VERSION ""

NS_ :

BS_:

BU_: Airbag Allrad EPS Teves_MK60_ESP LWS LWR Teves_MK70_MABS Waehlhebel EPB TRW_ESP ACC_Radar AFS Magne_Ride RKA_Plus Selespeed Waehlhebel_Sele PDC_PLA Lenkhilfe_APA VAQ Daempfer Hybrid_BMS Hybrid_PWR Hybrid_DQ200 EKlimakomp SWA HCA ACC_Lidar Lenkhilfe_ZF_3G FLA AG6 DQ Hybrid_MSG Diesel Otto Gateway_PQ35_A Gateway_PQ46_A Vector_XXX Fzg_CAN

BO_ 1192 mBremse_5: 8 Teves_MK60_ESP
 SG_ BR5_Giergeschw : 0|14@1+ (0.01,0) [0|100] "°/s"  EPB,ACC_Radar,AFS,Magne_Ride,RKA_Plus,Daempfer,HCA,SWA,PDC_PLA,Allrad,ACC_Lidar,FLA
 SG_ BR5_Bremsdruck : 16|12@1+ (0.1,0) [0|409.4] "bar"  DQ,EPB,ACC_Radar,Magne_Ride,Daempfer,Hybrid_DQ200,HCA,ACC_Lidar,PDC_PLA,Diesel,Otto
 SG_ BR5_Sign_Druck : 31|1@1+ (1,0) [0|1] ""  DQ,EPB,ACC_Radar,Magne_Ride,Daempfer,Hybrid_DQ200,HCA,ACC_Lidar,Diesel,Otto
 SG_ BR5_Vorzeichen : 15|1@1+ (1,0) [0|1] ""  EPB,ACC_Radar,AFS,Magne_Ride,RKA_Plus,Daempfer,HCA,SWA,PDC_PLA,Allrad,ACC_Lidar,FLA
 SG_ BR5_Sta_Gierrate : 14|1@1+ (1,0) [0|1] ""  EPB,ACC_Radar,AFS,Magne_Ride,RKA_Plus,Daempfer,HCA,SWA,PDC_PLA,Allrad,ACC_Lidar,FLA
 SG_ BR5_Stillstand : 28|1@1+ (1,0) [0|1] ""  EPB,ACC_Radar,Magne_Ride,Daempfer,HCA,ACC_Lidar
 SG_ BR5_Sta_Druck : 30|1@1+ (1,0) [0|1] ""  EPB,ACC_Radar,Daempfer,HCA,ACC_Lidar
 SG_ BR5_Zaehler : 52|4@1+ (1,0) [0|15] ""  EPB,ACC_Radar,Magne_Ride,Daempfer,HCA,SWA,PDC_PLA,ACC_Lidar
 SG_ BR5_TolAbgl_VR : 32|8@1+ (0.048828125,-6.201171875) [-6.201171875|6.15234375] "%"  ACC_Lidar,HCA,Daempfer,ACC_Radar,EPB
 SG_ BR5_Anhi_akt : 41|1@1+ (1,0) [0|1] ""  EPB,ACC_Radar,Daempfer,HCA,ACC_Lidar
 SG_ BR5_Checksumme : 56|8@1+ (1,0) [0|255] ""  EPB,ACC_Radar,Magne_Ride,Daempfer,HCA,SWA,ACC_Lidar
 SG_ BR5_Druckgueltig : 29|1@1+ (1,0) [0|1] ""  DQ,EPB,ACC_Radar,Magne_Ride,Daempfer,Hybrid_DQ200,HCA,ACC_Lidar,PDC_PLA,Otto,Diesel
 SG_ BR5_ECD_Lampe : 51|1@1+ (1,0) [0|1] ""  ACC_Lidar,HCA,Daempfer,ACC_Radar,EPB
 SG_ BR5_AWV2_Bremsruck : 46|1@1+ (1,0) [0|1] ""  EPB,ACC_Radar,Daempfer,HCA,ACC_Lidar
 SG_ BR5_Anhi_Sta : 40|1@1+ (1,0) [0|1] ""  EPB,ACC_Radar,Daempfer,HCA,ACC_Lidar
 SG_ BR5_Temperatur : 48|3@1+ (125,125) [125|1000] "°"  ACC_Lidar,HCA,Daempfer,ACC_Radar,EPB
 SG_ BR5_v_Ueberw : 42|1@1+ (1,0) [0|1] ""  ACC_Lidar,HCA,Daempfer,ACC_Radar,EPB
 SG_ BR5_AnhStabAktiv : 43|1@1+ (1,0) [0|1] ""  Gateway_PQ46_A,EPB,ACC_Radar,Gateway_PQ35_A,Daempfer,HCA,ACC_Lidar
 SG_ BR5_Notbremsung : 44|1@1+ (1,0) [0|1] ""  Gateway_PQ46_A,EPB,ACC_Radar,Gateway_PQ35_A,Daempfer,HCA,ACC_Lidar
 SG_ BR5_AWV2_Fehler : 47|1@1+ (1,0) [0|1] ""  EPB,ACC_Radar,Daempfer,HCA,ACC_Lidar
 SG_ BR5_ECD_Rueckfall : 45|1@1+ (1,0) [0|1] ""  ACC_Lidar,HCA,Daempfer,ACC_Radar,EPB

BO_ 672 mBremse_4: 8 Teves_MK60_ESP
 SG_ BR4_Vorgabe_Hi m1 : 8|8@1+ (0.7874015748,-100) [0|100] "%"  Gateway_PQ46_A,Gateway_PQ35_A
 SG_ BR4_Einheit M : 16|2@1+ (1,0) [0|1] ""  Gateway_PQ46_A,Allrad,Gateway_PQ35_A,VAQ
 SG_ BR4_Vorgabe_Mi m1 : 0|8@1+ (0.7874015748,-100) [0|100] "%"  Gateway_PQ46_A,Gateway_PQ35_A
 SG_ BR4_Abschaltung_HL : 22|1@1+ (1,0) [0|1] ""  Gateway_PQ46_A,Gateway_PQ35_A
 SG_ BR4_Vorgabe_Mi_ m0 : 0|8@1+ (7,-896) [-896|882] "Nm"  Gateway_PQ46_A,Allrad,Gateway_PQ35_A
 SG_ BR4_Abschaltung_HR : 23|1@1+ (1,0) [0|1] ""  Gateway_PQ46_A,Gateway_PQ35_A
 SG_ BR4_Abschaltung_VL : 20|1@1+ (1,0) [0|1] ""  Gateway_PQ46_A,Gateway_PQ35_A
 SG_ BR4_Abschaltung_VR : 21|1@1+ (1,0) [0|1] ""  Gateway_PQ46_A,Gateway_PQ35_A
 SG_ BR4_Lampe_RKA : 24|1@1+ (1,0) [0|1] ""  Gateway_PQ46_A,Gateway_PQ35_A
 SG_ BR4_Summer_RKA : 25|1@1+ (1,0) [0|1] ""  Gateway_PQ46_A,Gateway_PQ35_A
 SG_ BR4_Unterdruck : 32|8@1+ (4,0) [0|1016] "mbar"  AG6,Gateway_PQ46_A,Otto,Gateway_PQ35_A,Hybrid_MSG
 SG_ BR4_Status_ESP : 40|4@1+ (1,0) [0|15] ""  Gateway_PQ46_A,Gateway_PQ35_A,VAQ
 SG_ BR4_Checksum : 56|8@1+ (1,0) [0|255] ""  Gateway_PQ46_A,Gateway_PQ35_A,VAQ
 SG_ BR4_Reserve2 : 26|6@1+ (1,0) [0|63] ""  Gateway_PQ46_A,Gateway_PQ35_A
 SG_ BR4_Zaehler : 52|4@1+ (1,0) [0|15] ""  Gateway_PQ46_A,Gateway_PQ35_A,VAQ
 SG_ BR4_Schwelle : 18|2@1+ (1,0) [0|3] ""  AG6,Gateway_PQ46_A,Otto,Gateway_PQ35_A,Hybrid_MSG
 SG_ BR4_res_42 : 44|4@1+ (1,0) [0|15] ""  Gateway_PQ46_A,Gateway_PQ35_A
 SG_ BR4_res_48 : 48|4@1+ (1,0) [0|15] ""  Gateway_PQ46_A,Gateway_PQ35_A
 SG_ BR4_Vorgabe_Min m2 : 8|8@1+ (10,0) [0|2540] "Nm"  Gateway_PQ46_A,Gateway_PQ35_A,VAQ
 SG_ BR4_Vorgabe_Max m2 : 0|8@1+ (10,0) [0|2540] "Nm"  Gateway_PQ46_A,Gateway_PQ35_A,VAQ

BO_ 428 mBremse_8: 8 Teves_MK60_ESP
 SG_ BR8_Laengsbeschl : 48|10@1+ (0.03125,-16) [-15.96875|15.9375] "m/s²"  AG6,Diesel,DQ,EPB,ACC_Radar,PDC_PLA,Hybrid_DQ200,Gateway_PQ35_A,ACC_Lidar,Otto
 SG_ BR8_Checksumme : 0|8@1+ (1,0) [0|255] ""  AG6,Diesel,DQ,EPB,ACC_Radar,PDC_PLA,Hybrid_DQ200,Gateway_PQ35_A,ACC_Lidar
 SG_ BR8_Sta_Br_Druck : 15|1@1+ (1,0) [0|1] ""  Diesel,EPB,ACC_Radar,Gateway_PQ35_A,ACC_Lidar
 SG_ BR8_QB_LBeschl : 42|1@1+ (1,0) [0|1] ""  EPB,ACC_Radar,PDC_PLA,Gateway_PQ35_A,ACC_Lidar,Otto,Diesel
 SG_ BR8_Istbeschl : 32|9@1+ (0.02,-7.22) [-7.22|2.98] "m/s²"  Diesel,Otto,EPB,ACC_Radar,Gateway_PQ35_A,ACC_Lidar
 SG_ BR8_Zaehler : 8|4@1+ (1,0) [0|15] ""  AG6,Diesel,EPB,ACC_Radar,PDC_PLA,Gateway_PQ35_A,ACC_Lidar
 SG_ BR8_Check_EPB : 63|1@1+ (1,0) [0|1] ""  EPB,ACC_Radar,Gateway_PQ35_A,ACC_Lidar
 SG_ BR8_TolAbgl_HL : 16|8@1+ (0.048828125,-6.201171875) [-6.201171875|6.15234375] "%"  Gateway_PQ35_A,ACC_Lidar,ACC_Radar,EPB
 SG_ BR8_TolAbgl_HR : 24|8@1+ (0.048828125,-6.201171875) [-6.201171875|6.15234375] "%"  Gateway_PQ35_A,ACC_Lidar,ACC_Radar,EPB
 SG_ BR8_Sta_ADR_BR : 58|1@1+ (1,0) [0|1] ""  Diesel,Otto,EPB,ACC_Radar,Gateway_PQ35_A,ACC_Lidar
 SG_ BR8_Sta_Br_temp : 14|1@1+ (1,0) [0|1] ""  Diesel,EPB,ACC_Radar,Gateway_PQ35_A,ACC_Lidar
 SG_ BR8_Quattro : 59|1@1+ (1,0) [0|1] ""  Gateway_PQ35_A,ACC_Lidar,ACC_Radar,EPB
 SG_ BR8_Sta_ACC_Anf : 12|1@1+ (1,0) [0|1] ""  Diesel,Otto,EPB,ACC_Radar,Gateway_PQ35_A,ACC_Lidar
 SG_ BR8_Verz_EPB_akt : 13|1@1+ (1,0) [0|1] ""  Diesel,EPB,ACC_Radar,Gateway_PQ35_A,ACC_Lidar
 SG_ BR8_aktBrSyst : 45|1@1+ (1,0) [0|1] ""  Diesel,Otto,EPB,ACC_Radar,Gateway_PQ35_A,ACC_Lidar
 SG_ BR8_Sta_VerzReg : 60|1@1+ (1,0) [0|1] ""  Diesel,EPB,ACC_Radar,Gateway_PQ35_A,ACC_Lidar
 SG_ BR8_Fa_bremst : 46|1@1+ (1,0) [0|1] ""  Diesel,EPB,ACC_Radar,Gateway_PQ35_A,ACC_Lidar
 SG_ BR8_Sta_BLS : 61|1@1+ (1,0) [0|1] ""  Gateway_PQ35_A,Diesel,ACC_Lidar,ACC_Radar,EPB
 SG_ BR8_StaBrSyst : 47|1@1+ (1,0) [0|1] ""  Diesel,Otto,EPB,ACC_Radar,Gateway_PQ35_A,ACC_Lidar
 SG_ BR8_ESC_Mode : 43|2@1+ (1,0) [0|3] ""  Gateway_PQ35_A,ACC_Lidar,ACC_Radar,EPB
 SG_ BR8_Verz_EPB : 62|1@1+ (1,0) [0|1] ""  EPB,ACC_Radar,Gateway_PQ35_A,ACC_Lidar
 SG_ BR8_Sta_HW_BLS : 41|1@1+ (1,0) [0|1] ""  Gateway_PQ35_A,ACC_Lidar,ACC_Radar,EPB

BO_ 515 mTP_Er_ABS: 7 Teves_MK60_ESP
 SG_ ABS_TP_Er : 0|56@1+ (1,0) [0|7.2057594038E+016] ""  Gateway_PQ46_A,Gateway_PQ35_A

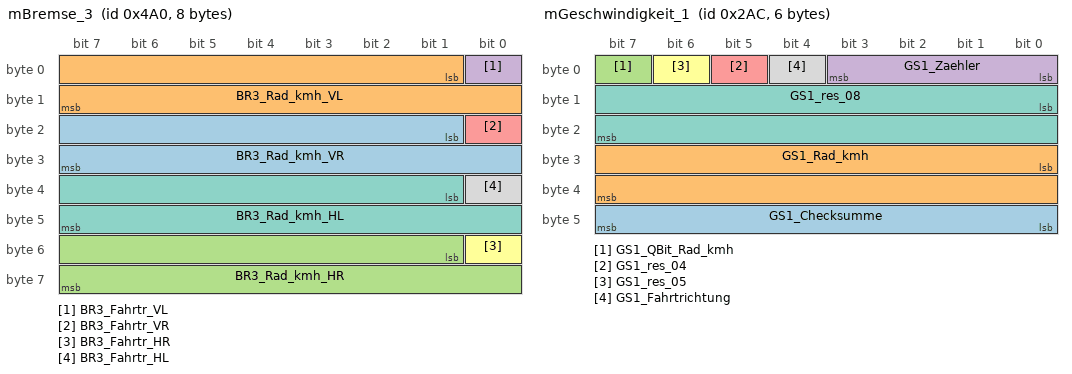
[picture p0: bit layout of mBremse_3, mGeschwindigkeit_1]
BO_ 1184 mBremse_3: 8 Teves_MK60_ESP
 SG_ BR3_Rad_kmh_VR : 17|15@1+ (0.01,0) [0|326.39] "km/h"  AG6,Allrad,Otto,LWS,LWR,DQ,EPB,ACC_Radar,AFS,PDC_PLA,Lenkhilfe_APA,Hybrid_MSG,Hybrid_DQ200,Selespeed,ACC_Lidar,Magne_Ride,EPS,Lenkhilfe_ZF_3G
 SG_ BR3_Rad_kmh_VL : 1|15@1+ (0.01,0) [0|326.39] "km/h"  AG6,Allrad,Otto,LWS,LWR,DQ,EPB,ACC_Radar,AFS,PDC_PLA,Lenkhilfe_APA,Hybrid_MSG,Hybrid_DQ200,Selespeed,ACC_Lidar,Magne_Ride,EPS,Lenkhilfe_ZF_3G
 SG_ BR3_Rad_kmh_HR : 49|15@1+ (0.01,0) [0|326.39] "km/h"  AG6,Allrad,Otto,LWS,LWR,DQ,EPB,ACC_Radar,AFS,PDC_PLA,Lenkhilfe_APA,Hybrid_MSG,Hybrid_DQ200,Selespeed,ACC_Lidar,Magne_Ride,EPS,Lenkhilfe_ZF_3G
 SG_ BR3_Fahrtr_VL : 0|1@1+ (1,0) [0|1] ""  ACC_Lidar,Magne_Ride,ACC_Radar
 SG_ BR3_Fahrtr_VR : 16|1@1+ (1,0) [0|1] ""  ACC_Lidar,Magne_Ride,ACC_Radar
 SG_ BR3_Fahrtr_HR : 48|1@1+ (1,0) [0|1] ""  ACC_Lidar,Magne_Ride,ACC_Radar
 SG_ BR3_Rad_kmh_HL : 33|15@1+ (0.01,0) [0|326.39] "km/h"  AG6,Allrad,Otto,LWS,LWR,DQ,EPB,ACC_Radar,AFS,PDC_PLA,Lenkhilfe_APA,Hybrid_MSG,Hybrid_DQ200,Selespeed,ACC_Lidar,Magne_Ride,Lenkhilfe_ZF_3G,EPS
 SG_ BR3_Fahrtr_HL : 32|1@1+ (1,0) [0|1] ""  ACC_Lidar,Magne_Ride,ACC_Radar

BO_ 174 mBremse_9: 8 Teves_MK60_ESP
 SG_ BR9_res_09 : 9|1@1+ (1,0) [0|1] ""  Lenkhilfe_ZF_3G,Lenkhilfe_APA,EPS
 SG_ BR9_res_10 : 10|1@1+ (1,0) [0|1] ""  Lenkhilfe_ZF_3G,Lenkhilfe_APA,EPS
 SG_ BR9_res_08 : 8|1@1+ (1,0) [0|1] ""  Lenkhilfe_ZF_3G,Lenkhilfe_APA,EPS
 SG_ BR9_Zaehler : 12|4@1+ (1,0) [0|15] ""  EPS,Lenkhilfe_APA,Lenkhilfe_ZF_3G
 SG_ BR9_Checksumme : 0|8@1+ (1,0) [0|255] ""  EPS,Lenkhilfe_APA,Lenkhilfe_ZF_3G
 SG_ BR9_res_52 : 52|1@1+ (1,0) [0|1] ""  Lenkhilfe_ZF_3G,Lenkhilfe_APA,EPS
 SG_ BR9_res_54 : 54|1@1+ (1,0) [0|1] ""  Lenkhilfe_ZF_3G,Lenkhilfe_APA,EPS
 SG_ BR9_res_53 : 53|1@1+ (1,0) [0|1] ""  Lenkhilfe_ZF_3G,Lenkhilfe_APA,EPS
 SG_ BR9_res_55 : 55|1@1+ (1,0) [0|1] ""  Lenkhilfe_ZF_3G,Lenkhilfe_APA,EPS
 SG_ BR9_res_11 : 11|1@1+ (1,0) [0|1] ""  Lenkhilfe_ZF_3G,Lenkhilfe_APA,EPS
 SG_ BR9_LMOffset : 16|15@1+ (0.0003052,0) [0|10.0004884] "Nm"  EPS,Lenkhilfe_APA,Lenkhilfe_ZF_3G
 SG_ BR9_LMOffSign : 31|1@1+ (1,0) [0|1] ""  EPS,Lenkhilfe_APA,Lenkhilfe_ZF_3G
 SG_ BR9_LWOffset : 32|15@1+ (0.04375,0) [0|1433.55625] "°"  EPS,Lenkhilfe_APA,Lenkhilfe_ZF_3G
 SG_ BR9_LWOffSign : 47|1@1+ (1,0) [0|1] ""  EPS,Lenkhilfe_APA,Lenkhilfe_ZF_3G
 SG_ BR9_res_56 : 56|1@1+ (1,0) [0|1] ""  Lenkhilfe_ZF_3G,Lenkhilfe_APA,EPS
 SG_ BR9_res_59 : 59|1@1+ (1,0) [0|1] ""  Lenkhilfe_ZF_3G,Lenkhilfe_APA,EPS
 SG_ BR9_res_60 : 60|1@1+ (1,0) [0|1] ""  Lenkhilfe_ZF_3G,Lenkhilfe_APA,EPS
 SG_ BR9_Sta_DSR : 48|4@1+ (1,0) [0|15] ""  EPS,Lenkhilfe_APA,Lenkhilfe_ZF_3G
 SG_ BR9_res_57 : 57|1@1+ (1,0) [0|1] ""  Lenkhilfe_ZF_3G,Lenkhilfe_APA,EPS
 SG_ BR9_res_63 : 63|1@1+ (1,0) [0|1] ""  Lenkhilfe_ZF_3G,Lenkhilfe_APA,EPS
 SG_ BR9_res_58 : 58|1@1+ (1,0) [0|1] ""  Lenkhilfe_ZF_3G,Lenkhilfe_APA,EPS
 SG_ BR9_res_62 : 62|1@1+ (1,0) [0|1] ""  Lenkhilfe_ZF_3G,Lenkhilfe_APA,EPS
 SG_ BR9_res_61 : 61|1@1+ (1,0) [0|1] ""  Lenkhilfe_ZF_3G,Lenkhilfe_APA,EPS

BO_ 684 mGeschwindigkeit_1: 6 Teves_MK60_ESP
 SG_ GS1_Checksumme : 40|8@1+ (1,0) [0|255] ""  Magne_Ride
 SG_ GS1_Rad_kmh : 24|16@1+ (0.01,0) [0|654.15] "km/h"  Magne_Ride
 SG_ GS1_QBit_Rad_kmh : 7|1@1+ (1,0) [0|1] ""  Magne_Ride
 SG_ GS1_Zaehler : 0|4@1+ (1,0) [0|15] ""  Magne_Ride
 SG_ GS1_res_04 : 5|1@1+ (1,0) [0|1] "" Vector__XXX
 SG_ GS1_res_05 : 6|1@1+ (1,0) [0|1] "" Vector__XXX
 SG_ GS1_res_08 : 8|16@1+ (1,0) [0|65535] "" Vector__XXX
 SG_ GS1_Fahrtrichtung : 4|1@1+ (1,0) [0|1] "" Vector__XXX

BO_ 1986 mLWS_Init: 4 Teves_MK60_ESP
 SG_ LWI_Codierbytes : 8|24@1+ (1,0) [0|16777215] ""  LWS
 SG_ LWI_Init_ID : 0|8@1+ (1,0) [0|255] ""  LWS

BO_ 928 mBremse_10: 8 Teves_MK60_ESP
 SG_ B10_Zaehler : 8|4@1+ (1,0) [0|15] ""  PDC_PLA,Gateway_PQ35_A,Gateway_PQ46_A
 SG_ B10_QB_Wegimp_VL : 12|1@1+ (1,0) [0|1] ""  PDC_PLA,Gateway_PQ35_A,Gateway_PQ46_A
 SG_ B10_QB_Wegimp_VR : 13|1@1+ (1,0) [0|1] ""  PDC_PLA,Gateway_PQ35_A,Gateway_PQ46_A
 SG_ B10_QB_Wegimp_HL : 14|1@1+ (1,0) [0|1] ""  PDC_PLA,Gateway_PQ35_A,Gateway_PQ46_A
 SG_ B10_QB_Wegimp_HR : 15|1@1+ (1,0) [0|1] ""  PDC_PLA,Gateway_PQ35_A,Gateway_PQ46_A
 SG_ B10_Checksumme : 0|8@1+ (1,0) [0|255] ""  PDC_PLA,Gateway_PQ35_A,Gateway_PQ46_A
 SG_ B10_Wegimp_VL : 16|10@1+ (1,0) [0|1000] ""  PDC_PLA,Gateway_PQ35_A,Gateway_PQ46_A
 SG_ B10_Wegimp_VR : 26|10@1+ (1,0) [0|1000] ""  PDC_PLA,Gateway_PQ35_A,Gateway_PQ46_A
 SG_ B10_Wegimp_HL : 36|10@1+ (1,0) [0|1000] ""  PDC_PLA,Gateway_PQ35_A,Gateway_PQ46_A
 SG_ B10_Wegimp_HR : 46|10@1+ (1,0) [0|1000] ""  PDC_PLA,Gateway_PQ35_A,Gateway_PQ46_A
 SG_ B10_QB_Fahrtr_VL : 56|1@1+ (1,0) [0|1] ""  PDC_PLA,Gateway_PQ35_A,Gateway_PQ46_A
 SG_ B10_QB_Fahrtr_HL : 58|1@1+ (1,0) [0|1] ""  PDC_PLA,Gateway_PQ35_A,Gateway_PQ46_A
 SG_ B10_QB_Fahrtr_HR : 59|1@1+ (1,0) [0|1] ""  PDC_PLA,Gateway_PQ35_A,Gateway_PQ46_A
 SG_ B10_Fahrtr_HL : 62|1@1+ (1,0) [0|1] ""  Gateway_PQ46_A,Gateway_PQ35_A,PDC_PLA
 SG_ B10_Fahrtr_HR : 63|1@1+ (1,0) [0|1] ""  Gateway_PQ46_A,Gateway_PQ35_A,PDC_PLA
 SG_ B10_QB_Fahrtr_VR : 57|1@1+ (1,0) [0|1] ""  PDC_PLA,Gateway_PQ35_A,Gateway_PQ46_A
 SG_ B10_Fahrtr_VR : 61|1@1+ (1,0) [0|1] ""  Gateway_PQ46_A,Gateway_PQ35_A,PDC_PLA
 SG_ B10_Fahrtr_VL : 60|1@1+ (1,0) [0|1] ""  Gateway_PQ46_A,Gateway_PQ35_A,PDC_PLA

BO_ 1827 NMH_ABS: 7 Teves_MK60_ESP
 SG_ NMH_ABS_Abschaltstufe_aktiv : 38|1@1+ (1,0) [0|1] "" Vector__XXX
 SG_ NMH_ABS_Car_WakeUp : 6|1@1+ (1,0) [0|1] ""  Gateway_PQ46_A,Gateway_PQ35_A
 SG_ NMH_ABS_Eindraht_Fehler : 39|1@1+ (1,0) [0|1] "" Vector__XXX
 SG_ NMH_ABS_Fkt_WakeUp : 13|3@1+ (1,0) [0|7] "" Vector__XXX
 SG_ NMH_ABS_kein_NL : 24|1@1+ (1,0) [0|1] "" Vector__XXX
 SG_ NMH_ABS_KompSchutz : 35|1@1+ (1,0) [0|1] "" Vector__XXX
 SG_ NMH_ABS_Mute_Mode : 36|1@1+ (1,0) [0|1] "" Vector__XXX
 SG_ NMH_ABS_CAN_Diag_deaktiv : 34|1@1+ (1,0) [0|1] "" Vector__XXX
 SG_ NMH_ABS_NL_1 : 25|1@1+ (1,0) [0|1] "" Vector__XXX
 SG_ NMH_ABS_NL_2 : 26|1@1+ (1,0) [0|1] "" Vector__XXX
 SG_ NMH_ABS_NL_3 : 27|1@1+ (1,0) [0|1] "" Vector__XXX
 SG_ NMH_ABS_NL_4 : 28|1@1+ (1,0) [0|1] "" Vector__XXX
 SG_ NMH_ABS_NL_5 : 29|1@1+ (1,0) [0|1] "" Vector__XXX
 SG_ NMH_ABS_NL_6 : 30|1@1+ (1,0) [0|1] "" Vector__XXX
 SG_ NMH_ABS_NL_7 : 31|1@1+ (1,0) [0|1] "" Vector__XXX
 SG_ NMH_ABS_NL_aktiv_5 : 20|1@1+ (1,0) [0|1] "" Vector__XXX
 SG_ NMH_ABS_NL_aktiv_6 : 21|1@1+ (1,0) [0|1] "" Vector__XXX
 SG_ NMH_ABS_NL_aktiv_7 : 22|1@1+ (1,0) [0|1] "" Vector__XXX
 SG_ NMH_ABS_NL_aktiv_8 : 23|1@1+ (1,0) [0|1] "" Vector__XXX
 SG_ NMH_ABS_NM_aktiv_Diagnose : 17|1@1+ (1,0) [0|1] "" Vector__XXX
 SG_ NMH_ABS_NM_aktiv_Klemme_15 : 16|1@1+ (1,0) [0|1] "" Vector__XXX
 SG_ NMH_ABS_NL_aktiv_4 : 19|1@1+ (1,0) [0|1] "" Vector__XXX
 SG_ NMH_ABS_NM_aktiv_Start : 18|1@1+ (1,0) [0|1] "" Vector__XXX
 SG_ NMH_ABS_Normal_Mode_1 : 2|1@1+ (1,0) [0|1] "" Vector__XXX
 SG_ NMH_ABS_Normal_Mode_2 : 3|1@1+ (1,0) [0|1] "" Vector__XXX
 SG_ NMH_ABS_Per_WakeUp : 8|5@1+ (1,0) [0|31] "" Vector__XXX
 SG_ NMH_ABS_TimeOut_Fehler : 33|1@1+ (1,0) [0|1] "" Vector__XXX
 SG_ NMH_ABS_Transport_Mode : 37|1@1+ (1,0) [0|1] "" Vector__XXX
 SG_ NMH_ABS_Start_1 : 0|1@1+ (1,0) [0|1] ""  Gateway_PQ35_A,Gateway_PQ46_A
 SG_ NMH_ABS_Start_2 : 1|1@1+ (1,0) [0|1] "" Vector__XXX
 SG_ NMH_ABS_res_04 : 4|1@1+ (1,0) [0|1] "" Vector__XXX
 SG_ NMH_ABS_res_05 : 5|1@1+ (1,0) [0|1] "" Vector__XXX
 SG_ NMH_ABS_res_07 : 7|1@1+ (1,0) [0|1] "" Vector__XXX
 SG_ NMH_ABS_res_32 : 32|1@1+ (1,0) [0|1] "" Vector__XXX
 SG_ NMH_ABS_res_40 : 40|1@1+ (1,0) [0|1] "" Vector__XXX
 SG_ NMH_ABS_res_41 : 41|1@1+ (1,0) [0|1] "" Vector__XXX
 SG_ NMH_ABS_res_42 : 42|1@1+ (1,0) [0|1] "" Vector__XXX
 SG_ NMH_ABS_res_43 : 43|1@1+ (1,0) [0|1] "" Vector__XXX
 SG_ NMH_ABS_res_44 : 44|1@1+ (1,0) [0|1] "" Vector__XXX
 SG_ NMH_ABS_res_45 : 45|1@1+ (1,0) [0|1] "" Vector__XXX
 SG_ NMH_ABS_res_46 : 46|1@1+ (1,0) [0|1] "" Vector__XXX
 SG_ NMH_ABS_res_47 : 47|1@1+ (1,0) [0|1] "" Vector__XXX
 SG_ NMH_ABS_res_48 : 48|1@1+ (1,0) [0|1] "" Vector__XXX
 SG_ NMH_ABS_res_49 : 49|1@1+ (1,0) [0|1] "" Vector__XXX
 SG_ NMH_ABS_res_50 : 50|1@1+ (1,0) [0|1] "" Vector__XXX
 SG_ NMH_ABS_res_51 : 51|1@1+ (1,0) [0|1] "" Vector__XXX
 SG_ NMH_ABS_res_52 : 52|1@1+ (1,0) [0|1] "" Vector__XXX
 SG_ NMH_ABS_res_53 : 53|1@1+ (1,0) [0|1] "" Vector__XXX
 SG_ NMH_ABS_res_54 : 54|1@1+ (1,0) [0|1] "" Vector__XXX
 SG_ NMH_ABS_res_55 : 55|1@1+ (1,0) [0|1] "" Vector__XXX

BO_ 1463 mBremse_11: 8 Teves_MK60_ESP
 SG_ B11_res_00 : 0|8@1+ (1,0) [0|1] "" Vector__XXX
 SG_ B11_res_08 : 8|4@1+ (1,0) [0|1] "" Vector__XXX
 SG_ B11_Br_StSt_Info : 14|2@1+ (1,0) [0|3] ""  Diesel,Otto
 SG_ B11_OBD_Nib_VL : 16|4@1+ (1,0) [0|15] ""  Diesel,Otto
 SG_ B11_OBD_Nib_VR : 20|4@1+ (1,0) [0|15] ""  Diesel,Otto
 SG_ B11_OBD_Nib_HL : 24|4@1+ (1,0) [0|15] ""  Diesel,Otto
 SG_ B11_OBD_Nib_HR : 28|4@1+ (1,0) [0|15] ""  Diesel,Otto
 SG_ B11_HydHalten : 13|1@1+ (1,0) [0|1] ""  Diesel,Otto
 SG_ B11_res_12 : 12|1@1+ (1,0) [0|1] "" Vector__XXX
 SG_ B11_EPB_Steller_akt : 32|1@1+ (1,0) [0|1] ""  Otto,Diesel
 SG_ B11_EPB_Steller_gue : 33|1@1+ (1,0) [0|1] ""  Diesel,Otto
 SG_ B11_res_34 : 34|1@1+ (1,0) [0|1] "" Vector__XXX
 SG_ B11_res_35 : 35|1@1+ (1,0) [0|1] "" Vector__XXX
 SG_ B11_res_36 : 36|1@1+ (1,0) [0|1] "" Vector__XXX
 SG_ B11_res_37 : 37|1@1+ (1,0) [0|1] "" Vector__XXX
 SG_ B11_res_38 : 38|1@1+ (1,0) [0|1] "" Vector__XXX
 SG_ B11_res_39 : 39|1@1+ (1,0) [0|1] "" Vector__XXX
 SG_ B11_res_40 : 40|1@1+ (1,0) [0|1] "" Vector__XXX
 SG_ B11_res_41 : 41|1@1+ (1,0) [0|1] "" Vector__XXX
 SG_ B11_res_42 : 42|1@1+ (1,0) [0|1] "" Vector__XXX
 SG_ B11_res_43 : 43|1@1+ (1,0) [0|1] "" Vector__XXX
 SG_ B11_res_44 : 44|1@1+ (1,0) [0|1] "" Vector__XXX
 SG_ B11_res_45 : 45|1@1+ (1,0) [0|1] "" Vector__XXX
 SG_ B11_res_46 : 46|1@1+ (1,0) [0|1] "" Vector__XXX
 SG_ B11_res_47 : 47|1@1+ (1,0) [0|1] "" Vector__XXX
 SG_ B11_res_48 : 48|1@1+ (1,0) [0|1] "" Vector__XXX
 SG_ B11_res_49 : 49|1@1+ (1,0) [0|1] "" Vector__XXX
 SG_ B11_res_50 : 50|1@1+ (1,0) [0|1] "" Vector__XXX
 SG_ B11_res_51 : 51|1@1+ (1,0) [0|1] "" Vector__XXX
 SG_ B11_res_52 : 52|1@1+ (1,0) [0|1] "" Vector__XXX
 SG_ B11_res_53 : 53|1@1+ (1,0) [0|1] "" Vector__XXX
 SG_ B11_res_54 : 54|1@1+ (1,0) [0|1] "" Vector__XXX
 SG_ B11_res_55 : 55|1@1+ (1,0) [0|1] "" Vector__XXX
 SG_ B11_res_56 : 56|1@1+ (1,0) [0|1] "" Vector__XXX
 SG_ B11_res_57 : 57|1@1+ (1,0) [0|1] "" Vector__XXX
 SG_ B11_res_58 : 58|1@1+ (1,0) [0|1] "" Vector__XXX
 SG_ B11_res_59 : 59|1@1+ (1,0) [0|1] "" Vector__XXX
 SG_ B11_res_61 : 61|1@1+ (1,0) [0|1] "" Vector__XXX
 SG_ B11_res_62 : 62|1@1+ (1,0) [0|1] "" Vector__XXX
 SG_ B11_res_63 : 63|1@1+ (1,0) [0|1] "" Vector__XXX
 SG_ B11_res_60 : 60|1@1+ (1,0) [0|1] "" Vector__XXX

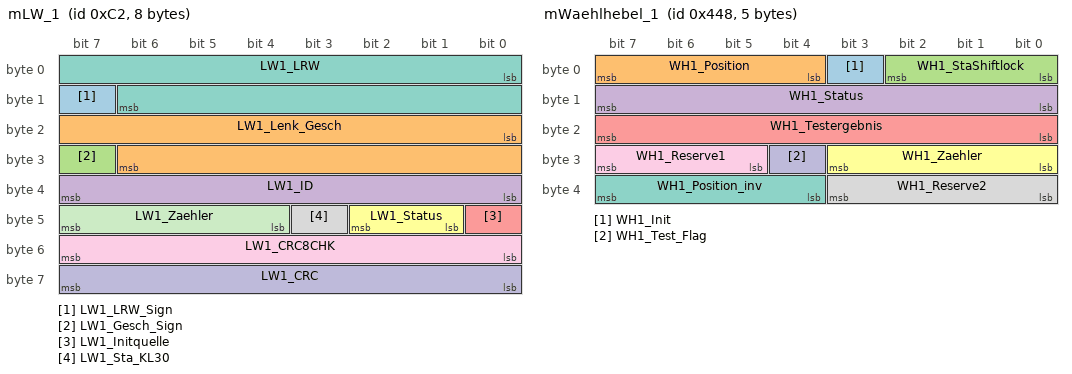
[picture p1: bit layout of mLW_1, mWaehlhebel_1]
BO_ 194 mLW_1: 8 LWS
 SG_ LW1_LRW_Sign : 15|1@1+ (1,0) [0|1] ""  Gateway_PQ46_A,Allrad,EPS,Otto,Teves_MK60_ESP,LWR,TRW_ESP,ACC_Radar,AFS,Gateway_PQ35_A,Magne_Ride,RKA_Plus,Lenkhilfe_APA,Daempfer,Hybrid_MSG,HCA,ACC_Lidar,Diesel
 SG_ LW1_Lenk_Gesch : 16|15@1+ (0.04375,0) [0|1433.55625] "°/s"  Gateway_PQ46_A,EPS,Otto,Teves_MK60_ESP,LWR,ACC_Radar,AFS,Gateway_PQ35_A,Magne_Ride,Lenkhilfe_APA,Hybrid_MSG,TRW_ESP,Daempfer,HCA,ACC_Lidar
 SG_ LW1_Gesch_Sign : 31|1@1+ (1,0) [0|1] ""  Gateway_PQ46_A,EPS,Otto,Teves_MK60_ESP,LWR,ACC_Radar,AFS,Gateway_PQ35_A,Magne_Ride,Lenkhilfe_APA,Hybrid_MSG,TRW_ESP,Daempfer,HCA,ACC_Lidar
 SG_ LW1_ID : 32|8@1+ (1,0) [0|255] ""  Gateway_PQ46_A,EPS,Teves_MK60_ESP,LWR,TRW_ESP,AFS,Gateway_PQ35_A,Magne_Ride,Lenkhilfe_APA
 SG_ LW1_Initquelle : 40|1@1+ (1,0) [0|1] ""  Gateway_PQ46_A,EPS,Teves_MK60_ESP,LWR,TRW_ESP,ACC_Radar,AFS,Gateway_PQ35_A,Lenkhilfe_APA,Daempfer,HCA,ACC_Lidar
 SG_ LW1_Status : 41|2@1+ (1,0) [0|3] ""  Gateway_PQ46_A,EPS,Otto,Teves_MK60_ESP,LWR,DQ,TRW_ESP,ACC_Radar,AFS,Gateway_PQ35_A,Magne_Ride,RKA_Plus,Lenkhilfe_APA,Daempfer,Hybrid_MSG,Hybrid_DQ200,HCA,Allrad,ACC_Lidar
 SG_ LW1_LRW : 0|15@1+ (0.04375,0) [0|1433.55625] "°"  Gateway_PQ46_A,Allrad,EPS,Otto,Teves_MK60_ESP,LWR,DQ,TRW_ESP,ACC_Radar,AFS,Gateway_PQ35_A,Magne_Ride,RKA_Plus,Lenkhilfe_APA,Daempfer,Hybrid_MSG,Hybrid_DQ200,HCA,ACC_Lidar,Diesel
 SG_ LW1_Sta_KL30 : 43|1@1+ (1,0) [0|1] ""  Gateway_PQ46_A,Teves_MK60_ESP,LWR,TRW_ESP,ACC_Radar,AFS,Gateway_PQ35_A,Magne_Ride,Lenkhilfe_APA,Daempfer,HCA,ACC_Lidar
 SG_ LW1_CRC8CHK : 48|8@1+ (1,0) [0|255] ""  Gateway_PQ46_A,Gateway_PQ35_A,Lenkhilfe_APA
 SG_ LW1_CRC : 56|8@1+ (1,0) [0|255] ""  Gateway_PQ46_A,Teves_MK60_ESP,LWR,TRW_ESP,ACC_Radar,AFS,Gateway_PQ35_A,Magne_Ride,Lenkhilfe_APA,Daempfer,HCA,ACC_Lidar
 SG_ LW1_Zaehler : 44|4@1+ (1,0) [0|15] ""  Gateway_PQ46_A,Teves_MK60_ESP,LWR,TRW_ESP,ACC_Radar,AFS,Gateway_PQ35_A,Magne_Ride,Lenkhilfe_APA,Daempfer,HCA,ACC_Lidar

BO_ 531 mTP_Er_LWS: 7 LWS
 SG_ LWS_TP_Er : 0|56@1+ (1,0) [0|7.2057594038E+016] ""  Gateway_PQ46_A,Gateway_PQ35_A

BO_ 518 mTP_Er_Dyn_LWR: 7 LWR
 SG_ Dyn_LWR_TP_Er : 0|56@1+ (1,0) [0|7.2057594038E+016] ""  Gateway_PQ46_A,Gateway_PQ35_A

BO_ 916 mLWR_Zustand: 8 LWR
 SG_ LRZ_Grundeinst : 1|1@1+ (1,0) [0|1] ""  Gateway_PQ46_A,Gateway_PQ35_A
 SG_ LRZ_Initlauf : 3|1@1+ (1,0) [0|1] ""  Gateway_PQ46_A,Gateway_PQ35_A
 SG_ LRZ_Einfedg_hi : 16|8@1+ (1,-127) [-127|126] "mm"  Gateway_PQ46_A,Gateway_PQ35_A
 SG_ LRZ_Fehlerlampe : 6|1@1+ (1,0) [0|1] ""  Gateway_PQ46_A,Gateway_PQ35_A
 SG_ LRZ_Einfedg_vo : 8|8@1+ (1,-127) [-127|126] "mm"  Gateway_PQ46_A,Gateway_PQ35_A
 SG_ LRZ_Sichere_Pos : 4|1@1+ (1,0) [0|1] ""  Gateway_PQ46_A,Gateway_PQ35_A
 SG_ LRZ_Stellung : 24|8@1+ (0.4,0) [0|100] "%"  Gateway_PQ46_A,Gateway_PQ35_A
 SG_ LRZ_Fehler : 7|1@1+ (1,0) [0|1] ""  Gateway_PQ46_A,Gateway_PQ35_A
 SG_ LRZ_Modus : 2|1@1+ (1,0) [0|1] ""  Gateway_PQ46_A,Gateway_PQ35_A
 SG_ LRZ_LampeAFS : 5|1@1+ (1,0) [0|1] ""  Gateway_PQ46_A,Gateway_PQ35_A
 SG_ LRZ_Parameter : 0|1@1+ (1,0) [0|1] ""  Gateway_PQ46_A,Gateway_PQ35_A
 SG_ LRZ_res_48 : 48|8@1+ (1,0) [0|255] ""  Gateway_PQ46_A,Gateway_PQ35_A
 SG_ LRZ_Tourist_Fkt : 44|1@1+ (1,0) [0|1] ""  Gateway_PQ46_A,Gateway_PQ35_A
 SG_ LRZ_ELF_links : 40|1@1+ (1,0) [0|1] ""  Gateway_PQ46_A,Gateway_PQ35_A
 SG_ LRZ_ELF_rechts : 41|1@1+ (1,0) [0|1] ""  Gateway_PQ46_A,Gateway_PQ35_A
 SG_ LRZ_LeistDim : 32|8@1+ (0.4,50) [50|150] "%"  Gateway_PQ46_A,Gateway_PQ35_A
 SG_ LRZ_AFSLED_Blink : 42|1@1+ (1,0) [0|1] ""  Gateway_PQ46_A,Gateway_PQ35_A
 SG_ LRZ_AFSFehlertext : 43|1@1+ (1,0) [0|1] ""  Gateway_PQ46_A,Gateway_PQ35_A
 SG_ LRZ_Zaehler : 60|4@1+ (1,0) [0|15] ""  Gateway_PQ46_A,Gateway_PQ35_A
 SG_ LRZ_res_56 : 56|4@1+ (1,0) [0|15] ""  Gateway_PQ46_A,Gateway_PQ35_A
 SG_ LRZ_AFS_Absch : 46|1@1+ (1,0) [0|1] ""  Gateway_PQ35_A,Gateway_PQ46_A
 SG_ LRZ_AFS_deaktiv : 47|1@1+ (1,0) [0|1] ""  Gateway_PQ35_A,Gateway_PQ46_A
 SG_ LRZ_Tourist_aktiv : 45|1@1+ (1,0) [0|1] ""  Gateway_PQ35_A,Gateway_PQ46_A

BO_ 1096 mWaehlhebel_1: 5 Waehlhebel
 SG_ WH1_Init : 3|1@1+ (1,0) [0|1] ""  DQ,Hybrid_DQ200
 SG_ WH1_Position : 4|4@1+ (1,0) [0|15] ""  DQ,Hybrid_DQ200
 SG_ WH1_StaShiftlock : 0|3@1+ (1,0) [0|7] ""  DQ,Hybrid_DQ200
 SG_ WH1_Status : 8|8@1+ (1,0) [0|255] ""  DQ,Hybrid_DQ200
 SG_ WH1_Testergebnis : 16|8@1+ (1,0) [0|255] ""  DQ,Hybrid_DQ200
 SG_ WH1_Zaehler : 24|4@1+ (1,0) [0|15] ""  DQ,Hybrid_DQ200
 SG_ WH1_Position_inv : 36|4@1+ (1,0) [0|15] ""  DQ,Hybrid_DQ200
 SG_ WH1_Reserve2 : 32|4@1+ (1,0) [0|15] "" Vector__XXX
 SG_ WH1_Reserve1 : 29|3@1+ (1,0) [0|7] "" Vector__XXX
 SG_ WH1_Test_Flag : 28|1@1+ (1,0) [0|1] ""  DQ,Hybrid_DQ200

BO_TX_BU_ 1192 : TRW_ESP,Teves_MK70_MABS,Teves_MK60_ESP;
BO_TX_BU_ 672 : TRW_ESP,Teves_MK70_MABS,Teves_MK60_ESP;
BO_TX_BU_ 428 : TRW_ESP,Teves_MK60_ESP;
BO_TX_BU_ 515 : TRW_ESP,Teves_MK70_MABS,Teves_MK60_ESP;
BO_TX_BU_ 1184 : TRW_ESP,Teves_MK70_MABS,Teves_MK60_ESP;
BO_TX_BU_ 174 : TRW_ESP,Teves_MK60_ESP;
BO_TX_BU_ 1986 : TRW_ESP,Teves_MK70_MABS,Teves_MK60_ESP;
BO_TX_BU_ 928 : TRW_ESP,Teves_MK70_MABS,Teves_MK60_ESP;
BO_TX_BU_ 1827 : TRW_ESP,Teves_MK70_MABS,Teves_MK60_ESP;
BO_TX_BU_ 1463 : TRW_ESP,Teves_MK60_ESP;
BO_TX_BU_ 194 : Lenkhilfe_ZF_3G,LWS;
BO_TX_BU_ 518 : AFS,LWR;
BO_TX_BU_ 916 : AFS,LWR;
CM_ SG_ 1192 BR5_Giergeschw "Giergeschwindigkeit
Low Byte 1, High Byte 2 ; nicht offsetkorrigierte, gemessene Giergeschwindigkeit ; tatsächliche Auflösung Bosch ESP: 0,27 Grad/sDie Werte 3FFDH und 3FFEH zur Systemidentifikation kommen nur, wenn Gierrate ungültig (Byte 2, Bit 6) gesetzt ist.";
CM_ SG_ 1192 BR5_Bremsdruck "Bremsdruck (Bremse 5)
Realer Meßbereich 0...170 barLow Byte 1, High Byte 2, aktueller nicht offsetkorrigierter Bremsdruck im Hauptbremszylinder (ungefiltert) ";
CM_ SG_ 1192 BR5_Sign_Druck "Vorzeichen Bremsdruck
 ";
CM_ SG_ 1192 BR5_Vorzeichen "Vorzeichen der Giergeschwindigkeit
Linkskurve positiv, Rechtskurve negativ!";
CM_ SG_ 1192 BR5_Sta_Gierrate "Gierrate ungültig
keine Filterung; ungültiger Wert kann z.B. aufgrund einer Unterspannung oder in der Initialisierungsphase ausgegeben werden ";
CM_ SG_ 1192 BR5_Stillstand "Stillstand-Flag
Fahrzeug steht (Algorithmus im Bremsensteuergerät)im PQ35/46 alle 4 Radgeschwindigkeiten 0";
CM_ SG_ 1192 BR5_Sta_Druck "Status Bremsdruck durch ESP-System (Bremse 5)
Zur Plausibilisierung: Bremsdruck wird vom ESP aufgebaut (z.B. Vorladepumpe). Nachlauf muß vom Empfänger berücksichtigt werden. ; Bei RB ESP 5.7, ESP 8,  CT Mk60, MK25A XT und TRW EBC440 wird immer 0 ausgegeben, weil Drucksignal am Hauptbremszylinder nicht von Vorladepumpe kommen kann";
CM_ SG_ 1192 BR5_Zaehler "Zähler (Bremse 5)
Überlaufender Botschaftszähler, zur Lebenderkennung";
CM_ SG_ 1192 BR5_TolAbgl_VR "Reifentoleranzabgleich VR
Physikalischer Wertebereich: +/-5%der Reifentoleranzabgleich bezieht sich auf das linke Vorderrad (nicht VW D1, D1GP, BY61x, PQ35/46, Colorado GP, T5GP, RPU (Wert 0 wird gesendet))";
CM_ SG_ 1192 BR5_Anhi_akt "Anfahrhilfe aktiv
Anfahrhilfe (aktiver Bremsbooster) wird angesteuert (bisher nur Colorado/Colorado GP/T5/T5GP/RPU/TTNF, nicht PQ35/46)";
CM_ SG_ 1192 BR5_Checksumme "Checksumme (Bremse 5)
Prüfsumme, Definition im CAN-Lastenheft";
CM_ SG_ 1192 BR5_Druckgueltig "Bremsdruck ungültig
 ";
CM_ SG_ 1192 BR5_ECD_Lampe "Bremslicht ECD
Bremslichtansteuerung durch ECD-Funktion (nicht PQ35/46)";
CM_ SG_ 1192 BR5_AWV2_Bremsruck "Rückmeldung Bremsruck AWV2
Rückmeldung Bremse ans AWV: Von AWV2 angefordeter Bremsruck wird aktuell durchgeführt. (im AU716 und Touareg GP, PQ46 ab 45/08,  nicht D1GP/BY61x)";
CM_ SG_ 1192 BR5_Anhi_Sta "Anfahrhilfe Fehlerstatus
Bei gesetztem Fehler steht die Anfahrhilfe nicht zur Verfügung (bisher nur Colorado/Colorado GP/T5/T5GP/RPU/TTNF, nicht PQ35/46)";
CM_ SG_ 1192 BR5_Temperatur "Bremsentemperatur
Aus Modell errechnet (nicht PQ35/46)";
CM_ SG_ 1192 BR5_v_Ueberw "Geschwindigkeitsüberwachung
Funktion Geschwindigkeitsüberwachung ist aktuell verfügbar (Getriebe_1-Bits werden beachtet) (nur im Colorado)";
CM_ SG_ 1192 BR5_AnhStabAktiv "Gespannstabilisierung aktiv
wenn Gespannstabilisierungs-Regelung zu einer Verzögerung führt, wird das Bit gesetzt: im Colorado zusätzlich zum Hardware-ausgang, in PQ35 / PQ46 ohne Hardware-Ausgang (nicht D1GP/BY61x)Wird im T5GP und RPU umgesetzt für Bremslicht-Ansteuerung.";
CM_ SG_ 1192 BR5_Notbremsung "Notbremsanzeige
Automatische Aktivierung des Warnblinkers und Bremsflächenvergrößerung bei Notbremsung. Funktion im ESP8 & ILM-Hinten ab Audi C6 erstmalig implementiert. (nicht PQ46) (nicht D1GP/BY61x)";
CM_ SG_ 1192 BR5_AWV2_Fehler "AWV2 Fehler
Meldung an die Funktion AWV2 (z. Z. auf ACC-SG) wenn das ESP-SG einen Kommunikationsfehler oder unplausible Daten feststellt (Touareg GP und PQ46 ab 45/08, nicht D1GP/BY61x)";
CM_ SG_ 1192 BR5_ECD_Rueckfall "Rückfallebene ECD
z. Zt. nur Audi C6: Bit wird gesetzt, wenn das ESP einen Hardwarefehler (Drucksensor) erkannt hat; im Fehlerfall wird das interne Druckmodell herangezogenFolge: unkomfortableres ACC (nicht PQ35/46) (nicht D1GP/BY61x)";
CM_ SG_ 672 BR4_Vorgabe_Hi "ABS-Vorgabewert für Kupplungssteifigkeit hinten
Einheit der Kupplungssteifigkeit ist 1 (Prozente) ; nur im Colorado/Touareg GP";
CM_ SG_ 672 BR4_Einheit "Einheit Kupplungswert (Bremse 4)
Die Einheit und der Wertebereich in Byte 1 und 2 wird mit diesem Bit gekennzeichnet (z.B. zur Verbaukontrolle nutzbar): 0: Nm (Haldex); 1:  Normierung auf 0..100%; 2: Nm (VAQ)";
CM_ SG_ 672 BR4_Vorgabe_Mi "ABS-Vorgabewert für Kupplungssteifigkeit Mitte
Einheit der Kupplungssteifigkeit ist 1 (Prozente) ; nicht PQ35/46";
CM_ SG_ 672 BR4_Abschaltung_HL "EDS-Abschaltung HL
Temperaturabschaltung ; nicht VW";
CM_ SG_ 672 BR4_Vorgabe_Mi_ "Kupplungsmoment
Einheit Kupplungswert ist 0.Vorgabe für das Kupplungsmoment vom Bremsen Steuergerät an die Allradkupplung,  ; 'Kupplung schnell offen heißt, daß der Befehl ohne Rampe sofort ausgeführt werden muß; ; der Arbeitsbereich geht von 0 (=80H) Nm (Kupplung gesteuert offen) bis  ; 882 (=FEH) Nm; ; negativer Wertebereich praktisch nicht möglichACHTUNG im T5GP noch alte Auflösung 0-378 Nm";
CM_ SG_ 672 BR4_Abschaltung_HR "EDS-Abschaltung HR
Temperaturabschaltung ; nicht VW";
CM_ SG_ 672 BR4_Abschaltung_VL "EDS-Abschaltung VL
Temperaturabschaltung ; nicht VW";
CM_ SG_ 672 BR4_Abschaltung_VR "EDS-Abschaltung VR
Temperaturabschaltung ; nicht VW";
CM_ SG_ 672 BR4_Lampe_RKA "Warnlampe RKA
Warnlampe Reifen-Kontroll-Anzeige (Software im Bremsensteuergerät)z.Zt. nur bei Contiteves PQ35(zukünftig in Bremse_2)";
CM_ SG_ 672 BR4_Summer_RKA "Summer RKA
Summer zur Reifen-Kontroll-Anzeige wird nach Setzen des Bits für eine Sekunde angesteuertz. Zt. nur bei Contiteves PQ35(zukünftig in Bremse_2)";
CM_ SG_ 672 BR4_Unterdruck "Unterdruck
der maximale Wert wird auf 1016 mbar begrenztEs ist der Initwert zu senden, wenn der Unterdruckschwellwert (Byte 3, Bit 3,2) auf 00 (kein Signal) steht, weil das ESP nicht über einen Unterdrucksensor verfügt.(Nur für HBV-Regler PQ35 und TRW-HBV-Regler PQ46)";
CM_ SG_ 672 BR4_Status_ESP "Statusmaschine: ESP Status
Statusmaschine (für VAQ im PQ35)";
CM_ SG_ 672 BR4_Checksum "Checksumme
Prüfsumme, Definition im CAN-Lastenheft";
CM_ SG_ 672 BR4_Reserve2 " 
 ";
CM_ SG_ 672 BR4_Zaehler "Zähler
Überlaufender Botschaftszähler, zur Lebenderkennung";
CM_ SG_ 672 BR4_Schwelle "Unterdruckschwellwert
Byte 5 (BKV-Unterdruck) wird nur von speziellem HBV-Regler ausgegeben";
CM_ SG_ 672 BR4_res_42 " 
 ";
CM_ SG_ 672 BR4_res_48 " 
Reserviert für Botschaftsspiegel (für VAQ im PQ35)";
CM_ SG_ 672 BR4_Vorgabe_Min "Vorgabewert für Kupplung Min
Einheit Kupplungswert ist 2.Min. Vorgabegrenzwert des Arbeitsbereiches der Kupplung durch das ESP (nur im PQ35 mit VAQ)";
CM_ SG_ 672 BR4_Vorgabe_Max "Vorgabewert für Kupplung Max
Einheit Kupplungswert ist 2.Max. Vorgabegrenzwert des Arbeitsbereiches der Kupplung durch das ESP (nur im PQ35 mit VAQ)";
CM_ SG_ 428 BR8_Laengsbeschl "Längsbeschleunigung
Längsbeschleunigung (nur im Colorado und PQ35 ausstattungsabhängig (z.B. Allrad)): Sensorwert, im PQ46 Rohwert, im PQ35 kein Rohwert";
CM_ SG_ 428 BR8_Checksumme "Checksumme (Bremse 8)
Prüfsumme, Definition im CAN-Lastenheft";
CM_ SG_ 428 BR8_Sta_Br_Druck "Status Bremsdruck
bei gesetztem Bit liegt p > ca. 2 bar an,  hervorgerufen durch Fahrer, ASR, FZR, ECD, Bremsenregler...bei Abfall des Bits ist p < X bar, bei aktivem ECD-Eingriff Ende des Eingriffs (für den PQ46 noch in Klärung)";
CM_ SG_ 428 BR8_QB_LBeschl "Qualifizierungsbit Längsbeschleunigung
Definition nach CAN-Lastenheft ";
CM_ SG_ 428 BR8_Istbeschl "Fahrzeugbeschleunigung
Fahrzeugbeschleunigung als Referenzwert für ACC (abgeleitet aus der Geschwindigkeit, die in Bremse 1 übertragen wird) (nur für Überwachungszwecke)";
CM_ SG_ 428 BR8_Zaehler "Zähler (Bremse 8)
Überlaufender Botschaftszähler, zur Lebenderkennung";
CM_ SG_ 428 BR8_Check_EPB "EPB Botschaft plausibel
Bei nicht gesetzten Bit wird die EPB Botschaft nicht empfangen oder Inhalt ist unplausibel, (Checksumme, Botschaftszähler)";
CM_ SG_ 428 BR8_TolAbgl_HL "Reifentoleranzabgleich Rad HL
Physikalischer Wertebereich: +/-5%der Reifentoleranzabgleich bezieht sich auf das linke Vorderrad";
CM_ SG_ 428 BR8_TolAbgl_HR "Reifentoleranzabgleich Rad HR
Physikalischer Wertebereich: +/-5%der Reifentoleranzabgleich bezieht sich auf das linke Vorderrad";
CM_ SG_ 428 BR8_Sta_ADR_BR "Konsistenz ACC Botschaft
Rueckmeldung zum ACC bezueglich Pruefung der Checksumme, des Botschaftszaehlers und des langen Timeout der ACC-1 Botschaft. Wird gesetzt bei ACC-Verzoegerungsanforderungen groesser einer applizierbaren Schwelle. (bei Audi GRA+ Rückmeldung zum Motor) (bei VW: Rückmeldung zum Motor; Prüfung auf Motor_Bremse-Botschaft)";
CM_ SG_ 428 BR8_Sta_Br_temp "Status Bremse Bremstemperatur
ECD-Bremsscheibentemperaturmodell Reaktion durch ACC, GRA od. EPB";
CM_ SG_ 428 BR8_Quattro "Quattroantrieb
Information darüber, ob das Fahrzeug Front- oder Allradantrieb (Quattro) hat";
CM_ SG_ 428 BR8_Sta_ACC_Anf "Status Bremse ACC-Anforderung
gültige ACC-Anforderung zur Verzögerungsrege-lung ECD / Bremsenregelung wird ausgeführt: Druckaufbau über Standby hinaus (im PQ46 aus Motor_Bremse) (nur bei Audi auch GRA+-Anforderung möglich)";
CM_ SG_ 428 BR8_Verz_EPB_akt "Verzögerung durch EPB aktiviert
Bei gesetzten Bit wird Verzögerungswunsch von EPB umgesetzt.";
CM_ SG_ 428 BR8_aktBrSyst "Aktives Bremssystem
Bremssystem kann aufgrund einer externen Anforderung (z.B. Motor_Bremse) aktiv bremsen";
CM_ SG_ 428 BR8_Sta_VerzReg "Status Verzögerungsregler
ESP kann die Verzögerungsregelung / Bremsenregelung nicht ausführen";
CM_ SG_ 428 BR8_Fa_bremst "Fahrer bremst
Fahrer bremst bzw. bremst stärker als aktives Bremssystem (nur benötigt für aktive Bremssysteme, die das Bremspedal mitziehen) Nur im Porsche Cayenne wird das Bit auch bei Gespannstabilisierungseingriff gesetzt.";
CM_ SG_ 428 BR8_Sta_BLS "Status BLS
ESP hat Fehler in der Erfassung des Bremslichtschalters erkannt";
CM_ SG_ 428 BR8_StaBrSyst "Status aktives Bremssystem
Aktives Bremssystem setzt Anforderungen von externem System (Andocken/ Standby oder Verzögerung) um";
CM_ SG_ 428 BR8_ESC_Mode "ESC Mode
Anzeige ´ESC Mode´ (ESP-Modus) nur im MY10 Bentley-Kombi(war ´AWV1 Basisparametersatz HBA´ Rückmeldung des aktuell codierten Parametersatzes ans ACC nur Audi C6/AU716)";
CM_ SG_ 428 BR8_Verz_EPB "Verzögerung für EPB verfügbar
Bei gesetzten Bit ist der Verzögerungsregler für EPB verfügbar.";
CM_ SG_ 428 BR8_Sta_HW_BLS "Status Hardware BLS-Ausgang
Endstufe Bremslichtschalter-Ausgang defekt";
CM_ SG_ 515 ABS_TP_Er "TP 2.0 Eroeffnungskanal
 ";
CM_ SG_ 1184 BR3_Rad_kmh_VR "Radgeschw. VR
Low Byte 3, High Byte 4 (Auflösung 1,28 km/h);  ; Radgeschwindigkeit bezieht sich auf den 'Kombi 3 ReifenumfangKonstanten:V_INIT =  7FC4H  (bzw. FF88H oder FF89H = 1111 1111 1000 100x B in 2-Byte-Schreibweise) (entspricht 327,08 km/h) (nicht Colorado, D1GP/BY61x)V_INIT = 0 (im Colorado, D1GP/BY61x)V_Uspg =  7FD5H (bzw. FFAAH oder FFABH = 1111 1111 1010 101x B in 2-Byte-Schreibweise) (entspricht 327,25 km/h) (nicht D1GP/BY61x)V_Fehler = 7FE6H (bzw. FFCCH oder FFCDH = 1111 1111 1100 110x B in";
CM_ SG_ 1184 BR3_Rad_kmh_VL "Radgeschw. VL
Low Byte 1, High Byte 2 (Auflösung 1,28 km/h);  ; Radgeschwindigkeit bezieht sich auf den 'Kombi 3 ReifenumfangKonstanten:V_INIT =  7FC4H  (bzw. FF88H oder FF89H = 1111 1111 1000 100x B in 2-Byte-Schreibweise) (entspricht 327,08 km/h) (nicht Colorado, D1GP/BY61x)V_INIT = 0 (im Colorado, D1GP/BY61x)V_Uspg =  7FD5H (bzw. FFAAH oder FFABH = 1111 1111 1010 101x B in 2-Byte-Schreibweise) (entspricht 327,25 km/h) (nicht D1GP/BY61x)V_Fehler = 7FE6H (bzw. FFCCH oder FFCDH = 1111 1111 1100 110x B in";
CM_ SG_ 1184 BR3_Rad_kmh_HR "Radgeschw. HR
Low Byte 7, High Byte 8 (Auflösung 1,28 km/h);  ; Radgeschwindigkeit bezieht sich auf den 'Kombi 3 ReifenumfangKonstanten:V_INIT =  7FC4H  (bzw. FF88H oder FF89H = 1111 1111 1000 100x B in 2-Byte-Schreibweise) (entspricht 327,08 km/h) (nicht Colorado, D1GP/BY61x)V_INIT = 0 (im Colorado, D1GP/BY61x)V_Uspg =  7FD5H (bzw. FFAAH oder FFABH = 1111 1111 1010 101x B in 2-Byte-Schreibweise) (entspricht 327,25 km/h) (nicht D1GP/BY61x)V_Fehler = 7FE6H (bzw. FFCCH oder FFCDH = 1111 1111 1100 110x B in";
CM_ SG_ 1184 BR3_Fahrtr_VL "Fahrtrichtung VL
Fahrtrichtungserkennung (im Audi D3/C6 und Colorado)";
CM_ SG_ 1184 BR3_Fahrtr_VR "Fahrtrichtung VR
Fahrtrichtungserkennung (im Audi D3/C6 und Colorado)";
CM_ SG_ 1184 BR3_Fahrtr_HR "Fahrtrichtung HR
Fahrtrichtungserkennung (im Audi D3/C6 und Colorado)";
CM_ SG_ 1184 BR3_Rad_kmh_HL "Radgeschw. HL
Low Byte 5, High Byte 6 (Auflösung 1,28 km/h);  ; Radgeschwindigkeit bezieht sich auf den 'Kombi 3 ReifenumfangKonstanten:V_INIT =  7FC4H  (bzw. FF88H oder FF89H = 1111 1111 1000 100x B in 2-Byte-Schreibweise) (entspricht 327,08 km/h) (nicht Colorado, D1GP/BY61x)V_INIT = 0 (im Colorado, D1GP/BY61x)V_Uspg =  7FD5H (bzw. FFAAH oder FFABH = 1111 1111 1010 101x B in 2-Byte-Schreibweise) (entspricht 327,25 km/h) (nicht D1GP/BY61x)V_Fehler = 7FE6H (bzw. FFCCH oder FFCDH = 1111 1111 1100 110x B in";
CM_ SG_ 1184 BR3_Fahrtr_HL "Fahrtrichtung HL
Fahrtrichtungserkennung (im Audi D3/C6 und Colorado)";
CM_ SG_ 174 BR9_res_09 " 
 ";
CM_ SG_ 174 BR9_res_10 " 
 ";
CM_ SG_ 174 BR9_res_08 " 
 ";
CM_ SG_ 174 BR9_Zaehler "Botschaftszähler (Bremse 9)
Freilaufender Botschaftszähler, dient als Quelle des Botschaftsspiegels in Lenkhilfe_3 Botschaft";
CM_ SG_ 174 BR9_Checksumme "Checksumme (Bremse 9)
Prüfsumme, Definition im CAN-Lastenheft";
CM_ SG_ 174 BR9_res_52 " 
 ";
CM_ SG_ 174 BR9_res_54 " 
 ";
CM_ SG_ 174 BR9_res_53 " 
 ";
CM_ SG_ 174 BR9_res_55 " 
 ";
CM_ SG_ 174 BR9_res_11 " 
 ";
CM_ SG_ 174 BR9_LMOffset "Anforderung Lenkmomenten-Offset
reale Auflösung 0,01 Nm";
CM_ SG_ 174 BR9_LMOffSign "Lenkmomenten-Offset-Sign
Vorzeichen Anforderung Lenkmomenten-Offset";
CM_ SG_ 174 BR9_LWOffset "Anforderung Lenkwinkel-Offset
positiver Lenkradwinkel: nach linksnegativer Lenkradwinkel: nach rechts";
CM_ SG_ 174 BR9_LWOffSign "Lenkwinkel-Offset-Sign
Vorzeichen Anforderung Lenkwinkel-Offset";
CM_ SG_ 174 BR9_res_56 " 
 ";
CM_ SG_ 174 BR9_res_59 " 
 ";
CM_ SG_ 174 BR9_res_60 " 
 ";
CM_ SG_ 174 BR9_Sta_DSR "Status DSR
0 DSR deaktiviert1 DSR Anforderung nicht ausführbar (ESP Fehlerstatus)2 Kommunikation zum ESP-SG gestört3 ESP bzgl. DSR funktionsbereit4 offen5 externer Momenteneingriff angefordert6 externer Lenkwinkeleingriff angefordert7 externer Momenten und Lenkwinkeleingriff angefordert8..15 reserviert";
CM_ SG_ 174 BR9_res_57 " 
 ";
CM_ SG_ 174 BR9_res_63 " 
 ";
CM_ SG_ 174 BR9_res_58 " 
 ";
CM_ SG_ 174 BR9_res_62 " 
 ";
CM_ SG_ 174 BR9_res_61 " 
 ";
CM_ SG_ 684 GS1_Checksumme "Checksumme (Geschwindigkeit 1)
Prüfsumme, Definition im CAN-Lastenheft";
CM_ SG_ 684 GS1_Rad_kmh "Geschwindigkeit
Low Byte 4, High Byte 5Bremse holt sich den Radumfang aus der Botschaft 'Kombi_3'ESP 5.7: Ausgegeben wird die Geschwindigkeit des linken VorderradesESP 8 Quattro: 4 RäderESP 8 Front: 2 Räder VABei MSR oder ASR-Eingriffen wird für >=200ms die ABS-Referenzgeschwindigkeit eingespiegelt.Konstanten:V_INIT =  FF88h entspricht 654,16 km/hV_Uspg =  FFAAh entspricht 654,50 km/hV_Fehler = FFCCh entspricht 654,84 km/hV_Ref_na = FF99h entspricht 654,33 km/h";
CM_ SG_ 684 GS1_QBit_Rad_kmh "Qualifizierungsbit Geschwindigkeit
Definition nach CAN-Lastenheft";
CM_ SG_ 684 GS1_Zaehler "Zähler (Geschwindigkeit 1)
Definition nach CAN-Lastenheft";
CM_ SG_ 684 GS1_res_04 " 
 ";
CM_ SG_ 684 GS1_res_05 " 
ESP8 sendet noch Initwert 1";
CM_ SG_ 684 GS1_res_08 " 
ESP8 im Audi C6 sendet bei CVT kodierter Variante noch die Referenzgeschwindigkeit und bei nicht CVT kodiert den V_INIT oder V_REF_na Wert";
CM_ SG_ 684 GS1_Fahrtrichtung "Fahrtrichtung
Fahrtrichtung";
CM_ SG_ 1986 LWI_Codierbytes "Codierbytes
 ";
CM_ SG_ 1986 LWI_Init_ID "ID für LWS_Init
 ";
CM_ SG_ 928 B10_Zaehler "Botschaftszähler
Überlaufender Botschaftszähler, zur Lebenderkennung";
CM_ SG_ 928 B10_QB_Wegimp_VL "Qualifizierungsbit Wegimpulse VL
Definition nach CAN-Lastenheft";
CM_ SG_ 928 B10_QB_Wegimp_VR "Qualifizierungsbit Wegimpulse VR
Definition nach CAN-Lastenheft";
CM_ SG_ 928 B10_QB_Wegimp_HL "Qualifizierungsbit Wegimpulse HL
Definition nach CAN-Lastenheft";
CM_ SG_ 928 B10_QB_Wegimp_HR "Qualifizierungsbit Wegimpulse HR
Definition nach CAN-Lastenheft";
CM_ SG_ 928 B10_Checksumme "Checksumme
Prüfsumme, Definition im CAN-Lastenheft";
CM_ SG_ 928 B10_Wegimp_VL "Wegimpulse VL
Anzahl der Wegimpulse Vorderrad links (steigende und fallende Flanke)Zähler läuft grundsätzlich vorwärts, auch bei Rückwärtsfahrt";
CM_ SG_ 928 B10_Wegimp_VR "Wegimpulse VR
Anzahl der Wegimpulse Vorderrad rechts (steigende und fallende Flanke)Zähler läuft grundsätzlich vorwärts, auch bei Rückwärtsfahrt";
CM_ SG_ 928 B10_Wegimp_HL "Wegimpulse HL
Anzahl der Wegimpulse Vorderrad links (steigende und fallende Flanke)Zähler läuft grundsätzlich vorwärts, auch bei Rückwärtsfahrt";
CM_ SG_ 928 B10_Wegimp_HR "Wegimpulse HR
Anzahl der Wegimpulse Vorderrad links (steigende und fallende Flanke)Zähler läuft grundsätzlich vorwärts, auch bei Rückwärtsfahrt";
CM_ SG_ 928 B10_QB_Fahrtr_VL "Qualifizierungsbit  Fahrtrichtung VL
Definition nach CAN-Lastenheft";
CM_ SG_ 928 B10_QB_Fahrtr_HL "Qualifizierungsbit  Fahrtrichtung HL
Definition nach CAN-Lastenheft";
CM_ SG_ 928 B10_QB_Fahrtr_HR "Qualifizierungsbit  Fahrtrichtung HR
Definition nach CAN-Lastenheft";
CM_ SG_ 928 B10_Fahrtr_HL "Fahrtrichtung HL
Fahrtrichtungserkennung Hinterrad links";
CM_ SG_ 928 B10_Fahrtr_HR "Fahrtrichtung HR
Fahrtrichtungserkennung Hinterrad rechts";
CM_ SG_ 928 B10_QB_Fahrtr_VR "Qualifizierungsbit  Fahrtrichtung VR
Definition nach CAN-Lastenheft";
CM_ SG_ 928 B10_Fahrtr_VR "Fahrtrichtung VR
Fahrtrichtungserkennung Vorderrad rechts";
CM_ SG_ 928 B10_Fahrtr_VL "Fahrtrichtung VL
Fahrtrichtungserkennung Vorderrad links";
CM_ SG_ 1827 NMH_ABS_Abschaltstufe_aktiv " 
1 = Funktionsabschaltung wegen Abschaltstufe";
CM_ SG_ 1827 NMH_ABS_Car_WakeUp " 
Car WakeUp optional";
CM_ SG_ 1827 NMH_ABS_Eindraht_Fehler " 
1 = Eindrahtbetrieb erkannt";
CM_ SG_ 1827 NMH_ABS_Fkt_WakeUp " 
´Weckursache Funktion´0 = wenn Peripheriewakeup";
CM_ SG_ 1827 NMH_ABS_kein_NL " 
kein lokaler / SG interner Nachlauf vor Wakeup";
CM_ SG_ 1827 NMH_ABS_KompSchutz " 
1 = Funktionseinschränkung aufgrund Komponentenschutz / WFS aktiv";
CM_ SG_ 1827 NMH_ABS_Mute_Mode " 
1 = Funktionseinschränkung aufgrund Mute Mode aktiv, nur VW";
CM_ SG_ 1827 NMH_ABS_CAN_Diag_deaktiv " 
1 = Keine CAN Bus bezogene Eigendiagnose";
CM_ SG_ 1827 NMH_ABS_NL_1 " 
Nachlauf 1";
CM_ SG_ 1827 NMH_ABS_NL_2 " 
Nachlauf 2";
CM_ SG_ 1827 NMH_ABS_NL_3 " 
Nachlauf 3";
CM_ SG_ 1827 NMH_ABS_NL_4 " 
Nachlauf 4";
CM_ SG_ 1827 NMH_ABS_NL_5 " 
Nachlauf 5";
CM_ SG_ 1827 NMH_ABS_NL_6 " 
Nachlauf 6";
CM_ SG_ 1827 NMH_ABS_NL_7 " 
Nachlauf 7";
CM_ SG_ 1827 NMH_ABS_NL_aktiv_5 " 
Nachlaufursache 5";
CM_ SG_ 1827 NMH_ABS_NL_aktiv_6 " 
Nachlaufursache 6";
CM_ SG_ 1827 NMH_ABS_NL_aktiv_7 " 
Nachlaufursache 7";
CM_ SG_ 1827 NMH_ABS_NL_aktiv_8 " 
Nachlaufursache 8";
CM_ SG_ 1827 NMH_ABS_NM_aktiv_Diagnose " 
NM-Nachlaufursache, nicht ´Ready To Sleep´1 = Diagnose bei Kl 15 aus";
CM_ SG_ 1827 NMH_ABS_NM_aktiv_Klemme_15 " 
NM-Nachlaufursache, nicht ´Ready To Sleep´1 = Klemme 15 ein";
CM_ SG_ 1827 NMH_ABS_NL_aktiv_4 " 
Nachlaufursache 41 = kein Fzg.-Stillstand erkannt";
CM_ SG_ 1827 NMH_ABS_NM_aktiv_Start " 
NM-Nachlaufursache, nicht ´Ready To Sleep´1 = Mindestaktivzeit Zustand ´Start´";
CM_ SG_ 1827 NMH_ABS_Normal_Mode_1 " 
Zustand Normal Mode (<-- Start)";
CM_ SG_ 1827 NMH_ABS_Normal_Mode_2 " 
Zustand Normal Mode (<-- Ready to Sleep)";
CM_ SG_ 1827 NMH_ABS_Per_WakeUp " 
Weckurasche Peripherie0 = wenn Funktionswakeup1 = CAN2 = P-Wakeup, Ursache nicht bekannt3 = KL 15 HW (falls vorhanden)";
CM_ SG_ 1827 NMH_ABS_TimeOut_Fehler " 
1 = Timeout Fehlerspeichereintrag";
CM_ SG_ 1827 NMH_ABS_Transport_Mode " 
1 = Funktionseinschränkung aufgrund Transport Mode aktiv";
CM_ SG_ 1827 NMH_ABS_Start_1 " 
Zustand Start (<--Sleep)";
CM_ SG_ 1827 NMH_ABS_Start_2 " 
Zustand Start (<--Prepare to Sleep)";
CM_ SG_ 1827 NMH_ABS_res_04 " 
 ";
CM_ SG_ 1827 NMH_ABS_res_05 " 
 ";
CM_ SG_ 1827 NMH_ABS_res_07 " 
 ";
CM_ SG_ 1827 NMH_ABS_res_32 " 
 ";
CM_ SG_ 1827 NMH_ABS_res_40 " 
 ";
CM_ SG_ 1827 NMH_ABS_res_41 " 
 ";
CM_ SG_ 1827 NMH_ABS_res_42 " 
 ";
CM_ SG_ 1827 NMH_ABS_res_43 " 
 ";
CM_ SG_ 1827 NMH_ABS_res_44 " 
 ";
CM_ SG_ 1827 NMH_ABS_res_45 " 
 ";
CM_ SG_ 1827 NMH_ABS_res_46 " 
 ";
CM_ SG_ 1827 NMH_ABS_res_47 " 
 ";
CM_ SG_ 1827 NMH_ABS_res_48 " 
 ";
CM_ SG_ 1827 NMH_ABS_res_49 " 
 ";
CM_ SG_ 1827 NMH_ABS_res_50 " 
 ";
CM_ SG_ 1827 NMH_ABS_res_51 " 
 ";
CM_ SG_ 1827 NMH_ABS_res_52 " 
 ";
CM_ SG_ 1827 NMH_ABS_res_53 " 
 ";
CM_ SG_ 1827 NMH_ABS_res_54 " 
 ";
CM_ SG_ 1827 NMH_ABS_res_55 " 
 ";
CM_ SG_ 1463 B11_res_00 " 
Reserviert";
CM_ SG_ 1463 B11_res_08 " 
Reserviert";
CM_ SG_ 1463 B11_Br_StSt_Info "Bremse Start Stopp Info
Stopp-Freigabe/Start-Anforderung für den Start-Stopp-Koordinator(Nicht Start/Stopp-fähige Bremsen-SGs senden die Bremse 11-Botschaft nicht oder konstant den Wert 3 Systemfehler -> Start/Stopp wird durch den Koordinator gesperrt.)";
CM_ SG_ 1463 B11_OBD_Nib_VL "Fehler Radsensor VL
Fehlerstatus des Radsensors vorne linksDa im MSG v-Fhz eine OBD-relevante Größe ist, müssen im Fehlerfall erweiterte Diagnoseinformationen zur Signalquelle mittels GST (Generic Scan Tool) abrufbar sein. Je nach Schnittstelle Radsensor/Bremsen-SG können nicht alle der genannten Fehlerarten erkannt werden.KS = KurzschlussOC = LeitungsunterbrechungRC = Rationality CheckOOR = Out of Range0000 = kein Fehler0001 = KS-0010 = KS+0011 = OC0100 = OOR+0101 = OOR-0110 = RC+0111 = RC-1000 = KS+/OC1";
CM_ SG_ 1463 B11_OBD_Nib_VR "Fehler Radsensor VR
Fehlerstatus des Radsensors vorne rechtsDa im MSG v-Fhz eine OBD-relevante Größe ist, müssen im Fehlerfall erweiterte Diagnoseinformationen zur Signalquelle mittels GST (Generic Scan Tool) abrufbar sein. Je nach Schnittstelle Radsensor/Bremsen-SG können nicht alle der genannten Fehlerarten erkannt werden.KS = KurzschlussOC = LeitungsunterbrechungRC = Rationality CheckOOR = Out of Range0000 = kein Fehler0001 = KS-0010 = KS+0011 = OC0100 = OOR+0101 = OOR-0110 = RC+0111 = RC-1000 = KS+/OC";
CM_ SG_ 1463 B11_OBD_Nib_HL "Fehler Radsensor HL
Fehlerstatus des Radsensors hinten linksDa im MSG v-Fhz eine OBD-relevante Größe ist, müssen im Fehlerfall erweiterte Diagnoseinformationen zur Signalquelle mittels GST (Generic Scan Tool) abrufbar sein. Je nach Schnittstelle Radsensor/Bremsen-SG können nicht alle der genannten Fehlerarten erkannt werden.KS = KurzschlussOC = LeitungsunterbrechungRC = Rationality CheckOOR = Out of Range0000 = kein Fehler0001 = KS-0010 = KS+0011 = OC0100 = OOR+0101 = OOR-0110 = RC+0111 = RC-1000 = KS+/OC";
CM_ SG_ 1463 B11_OBD_Nib_HR "Fehler Radsensor HR
Fehlerstatus des Radsensors hinten rechtsDa im MSG v-Fhz eine OBD-relevante Größe ist, müssen im Fehlerfall erweiterte Diagnoseinformationen zur Signalquelle mittels GST (Generic Scan Tool) abrufbar sein. Je nach Schnittstelle Radsensor/Bremsen-SG können nicht alle der genannten Fehlerarten erkannt werden.KS = KurzschlussOC = LeitungsunterbrechungRC = Rationality CheckOOR = Out of Range0000 = kein Fehler0001 = KS-0010 = KS+0011 = OC0100 = OOR+0101 = OOR-0110 = RC+0111 = RC-1000 = KS+/O";
CM_ SG_ 1463 B11_HydHalten "Hydraulisches Halten aktiv
Das Bit wird gesetzt, wenn das Fahrzeug durch den Berganfahrassistenten (Hill-Hold) gehalten wird.";
CM_ SG_ 1463 B11_res_12 " 
 ";
CM_ SG_ 1463 B11_EPB_Steller_akt "EPB-Steller verfährt
Reserviert für Information für Start-Stopp-Koordinator.Für zukünftige EPB (nach PQ46/VW416) nicht mehr notwendig.";
CM_ SG_ 1463 B11_EPB_Steller_gue "EPB-Steller-Info gültig
Reserviert für Information für Start-Stopp-Koordinator.Für zukünftige EPB (nach PQ46/VW416) nicht mehr notwendig.";
CM_ SG_ 1463 B11_res_34 " 
 ";
CM_ SG_ 1463 B11_res_35 " 
 ";
CM_ SG_ 1463 B11_res_36 " 
 ";
CM_ SG_ 1463 B11_res_37 " 
 ";
CM_ SG_ 1463 B11_res_38 " 
 ";
CM_ SG_ 1463 B11_res_39 " 
 ";
CM_ SG_ 1463 B11_res_40 " 
 ";
CM_ SG_ 1463 B11_res_41 " 
 ";
CM_ SG_ 1463 B11_res_42 " 
 ";
CM_ SG_ 1463 B11_res_43 " 
 ";
CM_ SG_ 1463 B11_res_44 " 
 ";
CM_ SG_ 1463 B11_res_45 " 
 ";
CM_ SG_ 1463 B11_res_46 " 
 ";
CM_ SG_ 1463 B11_res_47 " 
 ";
CM_ SG_ 1463 B11_res_48 " 
 ";
CM_ SG_ 1463 B11_res_49 " 
 ";
CM_ SG_ 1463 B11_res_50 " 
 ";
CM_ SG_ 1463 B11_res_51 " 
 ";
CM_ SG_ 1463 B11_res_52 " 
 ";
CM_ SG_ 1463 B11_res_53 " 
 ";
CM_ SG_ 1463 B11_res_54 " 
 ";
CM_ SG_ 1463 B11_res_55 " 
 ";
CM_ SG_ 1463 B11_res_56 " 
 ";
CM_ SG_ 1463 B11_res_57 " 
 ";
CM_ SG_ 1463 B11_res_58 " 
 ";
CM_ SG_ 1463 B11_res_59 " 
 ";
CM_ SG_ 1463 B11_res_61 " 
 ";
CM_ SG_ 1463 B11_res_62 " 
 ";
CM_ SG_ 1463 B11_res_63 " 
 ";
CM_ SG_ 1463 B11_res_60 " 
 ";
CM_ SG_ 194 LW1_LRW_Sign "Lenkradwinkel_Sign
positiver Lenkradwinkel: nach links ; negativer Lenkradwinkel: nach rechts";
CM_ SG_ 194 LW1_Lenk_Gesch "Lenkradwinkel-Geschwindigkeit
Low Byte 3, High Byte 4 ; 0  keine Bewegung; 7FFFH maximale Geschwindigkeit";
CM_ SG_ 194 LW1_Gesch_Sign "Lenkradwinkel-Geschwindigkeit_Sign
 ";
CM_ SG_ 194 LW1_ID "Lenkwinkel_ID
Nullpunktabgleich des LWS noch nicht durchgeführt;Sonstige Fzg (außer PQ35): ESP-Steuergerät übergibt beim Nullpunktabgleich eine ID-Nummer an den LWS. Die Zufallszahl wird nach erfolgreichem Nullpunktabgleich als Lenkwinkel_ID übernommenPQ35/46: Bit 7 auf 1 (entspricht 80H) steht für Sensor ist kalibriert; Bit 0..6 können zukünftig neu belegt werden";
CM_ SG_ 194 LW1_Initquelle "Quelle für Init
Lenkwinkelsensor wird über Raddrehzahl oder 'Geradeausfahrt'-Bit der EPS initialisiert";
CM_ SG_ 194 LW1_Status "Interner_Status
o.k.: absoluter Lenkradwinkel und Lenkradwinkel-geschwindigkeit werden korrekt berechnet ; no init: Sensor ist nicht initialisiert, absoluter Lenkrad-winkel kann noch nicht berechnet werden, kein Fehler ; sporadischer Fehler: Sensor ist bis zum Ausschalten ; der Zündung abgeschaltet ; dauerhafter Fehler: Sensor ist permanent abgeschaltet";
CM_ SG_ 194 LW1_LRW "Lenkradwinkel
Low Byte 1, High Byte 2 ; 0  geradeaus; 7FFFH am Anschlag";
CM_ SG_ 194 LW1_Sta_KL30 "Status_KL30_Ausfall
(z.Zt. nur Kostal-Sensor) ; Sensor ist nach KL30-Ausfall nicht initialisiert, absoluter Lenkradwinkel kann noch nicht be-rechnet werden, Segmenterkennung durch Auswertung der Radsignale";
CM_ SG_ 194 LW1_CRC8CHK "CRC8 Checksumme / ALT: Kodierdaten
NEUES SIGNAL CRC8 Checksumme (z. Zt. Lenkhilfe ZF Gen. 3)!CRC Prüfsumme über die Bytes 1..6 / Diese ist nach Spezifikation 'CAN Checksumme CRC-8; Version 1.1; 23.09.05' durchzuführen.ACHTUNG: Der separate LWS gibt in Byte 7 noch das Signal LW1_Kodier (Kodierdaten) aus: Multiplex-Ausgabe der 3 Kodierbytes abh. Vom Zähler in Byte 6 (Bit 7 oder 6 ungleich 0)";
CM_ SG_ 194 LW1_CRC "Prüfsumme (Lenkwinkel 1)
Definition nach Lastenheft Übertragungsmodul für ESP:Einerkomplement des Ergebnisses der 8 Bit Addition von Byte 1, 2, 3, 4 und 6.";
CM_ SG_ 194 LW1_Zaehler "Zähler (Lenkwinkel 1)
freilaufender Botschaftszähler";
CM_ SG_ 531 LWS_TP_Er "TP 2.0 Eroeffnungskanal
 ";
CM_ SG_ 518 Dyn_LWR_TP_Er "TP 2.0 Eroeffnungskanal
 ";
CM_ SG_ 916 LRZ_Grundeinst "LWR und AFS Grundeinstellung
Grundeinstellung des Abblendlichtes am Lichteinstellkasten im Service oder Bandende mit Tester erfolgt! (auch für das dynamische Kurvenlicht)";
CM_ SG_ 916 LRZ_Initlauf "LWR Initialisierungslauf
Initialisierungslauf der Schrittmotoren,erfolg defaultmäßig beim Motorstart";
CM_ SG_ 916 LRZ_Einfedg_hi "Einfederung Karosse hinten
aktueller Höhensensorwert hinten (bei PQ35/46 links)(oder bei Luftfederung aus der Niveau 2-Botschaft gespiegelt)";
CM_ SG_ 916 LRZ_Fehlerlampe "LWR Fehlerlampe
Status der Fehlerlampe: aktuell anliegender Fehlerzustand";
CM_ SG_ 916 LRZ_Einfedg_vo "Einfederung Karosse vorn
aktueller Höhensensorwert vorne (bei PQ35/46 links)(oder bei Luftfederung aus der Niveau 2-Botschaft gespiegelt)";
CM_ SG_ 916 LRZ_Sichere_Pos "LWR Sicherheitsposition
LWR Sicherheitsposition beider Scheinwerfers";
CM_ SG_ 916 LRZ_Stellung "Stellung der Schrittmotoren
Position des Aktuators in Prozent des maximalen Stellweges; vor dem Initialisierungslauf (z.Zt. Motorstart) wird der Initwert ausgegeben:0% : tiefste Stellung (auf Block) des Schrittmotors;100% : maximaler Verstellweg des Schrittmotors (nicht die Grenze des Scheinwerfers)";
CM_ SG_ 916 LRZ_Fehler "LWR und AFS Fehlerspeichereintrag
Bei gesetztem Bit ist mindestens ein Kundendienstfehler eingetragen (auch sporadische bzw. passive Fehler).";
CM_ SG_ 916 LRZ_Modus "LWR-Modus
schnelle oder langsame Regelart der LWR";
CM_ SG_ 916 LRZ_LampeAFS "AFS Fehlerlampe
Status der Fehlerlampe: aktuell anliegender Fehlerzustand des dynamischen oder statischen Kurvenlichts";
CM_ SG_ 916 LRZ_Parameter "LWR und AFS Parametrisierung
Parametrisierung wählt dieFahrzeugvariante und die AFS-Variante aus";
CM_ SG_ 916 LRZ_res_48 " 
 ";
CM_ SG_ 916 LRZ_Tourist_Fkt "Touristenfunktion unterstützt
Touristenfunktion wird vom AFS Steuergerät unterstützt.0: Touristenfkt. nicht unterstützt1: Touristenfunktion unterstützt";
CM_ SG_ 916 LRZ_ELF_links "Ersatzlichtfunktion links
Bei aktivierter Ersatzlichtfunktion wird das Abblendlicht ausgeschaltet und eine Ersatzlichtquelle eingeschaltet";
CM_ SG_ 916 LRZ_ELF_rechts "Ersatzlichtfunktion rechts
Bei aktivierter Ersatzlichtfunktion wird das Abblendlicht ausgeschaltet und eine Ersatzlichtquelle eingeschaltet";
CM_ SG_ 916 LRZ_LeistDim "Sollwert Leistungsdimmung EVG (links und rechts)
100% entsprechen 35 WattDie Last schaltet nur das ILM";
CM_ SG_ 916 LRZ_AFSLED_Blink "AFS-LED Blinkmode
Lampe soll im Warnfall mit 1Hz blinken, wenn das Bit gesetzt ist (z. Zt. nur bei VW)";
CM_ SG_ 916 LRZ_AFSFehlertext "AFS-Fehlertext
Fehlertext wird im Kombi angezeigt (z. Zt. nur bei VW)";
CM_ SG_ 916 LRZ_Zaehler "Botschaftszähler
Botschaftszähler der LWR-Zustandsbotschaft wird zyklisch beim Absenden jeder Botschaft um 1 inkrementiert";
CM_ SG_ 916 LRZ_res_56 " 
 ";
CM_ SG_ 916 LRZ_AFS_Absch "AFS Abschaltung unterstützt
AFS Deaktivierung wird vom AFS Steuergerät unterstützt.Funktion auch während der Fahrt bedienbar.0: keine AFS Deaktivierung über Kombi möglich 1: AFS unterstützt Deaktivierung über Kombi";
CM_ SG_ 916 LRZ_AFS_deaktiv "AFS ein / aus
AFS deaktiviert heißt kein Schwenken und Standard-LWR also Anhebung in besonderen Geschwindigkeitsbereichen.0: AFS aktiviert1: AFS deaktiviert";
CM_ SG_ 916 LRZ_Tourist_aktiv "Touristenfunktion ein /aus
Touristenfunktion ein heißt Absenken der HGD und Schwenken deaktivieren wurde von AFS- Steuergerät umgesetzt.0: Touristenfunktion deaktiviert1: Touristenfunktion aktiviert";
CM_ SG_ 1096 WH1_Init "Wählhebel-Initialisierung
Das Bit zeigt dem Empfänger an, dass der Wählhebel in der Initialisierung war (z.B. Reset). Das Signal steht für 500ms ab Sendebeginn auf 1, danach dauerhaft auf 0.	";
CM_ SG_ 1096 WH1_Position "Wählhebelposition (Wählhebel 1)
Die Codierung der Wählhebelposition entspricht der Codierung in der Getriebe1 Botschaft";
CM_ SG_ 1096 WH1_StaShiftlock "Shiftlock-Position
Status der Shiftlockansteuerung Shiftlock aktiv bedeutet, der Shiftlockmagnet wird so angesteuert, daß die mechanische Verriegelung greifen würde, wenn die entsprechende Position des Wählhebels vorliegen würde. Dies kann bedeuten, stromlos verriegelt oder bestromt verriegelt. ; Beim FSI mit DS-Getriebe soll der stromlos verriegelte Shift-Lock einsetzen. ; Die Bits geben den Status der Shiftlockansteuerung seitens des Wählhebelmoduls wieder, falls die Ansteuerung durch das Wählhebelmodul";
CM_ SG_ 1096 WH1_Status "Status (Wählhebel 1)
Das Wählhebelmodul liefert aktuelle Fehlerzustände. Die Fehlereinträge werden im Getriebesteuergerät abgelegt. ; (01: z.B. Shift lock, Lampenansteuerung, ...)";
CM_ SG_ 1096 WH1_Testergebnis "Testergebnis (Wählhebel 1)
Ergebnis des Controllertests initiert durch Testfreigabeflag und Testparameter 1 + 2 aus Getriebe 3  Hier wird in Verbindung mit dem 'Test aktiv Flag' das gültige Testergebnis eines noch zu definierenden Frage- und Antwortspiels zur Überprüfung des Mikrokontrollers übertragen. Die Aufgabenstellung erfolgt über die beiden Bytes 'Testparameter 1 + 2', sowie über das Bit 'Testfreigabeflag' in der exklusiv für den Wählhebel gesendeten 'Getriebe 4 Botschaft. ;  ; Die Prüfung wird re";
CM_ SG_ 1096 WH1_Zaehler "Zähler (Wählhebel 1)
Freilaufender Botschaftszähler  Dient der Synchronisierung der Getriebebotschaften und stellt sicher, daß der Wählhebelrechner noch lebt, damit der Testmode nicht länger wie zwei Zyklen (20ms) aktiviert ist.";
CM_ SG_ 1096 WH1_Position_inv "Wählhebelposition invers (Wählhebel 1)
Bitweise Inverse Codierung der Wählhebelposition aus Byte 1, Bit 7..4Bemerkungen zur Multiplex-Information: Shiftlock aktiv bedeutet, der Shiftlockmagnet wird so angesteuert, daß die mechanische Verriegelung greifen würde, wenn die entsprechende Position des Wählhebels vorliegen würde. Dies kann bedeuten, stromlos verriegelt oder bestromt verriegelt.Beim FSI mit DS-Getriebe soll der stromlos verriegelte Shift-Lock einsetzen.Die Bits geben den Status der Shiftlockanst";
CM_ SG_ 1096 WH1_Reserve2 " 
 ";
CM_ SG_ 1096 WH1_Reserve1 " 
Frei";
CM_ SG_ 1096 WH1_Test_Flag "Test aktiv Flag (Wählhebel 1)
Controllertestergebnis gültig, Wählhebelposition kann evtl. nicht aktuell sein";
BA_DEF_ BO_  "VAGTP20_API" HEX 0 255;
BA_DEF_ BO_  "VAGTP20_StatConnection" ENUM  "No","Yes";
BA_DEF_ BO_  "VAGTP20_DynConnection" ENUM  "No","Yes";
BA_DEF_ BO_  "VAGTP20_DynSetup" ENUM  "No","Yes";
BA_DEF_ BO_  "NmMessage" ENUM  "No","Yes";
BA_DEF_ BO_  "NmhMessage" ENUM  "No","Yes";
BA_DEF_ BO_  "GenMsgCycleTime" INT 0 65535;
BA_DEF_ BO_  "GenMsgSendType" ENUM  "cyclicX","spontanX","cyclicIfActiveX","spontanWithDelay","cyclicAndSpontanX","cyclicAndSpontanWithDelay","spontanWithRepitition","cyclicIfActiveAndSpontanWD","NoMsgSendType","cyclicWithRepeatOnDemand";
BA_DEF_ BO_  "GenMsgCycleTimeFast" INT 0 65535;
BA_DEF_ BO_  "GenMsgNrOfRepetition" INT 0 255;
BA_DEF_ BO_  "GenMsgDelayTime" INT 0 100000;
BA_DEF_ BO_  "GenMsgILSupport" ENUM  "No","Yes";
BA_DEF_ BO_  "GenMsgTimeoutTime" INT 0 100000;
BA_DEF_ BO_  "GenMsgAutoGenDsp" ENUM  "No","Yes";
BA_DEF_ BO_  "GenMsgAutoGenSnd" ENUM  "No","Yes";
BA_DEF_ BO_  "DiagRequest" ENUM  "No","Yes";
BA_DEF_ BO_  "DiagResponse" ENUM  "No","Yes";
BA_DEF_ BO_  "DiagState" ENUM  "No","Yes";
BA_DEF_ SG_  "GenSigSendType" ENUM  "Cyclic","OnWrite","OnWriteWithRepetition","OnChange","OnChangeWithRepetition","IfActive","IfActiveWithRepetition","NoSigSendType";
BA_DEF_ SG_  "GenSigStartValue" INT 0 4294967295;
BA_DEF_ SG_  "GenSigInactiveValue" INT 0 2147483647;
BA_DEF_ SG_  "GenSigAutoGenDsp" ENUM  "No","Yes";
BA_DEF_ SG_  "GenSigAutoGenSnd" ENUM  "No","Yes";
BA_DEF_ SG_  "GenSigEnvVarType" STRING ;
BA_DEF_ SG_  "GenSigFuncType" ENUM  "NoFunction","MsgCounter","CRC-8","XOR","XOR-2","DatedBit","SW-Kl15","CHK","Constant","Protokoll";
BA_DEF_ SG_  "NWM-WakeUpAllowed" ENUM  "No","Yes";
BA_DEF_ SG_  "INIT" STRING ;
BA_DEF_ SG_  "GenSigTimeoutMsg_Airbag" HEX 0 2047;
BA_DEF_ SG_  "GenSigTimeoutTime_Airbag" INT 0 65535;
BA_DEF_ SG_  "GenSigTimeoutMsg_Allrad" HEX 0 2047;
BA_DEF_ SG_  "GenSigTimeoutTime_Allrad" INT 0 65535;
BA_DEF_ SG_  "GenSigTimeoutMsg_Lenkhilfe_ZF_2" HEX 0 2047;
BA_DEF_ SG_  "GenSigTimeoutTime_Lenkhilfe_ZF_2" INT 0 65535;
BA_DEF_ SG_  "GenSigTimeoutMsg_Teves_MK60_ESP" HEX 0 2047;
BA_DEF_ SG_  "GenSigTimeoutTime_Teves_MK60_ESP" INT 0 65535;
BA_DEF_ SG_  "GenSigTimeoutMsg_LWS" HEX 0 2047;
BA_DEF_ SG_  "GenSigTimeoutTime_LWS" INT 0 65535;
BA_DEF_ SG_  "GenSigTimeoutMsg_LWR" HEX 0 2047;
BA_DEF_ SG_  "GenSigTimeoutTime_LWR" INT 0 65535;
BA_DEF_ SG_  "GenSigTimeoutMsg_Teves_MK70_MAB" HEX 0 2047;
BA_DEF_ SG_  "GenSigTimeoutTime_Teves_MK70_MAB" INT 0 65535;
BA_DEF_ SG_  "GenSigTimeoutMsg_Waehlhebel" HEX 0 2047;
BA_DEF_ SG_  "GenSigTimeoutTime_Waehlhebel" INT 0 65535;
BA_DEF_ SG_  "GenSigTimeoutMsg_EPB" HEX 0 2047;
BA_DEF_ SG_  "GenSigTimeoutTime_EPB" INT 0 65535;
BA_DEF_ SG_  "GenSigTimeoutMsg_TRW_ESP" HEX 0 2047;
BA_DEF_ SG_  "GenSigTimeoutTime_TRW_ESP" INT 0 65535;
BA_DEF_ SG_  "GenSigTimeoutMsg_ACC_Radar" HEX 0 2047;
BA_DEF_ SG_  "GenSigTimeoutTime_ACC_Radar" INT 0 65535;
BA_DEF_ SG_  "GenSigTimeoutMsg_AFS" HEX 0 2047;
BA_DEF_ SG_  "GenSigTimeoutTime_AFS" INT 0 65535;
BA_DEF_ SG_  "GenSigTimeoutMsg_Magne_Ride" HEX 0 2047;
BA_DEF_ SG_  "GenSigTimeoutTime_Magne_Ride" INT 0 65535;
BA_DEF_ SG_  "GenSigTimeoutMsg_RKA_Plus" HEX 0 2047;
BA_DEF_ SG_  "GenSigTimeoutTime_RKA_Plus" INT 0 65535;
BA_DEF_ SG_  "GenSigTimeoutMsg_Selespeed" HEX 0 2047;
BA_DEF_ SG_  "GenSigTimeoutTime_Selespeed" INT 0 65535;
BA_DEF_ SG_  "GenSigTimeoutMsg_Waehlhebel_Sel" HEX 0 2047;
BA_DEF_ SG_  "GenSigTimeoutTime_Waehlhebel_Sel" INT 0 65535;
BA_DEF_ SG_  "GenSigTimeoutMsg_PDC_PLA" HEX 0 2047;
BA_DEF_ SG_  "GenSigTimeoutTime_PDC_PLA" INT 0 65535;
BA_DEF_ SG_  "GenSigTimeoutMsg_Lenkhilfe_APA" HEX 0 2047;
BA_DEF_ SG_  "GenSigTimeoutTime_Lenkhilfe_APA" INT 0 65535;
BA_DEF_ SG_  "GenSigTimeoutMsg_VAQ" HEX 0 2047;
BA_DEF_ SG_  "GenSigTimeoutTime_VAQ" INT 0 65535;
BA_DEF_ SG_  "GenSigTimeoutMsg_Daempfer" HEX 0 2047;
BA_DEF_ SG_  "GenSigTimeoutTime_Daempfer" INT 0 65535;
BA_DEF_ SG_  "GenSigTimeoutMsg_Hybrid_BMS" HEX 0 2047;
BA_DEF_ SG_  "GenSigTimeoutTime_Hybrid_BMS" INT 0 65535;
BA_DEF_ SG_  "GenSigTimeoutMsg_Hybrid_PWR" HEX 0 2047;
BA_DEF_ SG_  "GenSigTimeoutTime_Hybrid_PWR" INT 0 65535;
BA_DEF_ SG_  "GenSigTimeoutMsg_Hybrid_DQ200" HEX 0 2047;
BA_DEF_ SG_  "GenSigTimeoutTime_Hybrid_DQ200" INT 0 65535;
BA_DEF_ SG_  "GenSigTimeoutMsg_EKlimakomp" HEX 0 2047;
BA_DEF_ SG_  "GenSigTimeoutTime_EKlimakomp" INT 0 65535;
BA_DEF_ SG_  "GenSigTimeoutMsg_SWA" HEX 0 2047;
BA_DEF_ SG_  "GenSigTimeoutTime_SWA" INT 0 65535;
BA_DEF_ SG_  "GenSigTimeoutMsg_HCA" HEX 0 2047;
BA_DEF_ SG_  "GenSigTimeoutTime_HCA" INT 0 65535;
BA_DEF_ SG_  "GenSigTimeoutMsg_ACC_Lidar" HEX 0 2047;
BA_DEF_ SG_  "GenSigTimeoutTime_ACC_Lidar" INT 0 65535;
BA_DEF_ SG_  "GenSigTimeoutMsg_Lenkhilfe_ZF_3" HEX 0 2047;
BA_DEF_ SG_  "GenSigTimeoutTime_Lenkhilfe_ZF_3" INT 0 65535;
BA_DEF_ SG_  "GenSigTimeoutMsg_FLA" HEX 0 2047;
BA_DEF_ SG_  "GenSigTimeoutTime_FLA" INT 0 65535;
BA_DEF_ SG_  "GenSigTimeoutMsg_AG6" HEX 0 2047;
BA_DEF_ SG_  "GenSigTimeoutTime_AG6" INT 0 65535;
BA_DEF_ SG_  "GenSigTimeoutMsg_DQ" HEX 0 2047;
BA_DEF_ SG_  "GenSigTimeoutTime_DQ" INT 0 65535;
BA_DEF_ SG_  "GenSigTimeoutMsg_Hybrid_MSG" HEX 0 2047;
BA_DEF_ SG_  "GenSigTimeoutTime_Hybrid_MSG" INT 0 65535;
BA_DEF_ SG_  "GenSigTimeoutMsg_Diesel" HEX 0 2047;
BA_DEF_ SG_  "GenSigTimeoutTime_Diesel" INT 0 65535;
BA_DEF_ SG_  "GenSigTimeoutMsg_Otto" HEX 0 2047;
BA_DEF_ SG_  "GenSigTimeoutTime_Otto" INT 0 65535;
BA_DEF_ SG_  "GenSigTimeoutMsg_Gateway_PQ35_A" HEX 0 2047;
BA_DEF_ SG_  "GenSigTimeoutTime_Gateway_PQ35_A" INT 0 65535;
BA_DEF_ SG_  "GenSigTimeoutMsg_Gateway_PQ46_A" HEX 0 2047;
BA_DEF_ SG_  "GenSigTimeoutTime_Gateway_PQ46_A" INT 0 65535;
BA_DEF_DEF_  "VAGTP20_API" 0;
BA_DEF_DEF_  "VAGTP20_StatConnection" "No";
BA_DEF_DEF_  "VAGTP20_DynConnection" "No";
BA_DEF_DEF_  "VAGTP20_DynSetup" "No";
BA_DEF_DEF_  "NmMessage" "No";
BA_DEF_DEF_  "NmhMessage" "No";
BA_DEF_DEF_  "GenMsgCycleTime" 0;
BA_DEF_DEF_  "GenMsgSendType" "NoMsgSendType";
BA_DEF_DEF_  "GenMsgCycleTimeFast" 0;
BA_DEF_DEF_  "GenMsgNrOfRepetition" 0;
BA_DEF_DEF_  "GenMsgDelayTime" 0;
BA_DEF_DEF_  "GenMsgILSupport" "No";
BA_DEF_DEF_  "GenMsgTimeoutTime" 0;
BA_DEF_DEF_  "GenMsgAutoGenDsp" "Yes";
BA_DEF_DEF_  "GenMsgAutoGenSnd" "Yes";
BA_DEF_DEF_  "DiagRequest" "No";
BA_DEF_DEF_  "DiagResponse" "No";
BA_DEF_DEF_  "DiagState" "No";
BA_DEF_DEF_  "GenSigSendType" "NoSigSendType";
BA_DEF_DEF_  "GenSigStartValue" 0;
BA_DEF_DEF_  "GenSigInactiveValue" 0;
BA_DEF_DEF_  "GenSigAutoGenDsp" "Yes";
BA_DEF_DEF_  "GenSigAutoGenSnd" "Yes";
BA_DEF_DEF_  "GenSigEnvVarType" "Undef";
BA_DEF_DEF_  "GenSigFuncType" "NoFunction";
BA_DEF_DEF_  "NWM-WakeUpAllowed" "No";
BA_DEF_DEF_  "INIT" "";
BA_DEF_DEF_  "GenSigTimeoutMsg_Airbag" 0;
BA_DEF_DEF_  "GenSigTimeoutTime_Airbag" 0;
BA_DEF_DEF_  "GenSigTimeoutMsg_Allrad" 0;
BA_DEF_DEF_  "GenSigTimeoutTime_Allrad" 0;
BA_DEF_DEF_  "GenSigTimeoutMsg_Lenkhilfe_ZF_2" 0;
BA_DEF_DEF_  "GenSigTimeoutTime_Lenkhilfe_ZF_2" 0;
BA_DEF_DEF_  "GenSigTimeoutMsg_Teves_MK60_ESP" 0;
BA_DEF_DEF_  "GenSigTimeoutTime_Teves_MK60_ESP" 0;
BA_DEF_DEF_  "GenSigTimeoutMsg_LWS" 0;
BA_DEF_DEF_  "GenSigTimeoutTime_LWS" 0;
BA_DEF_DEF_  "GenSigTimeoutMsg_LWR" 0;
BA_DEF_DEF_  "GenSigTimeoutTime_LWR" 0;
BA_DEF_DEF_  "GenSigTimeoutMsg_Teves_MK70_MAB" 0;
BA_DEF_DEF_  "GenSigTimeoutTime_Teves_MK70_MAB" 0;
BA_DEF_DEF_  "GenSigTimeoutMsg_Waehlhebel" 0;
BA_DEF_DEF_  "GenSigTimeoutTime_Waehlhebel" 0;
BA_DEF_DEF_  "GenSigTimeoutMsg_EPB" 0;
BA_DEF_DEF_  "GenSigTimeoutTime_EPB" 0;
BA_DEF_DEF_  "GenSigTimeoutMsg_TRW_ESP" 0;
BA_DEF_DEF_  "GenSigTimeoutTime_TRW_ESP" 0;
BA_DEF_DEF_  "GenSigTimeoutMsg_ACC_Radar" 0;
BA_DEF_DEF_  "GenSigTimeoutTime_ACC_Radar" 0;
BA_DEF_DEF_  "GenSigTimeoutMsg_AFS" 0;
BA_DEF_DEF_  "GenSigTimeoutTime_AFS" 0;
BA_DEF_DEF_  "GenSigTimeoutMsg_Magne_Ride" 0;
BA_DEF_DEF_  "GenSigTimeoutTime_Magne_Ride" 0;
BA_DEF_DEF_  "GenSigTimeoutMsg_RKA_Plus" 0;
BA_DEF_DEF_  "GenSigTimeoutTime_RKA_Plus" 0;
BA_DEF_DEF_  "GenSigTimeoutMsg_Selespeed" 0;
BA_DEF_DEF_  "GenSigTimeoutTime_Selespeed" 0;
BA_DEF_DEF_  "GenSigTimeoutMsg_Waehlhebel_Sel" 0;
BA_DEF_DEF_  "GenSigTimeoutTime_Waehlhebel_Sel" 0;
BA_DEF_DEF_  "GenSigTimeoutMsg_PDC_PLA" 0;
BA_DEF_DEF_  "GenSigTimeoutTime_PDC_PLA" 0;
BA_DEF_DEF_  "GenSigTimeoutMsg_Lenkhilfe_APA" 0;
BA_DEF_DEF_  "GenSigTimeoutTime_Lenkhilfe_APA" 0;
BA_DEF_DEF_  "GenSigTimeoutMsg_VAQ" 0;
BA_DEF_DEF_  "GenSigTimeoutTime_VAQ" 0;
BA_DEF_DEF_  "GenSigTimeoutMsg_Daempfer" 0;
BA_DEF_DEF_  "GenSigTimeoutTime_Daempfer" 0;
BA_DEF_DEF_  "GenSigTimeoutMsg_Hybrid_BMS" 0;
BA_DEF_DEF_  "GenSigTimeoutTime_Hybrid_BMS" 0;
BA_DEF_DEF_  "GenSigTimeoutMsg_Hybrid_PWR" 0;
BA_DEF_DEF_  "GenSigTimeoutTime_Hybrid_PWR" 0;
BA_DEF_DEF_  "GenSigTimeoutMsg_Hybrid_DQ200" 0;
BA_DEF_DEF_  "GenSigTimeoutTime_Hybrid_DQ200" 0;
BA_DEF_DEF_  "GenSigTimeoutMsg_EKlimakomp" 0;
BA_DEF_DEF_  "GenSigTimeoutTime_EKlimakomp" 0;
BA_DEF_DEF_  "GenSigTimeoutMsg_SWA" 0;
BA_DEF_DEF_  "GenSigTimeoutTime_SWA" 0;
BA_DEF_DEF_  "GenSigTimeoutMsg_HCA" 0;
BA_DEF_DEF_  "GenSigTimeoutTime_HCA" 0;
BA_DEF_DEF_  "GenSigTimeoutMsg_ACC_Lidar" 0;
BA_DEF_DEF_  "GenSigTimeoutTime_ACC_Lidar" 0;
BA_DEF_DEF_  "GenSigTimeoutMsg_Lenkhilfe_ZF_3" 0;
BA_DEF_DEF_  "GenSigTimeoutTime_Lenkhilfe_ZF_3" 0;
BA_DEF_DEF_  "GenSigTimeoutMsg_FLA" 0;
BA_DEF_DEF_  "GenSigTimeoutTime_FLA" 0;
BA_DEF_DEF_  "GenSigTimeoutMsg_AG6" 0;
BA_DEF_DEF_  "GenSigTimeoutTime_AG6" 0;
BA_DEF_DEF_  "GenSigTimeoutMsg_DQ" 0;
BA_DEF_DEF_  "GenSigTimeoutTime_DQ" 0;
BA_DEF_DEF_  "GenSigTimeoutMsg_Hybrid_MSG" 0;
BA_DEF_DEF_  "GenSigTimeoutTime_Hybrid_MSG" 0;
BA_DEF_DEF_  "GenSigTimeoutMsg_Diesel" 0;
BA_DEF_DEF_  "GenSigTimeoutTime_Diesel" 0;
BA_DEF_DEF_  "GenSigTimeoutMsg_Otto" 0;
BA_DEF_DEF_  "GenSigTimeoutTime_Otto" 0;
BA_DEF_DEF_  "GenSigTimeoutMsg_Gateway_PQ35_A" 0;
BA_DEF_DEF_  "GenSigTimeoutTime_Gateway_PQ35_A" 0;
BA_DEF_DEF_  "GenSigTimeoutMsg_Gateway_PQ46_A" 0;
BA_DEF_DEF_  "GenSigTimeoutTime_Gateway_PQ46_A" 0;
BA_ "GenMsgTimeoutTime" BO_ 1192 500;
BA_ "GenMsgSendType" BO_ 1192 0;
BA_ "GenMsgCycleTime" BO_ 1192 20;
BA_ "GenMsgTimeoutTime" BO_ 672 500;
BA_ "GenMsgSendType" BO_ 672 0;
BA_ "GenMsgCycleTime" BO_ 672 10;
BA_ "GenMsgTimeoutTime" BO_ 428 500;
BA_ "GenMsgSendType" BO_ 428 0;
BA_ "GenMsgCycleTime" BO_ 428 20;
BA_ "GenMsgSendType" BO_ 515 1;
BA_ "VAGTP20_DynSetup" BO_ 515 1;
BA_ "GenMsgTimeoutTime" BO_ 1184 500;
BA_ "GenMsgSendType" BO_ 1184 0;
BA_ "GenMsgCycleTime" BO_ 1184 10;
BA_ "GenMsgTimeoutTime" BO_ 174 500;
BA_ "GenMsgSendType" BO_ 174 0;
BA_ "GenMsgCycleTime" BO_ 174 10;
BA_ "GenMsgTimeoutTime" BO_ 684 500;
BA_ "GenMsgSendType" BO_ 684 0;
BA_ "GenMsgCycleTime" BO_ 684 20;
BA_ "GenMsgSendType" BO_ 1986 7;
BA_ "GenMsgTimeoutTime" BO_ 928 500;
BA_ "GenMsgSendType" BO_ 928 0;
BA_ "GenMsgCycleTime" BO_ 928 20;
BA_ "GenMsgTimeoutTime" BO_ 1827 2000;
BA_ "GenMsgSendType" BO_ 1827 0;
BA_ "GenMsgCycleTime" BO_ 1827 200;
BA_ "NmhMessage" BO_ 1827 1;
BA_ "GenMsgTimeoutTime" BO_ 1463 1000;
BA_ "GenMsgSendType" BO_ 1463 0;
BA_ "GenMsgCycleTime" BO_ 1463 100;
BA_ "GenMsgTimeoutTime" BO_ 194 500;
BA_ "GenMsgSendType" BO_ 194 0;
BA_ "GenMsgCycleTime" BO_ 194 10;
BA_ "GenMsgSendType" BO_ 531 1;
BA_ "VAGTP20_DynSetup" BO_ 531 1;
BA_ "GenMsgSendType" BO_ 518 1;
BA_ "VAGTP20_DynSetup" BO_ 518 1;
BA_ "GenMsgTimeoutTime" BO_ 916 1000;
BA_ "GenMsgSendType" BO_ 916 0;
BA_ "GenMsgCycleTime" BO_ 916 100;
BA_ "GenMsgTimeoutTime" BO_ 1096 500;
BA_ "GenMsgSendType" BO_ 1096 0;
BA_ "GenMsgCycleTime" BO_ 1096 10;
BA_ "GenSigTimeoutTime_FLA" SG_ 1192 BR5_Giergeschw 500;
BA_ "GenSigTimeoutMsg_FLA" SG_ 1192 BR5_Giergeschw 1192;
BA_ "GenSigTimeoutTime_ACC_Lidar" SG_ 1192 BR5_Giergeschw 500;
BA_ "GenSigTimeoutMsg_ACC_Lidar" SG_ 1192 BR5_Giergeschw 1192;
BA_ "GenSigTimeoutTime_Allrad" SG_ 1192 BR5_Giergeschw 500;
BA_ "GenSigTimeoutMsg_Allrad" SG_ 1192 BR5_Giergeschw 1192;
BA_ "GenSigTimeoutTime_PDC_PLA" SG_ 1192 BR5_Giergeschw 500;
BA_ "GenSigTimeoutMsg_PDC_PLA" SG_ 1192 BR5_Giergeschw 1192;
BA_ "GenSigTimeoutTime_SWA" SG_ 1192 BR5_Giergeschw 500;
BA_ "GenSigTimeoutMsg_SWA" SG_ 1192 BR5_Giergeschw 1192;
BA_ "GenSigTimeoutTime_HCA" SG_ 1192 BR5_Giergeschw 500;
BA_ "GenSigTimeoutMsg_HCA" SG_ 1192 BR5_Giergeschw 1192;
BA_ "GenSigTimeoutTime_Daempfer" SG_ 1192 BR5_Giergeschw 500;
BA_ "GenSigTimeoutMsg_Daempfer" SG_ 1192 BR5_Giergeschw 1192;
BA_ "GenSigTimeoutTime_RKA_Plus" SG_ 1192 BR5_Giergeschw 500;
BA_ "GenSigTimeoutMsg_RKA_Plus" SG_ 1192 BR5_Giergeschw 1192;
BA_ "GenSigTimeoutTime_Magne_Ride" SG_ 1192 BR5_Giergeschw 500;
BA_ "GenSigTimeoutMsg_Magne_Ride" SG_ 1192 BR5_Giergeschw 1192;
BA_ "GenSigTimeoutTime_AFS" SG_ 1192 BR5_Giergeschw 500;
BA_ "GenSigTimeoutMsg_AFS" SG_ 1192 BR5_Giergeschw 1192;
BA_ "GenSigTimeoutTime_ACC_Radar" SG_ 1192 BR5_Giergeschw 500;
BA_ "GenSigTimeoutMsg_ACC_Radar" SG_ 1192 BR5_Giergeschw 1192;
BA_ "GenSigTimeoutTime_EPB" SG_ 1192 BR5_Giergeschw 500;
BA_ "GenSigTimeoutMsg_EPB" SG_ 1192 BR5_Giergeschw 1192;
BA_ "GenSigSendType" SG_ 1192 BR5_Giergeschw 0;
BA_ "GenSigTimeoutTime_Otto" SG_ 1192 BR5_Bremsdruck 500;
BA_ "GenSigTimeoutMsg_Otto" SG_ 1192 BR5_Bremsdruck 1192;
BA_ "GenSigTimeoutTime_Diesel" SG_ 1192 BR5_Bremsdruck 500;
BA_ "GenSigTimeoutMsg_Diesel" SG_ 1192 BR5_Bremsdruck 1192;
BA_ "GenSigTimeoutTime_PDC_PLA" SG_ 1192 BR5_Bremsdruck 500;
BA_ "GenSigTimeoutMsg_PDC_PLA" SG_ 1192 BR5_Bremsdruck 1192;
BA_ "GenSigTimeoutTime_ACC_Lidar" SG_ 1192 BR5_Bremsdruck 500;
BA_ "GenSigTimeoutMsg_ACC_Lidar" SG_ 1192 BR5_Bremsdruck 1192;
BA_ "GenSigTimeoutTime_HCA" SG_ 1192 BR5_Bremsdruck 500;
BA_ "GenSigTimeoutMsg_HCA" SG_ 1192 BR5_Bremsdruck 1192;
BA_ "GenSigTimeoutTime_Hybrid_DQ200" SG_ 1192 BR5_Bremsdruck 500;
BA_ "GenSigTimeoutMsg_Hybrid_DQ200" SG_ 1192 BR5_Bremsdruck 1192;
BA_ "GenSigTimeoutTime_Daempfer" SG_ 1192 BR5_Bremsdruck 500;
BA_ "GenSigTimeoutMsg_Daempfer" SG_ 1192 BR5_Bremsdruck 1192;
BA_ "GenSigTimeoutTime_Magne_Ride" SG_ 1192 BR5_Bremsdruck 500;
BA_ "GenSigTimeoutMsg_Magne_Ride" SG_ 1192 BR5_Bremsdruck 1192;
BA_ "GenSigTimeoutTime_ACC_Radar" SG_ 1192 BR5_Bremsdruck 500;
BA_ "GenSigTimeoutMsg_ACC_Radar" SG_ 1192 BR5_Bremsdruck 1192;
BA_ "GenSigTimeoutTime_EPB" SG_ 1192 BR5_Bremsdruck 500;
BA_ "GenSigTimeoutMsg_EPB" SG_ 1192 BR5_Bremsdruck 1192;
BA_ "GenSigTimeoutTime_DQ" SG_ 1192 BR5_Bremsdruck 500;
BA_ "GenSigTimeoutMsg_DQ" SG_ 1192 BR5_Bremsdruck 1192;
BA_ "GenSigSendType" SG_ 1192 BR5_Bremsdruck 0;
BA_ "GenSigTimeoutTime_Otto" SG_ 1192 BR5_Sign_Druck 500;
BA_ "GenSigTimeoutMsg_Otto" SG_ 1192 BR5_Sign_Druck 1192;
BA_ "GenSigTimeoutTime_Diesel" SG_ 1192 BR5_Sign_Druck 500;
BA_ "GenSigTimeoutMsg_Diesel" SG_ 1192 BR5_Sign_Druck 1192;
BA_ "GenSigTimeoutTime_ACC_Lidar" SG_ 1192 BR5_Sign_Druck 500;
BA_ "GenSigTimeoutMsg_ACC_Lidar" SG_ 1192 BR5_Sign_Druck 1192;
BA_ "GenSigTimeoutTime_HCA" SG_ 1192 BR5_Sign_Druck 500;
BA_ "GenSigTimeoutMsg_HCA" SG_ 1192 BR5_Sign_Druck 1192;
BA_ "GenSigTimeoutTime_Hybrid_DQ200" SG_ 1192 BR5_Sign_Druck 500;
BA_ "GenSigTimeoutMsg_Hybrid_DQ200" SG_ 1192 BR5_Sign_Druck 1192;
BA_ "GenSigTimeoutTime_Daempfer" SG_ 1192 BR5_Sign_Druck 500;
BA_ "GenSigTimeoutMsg_Daempfer" SG_ 1192 BR5_Sign_Druck 1192;
BA_ "GenSigTimeoutTime_Magne_Ride" SG_ 1192 BR5_Sign_Druck 500;
BA_ "GenSigTimeoutMsg_Magne_Ride" SG_ 1192 BR5_Sign_Druck 1192;
BA_ "GenSigTimeoutTime_ACC_Radar" SG_ 1192 BR5_Sign_Druck 500;
BA_ "GenSigTimeoutMsg_ACC_Radar" SG_ 1192 BR5_Sign_Druck 1192;
BA_ "GenSigTimeoutTime_EPB" SG_ 1192 BR5_Sign_Druck 500;
BA_ "GenSigTimeoutMsg_EPB" SG_ 1192 BR5_Sign_Druck 1192;
BA_ "GenSigTimeoutTime_DQ" SG_ 1192 BR5_Sign_Druck 500;
BA_ "GenSigTimeoutMsg_DQ" SG_ 1192 BR5_Sign_Druck 1192;
BA_ "GenSigSendType" SG_ 1192 BR5_Sign_Druck 0;
BA_ "GenSigTimeoutTime_FLA" SG_ 1192 BR5_Vorzeichen 500;
BA_ "GenSigTimeoutMsg_FLA" SG_ 1192 BR5_Vorzeichen 1192;
BA_ "GenSigTimeoutTime_ACC_Lidar" SG_ 1192 BR5_Vorzeichen 500;
BA_ "GenSigTimeoutMsg_ACC_Lidar" SG_ 1192 BR5_Vorzeichen 1192;
BA_ "GenSigTimeoutTime_Allrad" SG_ 1192 BR5_Vorzeichen 500;
BA_ "GenSigTimeoutMsg_Allrad" SG_ 1192 BR5_Vorzeichen 1192;
BA_ "GenSigTimeoutTime_PDC_PLA" SG_ 1192 BR5_Vorzeichen 500;
BA_ "GenSigTimeoutMsg_PDC_PLA" SG_ 1192 BR5_Vorzeichen 1192;
BA_ "GenSigTimeoutTime_SWA" SG_ 1192 BR5_Vorzeichen 500;
BA_ "GenSigTimeoutMsg_SWA" SG_ 1192 BR5_Vorzeichen 1192;
BA_ "GenSigTimeoutTime_HCA" SG_ 1192 BR5_Vorzeichen 500;
BA_ "GenSigTimeoutMsg_HCA" SG_ 1192 BR5_Vorzeichen 1192;
BA_ "GenSigTimeoutTime_Daempfer" SG_ 1192 BR5_Vorzeichen 500;
BA_ "GenSigTimeoutMsg_Daempfer" SG_ 1192 BR5_Vorzeichen 1192;
BA_ "GenSigTimeoutTime_RKA_Plus" SG_ 1192 BR5_Vorzeichen 500;
BA_ "GenSigTimeoutMsg_RKA_Plus" SG_ 1192 BR5_Vorzeichen 1192;
BA_ "GenSigTimeoutTime_Magne_Ride" SG_ 1192 BR5_Vorzeichen 500;
BA_ "GenSigTimeoutMsg_Magne_Ride" SG_ 1192 BR5_Vorzeichen 1192;
BA_ "GenSigTimeoutTime_AFS" SG_ 1192 BR5_Vorzeichen 500;
BA_ "GenSigTimeoutMsg_AFS" SG_ 1192 BR5_Vorzeichen 1192;
BA_ "GenSigTimeoutTime_ACC_Radar" SG_ 1192 BR5_Vorzeichen 500;
BA_ "GenSigTimeoutMsg_ACC_Radar" SG_ 1192 BR5_Vorzeichen 1192;
BA_ "GenSigTimeoutTime_EPB" SG_ 1192 BR5_Vorzeichen 500;
BA_ "GenSigTimeoutMsg_EPB" SG_ 1192 BR5_Vorzeichen 1192;
BA_ "GenSigSendType" SG_ 1192 BR5_Vorzeichen 0;
BA_ "GenSigTimeoutTime_FLA" SG_ 1192 BR5_Sta_Gierrate 500;
BA_ "GenSigTimeoutMsg_FLA" SG_ 1192 BR5_Sta_Gierrate 1192;
BA_ "GenSigTimeoutTime_ACC_Lidar" SG_ 1192 BR5_Sta_Gierrate 500;
BA_ "GenSigTimeoutMsg_ACC_Lidar" SG_ 1192 BR5_Sta_Gierrate 1192;
BA_ "GenSigTimeoutTime_Allrad" SG_ 1192 BR5_Sta_Gierrate 500;
BA_ "GenSigTimeoutMsg_Allrad" SG_ 1192 BR5_Sta_Gierrate 1192;
BA_ "GenSigTimeoutTime_PDC_PLA" SG_ 1192 BR5_Sta_Gierrate 500;
BA_ "GenSigTimeoutMsg_PDC_PLA" SG_ 1192 BR5_Sta_Gierrate 1192;
BA_ "GenSigTimeoutTime_SWA" SG_ 1192 BR5_Sta_Gierrate 500;
BA_ "GenSigTimeoutMsg_SWA" SG_ 1192 BR5_Sta_Gierrate 1192;
BA_ "GenSigTimeoutTime_HCA" SG_ 1192 BR5_Sta_Gierrate 500;
BA_ "GenSigTimeoutMsg_HCA" SG_ 1192 BR5_Sta_Gierrate 1192;
BA_ "GenSigTimeoutTime_Daempfer" SG_ 1192 BR5_Sta_Gierrate 500;
BA_ "GenSigTimeoutMsg_Daempfer" SG_ 1192 BR5_Sta_Gierrate 1192;
BA_ "GenSigTimeoutTime_RKA_Plus" SG_ 1192 BR5_Sta_Gierrate 500;
BA_ "GenSigTimeoutMsg_RKA_Plus" SG_ 1192 BR5_Sta_Gierrate 1192;
BA_ "GenSigTimeoutTime_Magne_Ride" SG_ 1192 BR5_Sta_Gierrate 500;
BA_ "GenSigTimeoutMsg_Magne_Ride" SG_ 1192 BR5_Sta_Gierrate 1192;
BA_ "GenSigTimeoutTime_AFS" SG_ 1192 BR5_Sta_Gierrate 500;
BA_ "GenSigTimeoutMsg_AFS" SG_ 1192 BR5_Sta_Gierrate 1192;
BA_ "GenSigTimeoutTime_ACC_Radar" SG_ 1192 BR5_Sta_Gierrate 500;
BA_ "GenSigTimeoutMsg_ACC_Radar" SG_ 1192 BR5_Sta_Gierrate 1192;
BA_ "GenSigTimeoutTime_EPB" SG_ 1192 BR5_Sta_Gierrate 500;
BA_ "GenSigTimeoutMsg_EPB" SG_ 1192 BR5_Sta_Gierrate 1192;
BA_ "GenSigSendType" SG_ 1192 BR5_Sta_Gierrate 0;
BA_ "GenSigStartValue" SG_ 1192 BR5_Sta_Gierrate 1;
BA_ "GenSigTimeoutTime_ACC_Lidar" SG_ 1192 BR5_Stillstand 500;
BA_ "GenSigTimeoutMsg_ACC_Lidar" SG_ 1192 BR5_Stillstand 1192;
BA_ "GenSigTimeoutTime_HCA" SG_ 1192 BR5_Stillstand 500;
BA_ "GenSigTimeoutMsg_HCA" SG_ 1192 BR5_Stillstand 1192;
BA_ "GenSigTimeoutTime_Daempfer" SG_ 1192 BR5_Stillstand 500;
BA_ "GenSigTimeoutMsg_Daempfer" SG_ 1192 BR5_Stillstand 1192;
BA_ "GenSigTimeoutTime_Magne_Ride" SG_ 1192 BR5_Stillstand 500;
BA_ "GenSigTimeoutMsg_Magne_Ride" SG_ 1192 BR5_Stillstand 1192;
BA_ "GenSigTimeoutTime_ACC_Radar" SG_ 1192 BR5_Stillstand 500;
BA_ "GenSigTimeoutMsg_ACC_Radar" SG_ 1192 BR5_Stillstand 1192;
BA_ "GenSigTimeoutTime_EPB" SG_ 1192 BR5_Stillstand 500;
BA_ "GenSigTimeoutMsg_EPB" SG_ 1192 BR5_Stillstand 1192;
BA_ "GenSigSendType" SG_ 1192 BR5_Stillstand 0;
BA_ "GenSigTimeoutTime_ACC_Lidar" SG_ 1192 BR5_Sta_Druck 500;
BA_ "GenSigTimeoutMsg_ACC_Lidar" SG_ 1192 BR5_Sta_Druck 1192;
BA_ "GenSigTimeoutTime_HCA" SG_ 1192 BR5_Sta_Druck 500;
BA_ "GenSigTimeoutMsg_HCA" SG_ 1192 BR5_Sta_Druck 1192;
BA_ "GenSigTimeoutTime_Daempfer" SG_ 1192 BR5_Sta_Druck 500;
BA_ "GenSigTimeoutMsg_Daempfer" SG_ 1192 BR5_Sta_Druck 1192;
BA_ "GenSigTimeoutTime_ACC_Radar" SG_ 1192 BR5_Sta_Druck 500;
BA_ "GenSigTimeoutMsg_ACC_Radar" SG_ 1192 BR5_Sta_Druck 1192;
BA_ "GenSigTimeoutTime_EPB" SG_ 1192 BR5_Sta_Druck 500;
BA_ "GenSigTimeoutMsg_EPB" SG_ 1192 BR5_Sta_Druck 1192;
BA_ "GenSigSendType" SG_ 1192 BR5_Sta_Druck 0;
BA_ "GenSigTimeoutTime_ACC_Lidar" SG_ 1192 BR5_Zaehler 500;
BA_ "GenSigTimeoutMsg_ACC_Lidar" SG_ 1192 BR5_Zaehler 1192;
BA_ "GenSigTimeoutTime_PDC_PLA" SG_ 1192 BR5_Zaehler 500;
BA_ "GenSigTimeoutMsg_PDC_PLA" SG_ 1192 BR5_Zaehler 1192;
BA_ "GenSigTimeoutTime_SWA" SG_ 1192 BR5_Zaehler 500;
BA_ "GenSigTimeoutMsg_SWA" SG_ 1192 BR5_Zaehler 1192;
BA_ "GenSigTimeoutTime_HCA" SG_ 1192 BR5_Zaehler 500;
BA_ "GenSigTimeoutMsg_HCA" SG_ 1192 BR5_Zaehler 1192;
BA_ "GenSigTimeoutTime_Daempfer" SG_ 1192 BR5_Zaehler 500;
BA_ "GenSigTimeoutMsg_Daempfer" SG_ 1192 BR5_Zaehler 1192;
BA_ "GenSigTimeoutTime_Magne_Ride" SG_ 1192 BR5_Zaehler 500;
BA_ "GenSigTimeoutMsg_Magne_Ride" SG_ 1192 BR5_Zaehler 1192;
BA_ "GenSigTimeoutTime_ACC_Radar" SG_ 1192 BR5_Zaehler 500;
BA_ "GenSigTimeoutMsg_ACC_Radar" SG_ 1192 BR5_Zaehler 1192;
BA_ "GenSigTimeoutTime_EPB" SG_ 1192 BR5_Zaehler 500;
BA_ "GenSigTimeoutMsg_EPB" SG_ 1192 BR5_Zaehler 1192;
BA_ "GenSigSendType" SG_ 1192 BR5_Zaehler 0;
BA_ "GenSigTimeoutTime_EPB" SG_ 1192 BR5_TolAbgl_VR 500;
BA_ "GenSigTimeoutMsg_EPB" SG_ 1192 BR5_TolAbgl_VR 1192;
BA_ "GenSigTimeoutTime_ACC_Radar" SG_ 1192 BR5_TolAbgl_VR 500;
BA_ "GenSigTimeoutMsg_ACC_Radar" SG_ 1192 BR5_TolAbgl_VR 1192;
BA_ "GenSigTimeoutTime_Daempfer" SG_ 1192 BR5_TolAbgl_VR 500;
BA_ "GenSigTimeoutMsg_Daempfer" SG_ 1192 BR5_TolAbgl_VR 1192;
BA_ "GenSigTimeoutTime_HCA" SG_ 1192 BR5_TolAbgl_VR 500;
BA_ "GenSigTimeoutMsg_HCA" SG_ 1192 BR5_TolAbgl_VR 1192;
BA_ "GenSigTimeoutTime_ACC_Lidar" SG_ 1192 BR5_TolAbgl_VR 500;
BA_ "GenSigTimeoutMsg_ACC_Lidar" SG_ 1192 BR5_TolAbgl_VR 1192;
BA_ "GenSigSendType" SG_ 1192 BR5_TolAbgl_VR 0;
BA_ "GenSigStartValue" SG_ 1192 BR5_TolAbgl_VR 254;
BA_ "GenSigTimeoutTime_ACC_Lidar" SG_ 1192 BR5_Anhi_akt 500;
BA_ "GenSigTimeoutMsg_ACC_Lidar" SG_ 1192 BR5_Anhi_akt 1192;
BA_ "GenSigTimeoutTime_HCA" SG_ 1192 BR5_Anhi_akt 500;
BA_ "GenSigTimeoutMsg_HCA" SG_ 1192 BR5_Anhi_akt 1192;
BA_ "GenSigTimeoutTime_Daempfer" SG_ 1192 BR5_Anhi_akt 500;
BA_ "GenSigTimeoutMsg_Daempfer" SG_ 1192 BR5_Anhi_akt 1192;
BA_ "GenSigTimeoutTime_ACC_Radar" SG_ 1192 BR5_Anhi_akt 500;
BA_ "GenSigTimeoutMsg_ACC_Radar" SG_ 1192 BR5_Anhi_akt 1192;
BA_ "GenSigTimeoutTime_EPB" SG_ 1192 BR5_Anhi_akt 500;
BA_ "GenSigTimeoutMsg_EPB" SG_ 1192 BR5_Anhi_akt 1192;
BA_ "GenSigSendType" SG_ 1192 BR5_Anhi_akt 0;
BA_ "GenSigTimeoutTime_ACC_Lidar" SG_ 1192 BR5_Checksumme 500;
BA_ "GenSigTimeoutMsg_ACC_Lidar" SG_ 1192 BR5_Checksumme 1192;
BA_ "GenSigTimeoutTime_SWA" SG_ 1192 BR5_Checksumme 500;
BA_ "GenSigTimeoutMsg_SWA" SG_ 1192 BR5_Checksumme 1192;
BA_ "GenSigTimeoutTime_HCA" SG_ 1192 BR5_Checksumme 500;
BA_ "GenSigTimeoutMsg_HCA" SG_ 1192 BR5_Checksumme 1192;
BA_ "GenSigTimeoutTime_Daempfer" SG_ 1192 BR5_Checksumme 500;
BA_ "GenSigTimeoutMsg_Daempfer" SG_ 1192 BR5_Checksumme 1192;
BA_ "GenSigTimeoutTime_Magne_Ride" SG_ 1192 BR5_Checksumme 500;
BA_ "GenSigTimeoutMsg_Magne_Ride" SG_ 1192 BR5_Checksumme 1192;
BA_ "GenSigTimeoutTime_ACC_Radar" SG_ 1192 BR5_Checksumme 500;
BA_ "GenSigTimeoutMsg_ACC_Radar" SG_ 1192 BR5_Checksumme 1192;
BA_ "GenSigTimeoutTime_EPB" SG_ 1192 BR5_Checksumme 500;
BA_ "GenSigTimeoutMsg_EPB" SG_ 1192 BR5_Checksumme 1192;
BA_ "GenSigSendType" SG_ 1192 BR5_Checksumme 0;
BA_ "INIT" SG_ 1192 BR5_Checksumme "CHK";
BA_ "GenSigTimeoutTime_Diesel" SG_ 1192 BR5_Druckgueltig 500;
BA_ "GenSigTimeoutMsg_Diesel" SG_ 1192 BR5_Druckgueltig 1192;
BA_ "GenSigTimeoutTime_Otto" SG_ 1192 BR5_Druckgueltig 500;
BA_ "GenSigTimeoutMsg_Otto" SG_ 1192 BR5_Druckgueltig 1192;
BA_ "GenSigTimeoutTime_PDC_PLA" SG_ 1192 BR5_Druckgueltig 500;
BA_ "GenSigTimeoutMsg_PDC_PLA" SG_ 1192 BR5_Druckgueltig 1192;
BA_ "GenSigTimeoutTime_ACC_Lidar" SG_ 1192 BR5_Druckgueltig 500;
BA_ "GenSigTimeoutMsg_ACC_Lidar" SG_ 1192 BR5_Druckgueltig 1192;
BA_ "GenSigTimeoutTime_HCA" SG_ 1192 BR5_Druckgueltig 500;
BA_ "GenSigTimeoutMsg_HCA" SG_ 1192 BR5_Druckgueltig 1192;
BA_ "GenSigTimeoutTime_Hybrid_DQ200" SG_ 1192 BR5_Druckgueltig 500;
BA_ "GenSigTimeoutMsg_Hybrid_DQ200" SG_ 1192 BR5_Druckgueltig 1192;
BA_ "GenSigTimeoutTime_Daempfer" SG_ 1192 BR5_Druckgueltig 500;
BA_ "GenSigTimeoutMsg_Daempfer" SG_ 1192 BR5_Druckgueltig 1192;
BA_ "GenSigTimeoutTime_Magne_Ride" SG_ 1192 BR5_Druckgueltig 500;
BA_ "GenSigTimeoutMsg_Magne_Ride" SG_ 1192 BR5_Druckgueltig 1192;
BA_ "GenSigTimeoutTime_ACC_Radar" SG_ 1192 BR5_Druckgueltig 500;
BA_ "GenSigTimeoutMsg_ACC_Radar" SG_ 1192 BR5_Druckgueltig 1192;
BA_ "GenSigTimeoutTime_EPB" SG_ 1192 BR5_Druckgueltig 500;
BA_ "GenSigTimeoutMsg_EPB" SG_ 1192 BR5_Druckgueltig 1192;
BA_ "GenSigTimeoutTime_DQ" SG_ 1192 BR5_Druckgueltig 500;
BA_ "GenSigTimeoutMsg_DQ" SG_ 1192 BR5_Druckgueltig 1192;
BA_ "GenSigSendType" SG_ 1192 BR5_Druckgueltig 0;
BA_ "GenSigStartValue" SG_ 1192 BR5_Druckgueltig 1;
BA_ "GenSigTimeoutTime_EPB" SG_ 1192 BR5_ECD_Lampe 500;
BA_ "GenSigTimeoutMsg_EPB" SG_ 1192 BR5_ECD_Lampe 1192;
BA_ "GenSigTimeoutTime_ACC_Radar" SG_ 1192 BR5_ECD_Lampe 500;
BA_ "GenSigTimeoutMsg_ACC_Radar" SG_ 1192 BR5_ECD_Lampe 1192;
BA_ "GenSigTimeoutTime_Daempfer" SG_ 1192 BR5_ECD_Lampe 500;
BA_ "GenSigTimeoutMsg_Daempfer" SG_ 1192 BR5_ECD_Lampe 1192;
BA_ "GenSigTimeoutTime_HCA" SG_ 1192 BR5_ECD_Lampe 500;
BA_ "GenSigTimeoutMsg_HCA" SG_ 1192 BR5_ECD_Lampe 1192;
BA_ "GenSigTimeoutTime_ACC_Lidar" SG_ 1192 BR5_ECD_Lampe 500;
BA_ "GenSigTimeoutMsg_ACC_Lidar" SG_ 1192 BR5_ECD_Lampe 1192;
BA_ "GenSigSendType" SG_ 1192 BR5_ECD_Lampe 0;
BA_ "GenSigTimeoutTime_ACC_Lidar" SG_ 1192 BR5_AWV2_Bremsruck 500;
BA_ "GenSigTimeoutMsg_ACC_Lidar" SG_ 1192 BR5_AWV2_Bremsruck 1192;
BA_ "GenSigTimeoutTime_HCA" SG_ 1192 BR5_AWV2_Bremsruck 500;
BA_ "GenSigTimeoutMsg_HCA" SG_ 1192 BR5_AWV2_Bremsruck 1192;
BA_ "GenSigTimeoutTime_Daempfer" SG_ 1192 BR5_AWV2_Bremsruck 500;
BA_ "GenSigTimeoutMsg_Daempfer" SG_ 1192 BR5_AWV2_Bremsruck 1192;
BA_ "GenSigTimeoutTime_ACC_Radar" SG_ 1192 BR5_AWV2_Bremsruck 500;
BA_ "GenSigTimeoutMsg_ACC_Radar" SG_ 1192 BR5_AWV2_Bremsruck 1192;
BA_ "GenSigTimeoutTime_EPB" SG_ 1192 BR5_AWV2_Bremsruck 500;
BA_ "GenSigTimeoutMsg_EPB" SG_ 1192 BR5_AWV2_Bremsruck 1192;
BA_ "GenSigSendType" SG_ 1192 BR5_AWV2_Bremsruck 0;
BA_ "GenSigTimeoutTime_ACC_Lidar" SG_ 1192 BR5_Anhi_Sta 500;
BA_ "GenSigTimeoutMsg_ACC_Lidar" SG_ 1192 BR5_Anhi_Sta 1192;
BA_ "GenSigTimeoutTime_HCA" SG_ 1192 BR5_Anhi_Sta 500;
BA_ "GenSigTimeoutMsg_HCA" SG_ 1192 BR5_Anhi_Sta 1192;
BA_ "GenSigTimeoutTime_Daempfer" SG_ 1192 BR5_Anhi_Sta 500;
BA_ "GenSigTimeoutMsg_Daempfer" SG_ 1192 BR5_Anhi_Sta 1192;
BA_ "GenSigTimeoutTime_ACC_Radar" SG_ 1192 BR5_Anhi_Sta 500;
BA_ "GenSigTimeoutMsg_ACC_Radar" SG_ 1192 BR5_Anhi_Sta 1192;
BA_ "GenSigTimeoutTime_EPB" SG_ 1192 BR5_Anhi_Sta 500;
BA_ "GenSigTimeoutMsg_EPB" SG_ 1192 BR5_Anhi_Sta 1192;
BA_ "GenSigSendType" SG_ 1192 BR5_Anhi_Sta 0;
BA_ "GenSigTimeoutTime_EPB" SG_ 1192 BR5_Temperatur 500;
BA_ "GenSigTimeoutMsg_EPB" SG_ 1192 BR5_Temperatur 1192;
BA_ "GenSigTimeoutTime_ACC_Radar" SG_ 1192 BR5_Temperatur 500;
BA_ "GenSigTimeoutMsg_ACC_Radar" SG_ 1192 BR5_Temperatur 1192;
BA_ "GenSigTimeoutTime_Daempfer" SG_ 1192 BR5_Temperatur 500;
BA_ "GenSigTimeoutMsg_Daempfer" SG_ 1192 BR5_Temperatur 1192;
BA_ "GenSigTimeoutTime_HCA" SG_ 1192 BR5_Temperatur 500;
BA_ "GenSigTimeoutMsg_HCA" SG_ 1192 BR5_Temperatur 1192;
BA_ "GenSigTimeoutTime_ACC_Lidar" SG_ 1192 BR5_Temperatur 500;
BA_ "GenSigTimeoutMsg_ACC_Lidar" SG_ 1192 BR5_Temperatur 1192;
BA_ "GenSigSendType" SG_ 1192 BR5_Temperatur 0;
BA_ "GenSigTimeoutTime_EPB" SG_ 1192 BR5_v_Ueberw 500;
BA_ "GenSigTimeoutMsg_EPB" SG_ 1192 BR5_v_Ueberw 1192;
BA_ "GenSigTimeoutTime_ACC_Radar" SG_ 1192 BR5_v_Ueberw 500;
BA_ "GenSigTimeoutMsg_ACC_Radar" SG_ 1192 BR5_v_Ueberw 1192;
BA_ "GenSigTimeoutTime_Daempfer" SG_ 1192 BR5_v_Ueberw 500;
BA_ "GenSigTimeoutMsg_Daempfer" SG_ 1192 BR5_v_Ueberw 1192;
BA_ "GenSigTimeoutTime_HCA" SG_ 1192 BR5_v_Ueberw 500;
BA_ "GenSigTimeoutMsg_HCA" SG_ 1192 BR5_v_Ueberw 1192;
BA_ "GenSigTimeoutTime_ACC_Lidar" SG_ 1192 BR5_v_Ueberw 500;
BA_ "GenSigTimeoutMsg_ACC_Lidar" SG_ 1192 BR5_v_Ueberw 1192;
BA_ "GenSigSendType" SG_ 1192 BR5_v_Ueberw 0;
BA_ "GenSigTimeoutTime_ACC_Lidar" SG_ 1192 BR5_AnhStabAktiv 500;
BA_ "GenSigTimeoutMsg_ACC_Lidar" SG_ 1192 BR5_AnhStabAktiv 1192;
BA_ "GenSigTimeoutTime_HCA" SG_ 1192 BR5_AnhStabAktiv 500;
BA_ "GenSigTimeoutMsg_HCA" SG_ 1192 BR5_AnhStabAktiv 1192;
BA_ "GenSigTimeoutTime_Daempfer" SG_ 1192 BR5_AnhStabAktiv 500;
BA_ "GenSigTimeoutMsg_Daempfer" SG_ 1192 BR5_AnhStabAktiv 1192;
BA_ "GenSigTimeoutTime_Gateway_PQ35_A" SG_ 1192 BR5_AnhStabAktiv 500;
BA_ "GenSigTimeoutMsg_Gateway_PQ35_A" SG_ 1192 BR5_AnhStabAktiv 1192;
BA_ "GenSigTimeoutTime_ACC_Radar" SG_ 1192 BR5_AnhStabAktiv 500;
BA_ "GenSigTimeoutMsg_ACC_Radar" SG_ 1192 BR5_AnhStabAktiv 1192;
BA_ "GenSigTimeoutTime_EPB" SG_ 1192 BR5_AnhStabAktiv 500;
BA_ "GenSigTimeoutMsg_EPB" SG_ 1192 BR5_AnhStabAktiv 1192;
BA_ "GenSigTimeoutTime_Gateway_PQ46_A" SG_ 1192 BR5_AnhStabAktiv 500;
BA_ "GenSigTimeoutMsg_Gateway_PQ46_A" SG_ 1192 BR5_AnhStabAktiv 1192;
BA_ "GenSigSendType" SG_ 1192 BR5_AnhStabAktiv 0;
BA_ "GenSigTimeoutTime_ACC_Lidar" SG_ 1192 BR5_Notbremsung 500;
BA_ "GenSigTimeoutMsg_ACC_Lidar" SG_ 1192 BR5_Notbremsung 1192;
BA_ "GenSigTimeoutTime_HCA" SG_ 1192 BR5_Notbremsung 500;
BA_ "GenSigTimeoutMsg_HCA" SG_ 1192 BR5_Notbremsung 1192;
BA_ "GenSigTimeoutTime_Daempfer" SG_ 1192 BR5_Notbremsung 500;
BA_ "GenSigTimeoutMsg_Daempfer" SG_ 1192 BR5_Notbremsung 1192;
BA_ "GenSigTimeoutTime_Gateway_PQ35_A" SG_ 1192 BR5_Notbremsung 500;
BA_ "GenSigTimeoutMsg_Gateway_PQ35_A" SG_ 1192 BR5_Notbremsung 1192;
BA_ "GenSigTimeoutTime_ACC_Radar" SG_ 1192 BR5_Notbremsung 500;
BA_ "GenSigTimeoutMsg_ACC_Radar" SG_ 1192 BR5_Notbremsung 1192;
BA_ "GenSigTimeoutTime_EPB" SG_ 1192 BR5_Notbremsung 500;
BA_ "GenSigTimeoutMsg_EPB" SG_ 1192 BR5_Notbremsung 1192;
BA_ "GenSigTimeoutTime_Gateway_PQ46_A" SG_ 1192 BR5_Notbremsung 500;
BA_ "GenSigTimeoutMsg_Gateway_PQ46_A" SG_ 1192 BR5_Notbremsung 1192;
BA_ "GenSigSendType" SG_ 1192 BR5_Notbremsung 0;
BA_ "GenSigTimeoutTime_ACC_Lidar" SG_ 1192 BR5_AWV2_Fehler 500;
BA_ "GenSigTimeoutMsg_ACC_Lidar" SG_ 1192 BR5_AWV2_Fehler 1192;
BA_ "GenSigTimeoutTime_HCA" SG_ 1192 BR5_AWV2_Fehler 500;
BA_ "GenSigTimeoutMsg_HCA" SG_ 1192 BR5_AWV2_Fehler 1192;
BA_ "GenSigTimeoutTime_Daempfer" SG_ 1192 BR5_AWV2_Fehler 500;
BA_ "GenSigTimeoutMsg_Daempfer" SG_ 1192 BR5_AWV2_Fehler 1192;
BA_ "GenSigTimeoutTime_ACC_Radar" SG_ 1192 BR5_AWV2_Fehler 500;
BA_ "GenSigTimeoutMsg_ACC_Radar" SG_ 1192 BR5_AWV2_Fehler 1192;
BA_ "GenSigTimeoutTime_EPB" SG_ 1192 BR5_AWV2_Fehler 500;
BA_ "GenSigTimeoutMsg_EPB" SG_ 1192 BR5_AWV2_Fehler 1192;
BA_ "GenSigSendType" SG_ 1192 BR5_AWV2_Fehler 0;
BA_ "GenSigTimeoutTime_EPB" SG_ 1192 BR5_ECD_Rueckfall 500;
BA_ "GenSigTimeoutMsg_EPB" SG_ 1192 BR5_ECD_Rueckfall 1192;
BA_ "GenSigTimeoutTime_ACC_Radar" SG_ 1192 BR5_ECD_Rueckfall 500;
BA_ "GenSigTimeoutMsg_ACC_Radar" SG_ 1192 BR5_ECD_Rueckfall 1192;
BA_ "GenSigTimeoutTime_Daempfer" SG_ 1192 BR5_ECD_Rueckfall 500;
BA_ "GenSigTimeoutMsg_Daempfer" SG_ 1192 BR5_ECD_Rueckfall 1192;
BA_ "GenSigTimeoutTime_HCA" SG_ 1192 BR5_ECD_Rueckfall 500;
BA_ "GenSigTimeoutMsg_HCA" SG_ 1192 BR5_ECD_Rueckfall 1192;
BA_ "GenSigTimeoutTime_ACC_Lidar" SG_ 1192 BR5_ECD_Rueckfall 500;
BA_ "GenSigTimeoutMsg_ACC_Lidar" SG_ 1192 BR5_ECD_Rueckfall 1192;
BA_ "GenSigSendType" SG_ 1192 BR5_ECD_Rueckfall 0;
BA_ "GenSigTimeoutTime_Gateway_PQ35_A" SG_ 672 BR4_Vorgabe_Hi 500;
BA_ "GenSigTimeoutMsg_Gateway_PQ35_A" SG_ 672 BR4_Vorgabe_Hi 672;
BA_ "GenSigTimeoutTime_Gateway_PQ46_A" SG_ 672 BR4_Vorgabe_Hi 500;
BA_ "GenSigTimeoutMsg_Gateway_PQ46_A" SG_ 672 BR4_Vorgabe_Hi 672;
BA_ "GenSigSendType" SG_ 672 BR4_Vorgabe_Hi 0;
BA_ "GenSigStartValue" SG_ 672 BR4_Vorgabe_Hi 127;
BA_ "GenSigTimeoutTime_VAQ" SG_ 672 BR4_Einheit 500;
BA_ "GenSigTimeoutMsg_VAQ" SG_ 672 BR4_Einheit 672;
BA_ "GenSigTimeoutTime_Gateway_PQ35_A" SG_ 672 BR4_Einheit 500;
BA_ "GenSigTimeoutMsg_Gateway_PQ35_A" SG_ 672 BR4_Einheit 672;
BA_ "GenSigTimeoutTime_Allrad" SG_ 672 BR4_Einheit 500;
BA_ "GenSigTimeoutMsg_Allrad" SG_ 672 BR4_Einheit 672;
BA_ "GenSigTimeoutTime_Gateway_PQ46_A" SG_ 672 BR4_Einheit 500;
BA_ "GenSigTimeoutMsg_Gateway_PQ46_A" SG_ 672 BR4_Einheit 672;
BA_ "GenSigSendType" SG_ 672 BR4_Einheit 0;
BA_ "INIT" SG_ 672 BR4_Einheit "const";
BA_ "GenSigTimeoutTime_Gateway_PQ35_A" SG_ 672 BR4_Vorgabe_Mi 500;
BA_ "GenSigTimeoutMsg_Gateway_PQ35_A" SG_ 672 BR4_Vorgabe_Mi 672;
BA_ "GenSigTimeoutTime_Gateway_PQ46_A" SG_ 672 BR4_Vorgabe_Mi 500;
BA_ "GenSigTimeoutMsg_Gateway_PQ46_A" SG_ 672 BR4_Vorgabe_Mi 672;
BA_ "GenSigSendType" SG_ 672 BR4_Vorgabe_Mi 0;
BA_ "GenSigStartValue" SG_ 672 BR4_Vorgabe_Mi 127;
BA_ "GenSigTimeoutTime_Gateway_PQ35_A" SG_ 672 BR4_Abschaltung_HL 500;
BA_ "GenSigTimeoutMsg_Gateway_PQ35_A" SG_ 672 BR4_Abschaltung_HL 672;
BA_ "GenSigTimeoutTime_Gateway_PQ46_A" SG_ 672 BR4_Abschaltung_HL 500;
BA_ "GenSigTimeoutMsg_Gateway_PQ46_A" SG_ 672 BR4_Abschaltung_HL 672;
BA_ "GenSigSendType" SG_ 672 BR4_Abschaltung_HL 0;
BA_ "GenSigTimeoutTime_Gateway_PQ35_A" SG_ 672 BR4_Vorgabe_Mi_ 500;
BA_ "GenSigTimeoutMsg_Gateway_PQ35_A" SG_ 672 BR4_Vorgabe_Mi_ 672;
BA_ "GenSigTimeoutTime_Allrad" SG_ 672 BR4_Vorgabe_Mi_ 500;
BA_ "GenSigTimeoutMsg_Allrad" SG_ 672 BR4_Vorgabe_Mi_ 672;
BA_ "GenSigTimeoutTime_Gateway_PQ46_A" SG_ 672 BR4_Vorgabe_Mi_ 500;
BA_ "GenSigTimeoutMsg_Gateway_PQ46_A" SG_ 672 BR4_Vorgabe_Mi_ 672;
BA_ "GenSigSendType" SG_ 672 BR4_Vorgabe_Mi_ 0;
BA_ "GenSigTimeoutTime_Gateway_PQ35_A" SG_ 672 BR4_Abschaltung_HR 500;
BA_ "GenSigTimeoutMsg_Gateway_PQ35_A" SG_ 672 BR4_Abschaltung_HR 672;
BA_ "GenSigTimeoutTime_Gateway_PQ46_A" SG_ 672 BR4_Abschaltung_HR 500;
BA_ "GenSigTimeoutMsg_Gateway_PQ46_A" SG_ 672 BR4_Abschaltung_HR 672;
BA_ "GenSigSendType" SG_ 672 BR4_Abschaltung_HR 0;
BA_ "GenSigTimeoutTime_Gateway_PQ35_A" SG_ 672 BR4_Abschaltung_VL 500;
BA_ "GenSigTimeoutMsg_Gateway_PQ35_A" SG_ 672 BR4_Abschaltung_VL 672;
BA_ "GenSigTimeoutTime_Gateway_PQ46_A" SG_ 672 BR4_Abschaltung_VL 500;
BA_ "GenSigTimeoutMsg_Gateway_PQ46_A" SG_ 672 BR4_Abschaltung_VL 672;
BA_ "GenSigSendType" SG_ 672 BR4_Abschaltung_VL 0;
BA_ "GenSigTimeoutTime_Gateway_PQ35_A" SG_ 672 BR4_Abschaltung_VR 500;
BA_ "GenSigTimeoutMsg_Gateway_PQ35_A" SG_ 672 BR4_Abschaltung_VR 672;
BA_ "GenSigTimeoutTime_Gateway_PQ46_A" SG_ 672 BR4_Abschaltung_VR 500;
BA_ "GenSigTimeoutMsg_Gateway_PQ46_A" SG_ 672 BR4_Abschaltung_VR 672;
BA_ "GenSigSendType" SG_ 672 BR4_Abschaltung_VR 0;
BA_ "GenSigTimeoutTime_Gateway_PQ35_A" SG_ 672 BR4_Lampe_RKA 500;
BA_ "GenSigTimeoutMsg_Gateway_PQ35_A" SG_ 672 BR4_Lampe_RKA 672;
BA_ "GenSigTimeoutTime_Gateway_PQ46_A" SG_ 672 BR4_Lampe_RKA 500;
BA_ "GenSigTimeoutMsg_Gateway_PQ46_A" SG_ 672 BR4_Lampe_RKA 672;
BA_ "GenSigSendType" SG_ 672 BR4_Lampe_RKA 0;
BA_ "GenSigTimeoutTime_Gateway_PQ35_A" SG_ 672 BR4_Summer_RKA 500;
BA_ "GenSigTimeoutMsg_Gateway_PQ35_A" SG_ 672 BR4_Summer_RKA 672;
BA_ "GenSigTimeoutTime_Gateway_PQ46_A" SG_ 672 BR4_Summer_RKA 500;
BA_ "GenSigTimeoutMsg_Gateway_PQ46_A" SG_ 672 BR4_Summer_RKA 672;
BA_ "GenSigSendType" SG_ 672 BR4_Summer_RKA 0;
BA_ "GenSigTimeoutTime_Hybrid_MSG" SG_ 672 BR4_Unterdruck 500;
BA_ "GenSigTimeoutMsg_Hybrid_MSG" SG_ 672 BR4_Unterdruck 672;
BA_ "GenSigTimeoutTime_Gateway_PQ35_A" SG_ 672 BR4_Unterdruck 500;
BA_ "GenSigTimeoutMsg_Gateway_PQ35_A" SG_ 672 BR4_Unterdruck 672;
BA_ "GenSigTimeoutTime_Otto" SG_ 672 BR4_Unterdruck 500;
BA_ "GenSigTimeoutMsg_Otto" SG_ 672 BR4_Unterdruck 672;
BA_ "GenSigTimeoutTime_Gateway_PQ46_A" SG_ 672 BR4_Unterdruck 500;
BA_ "GenSigTimeoutMsg_Gateway_PQ46_A" SG_ 672 BR4_Unterdruck 672;
BA_ "GenSigTimeoutTime_AG6" SG_ 672 BR4_Unterdruck 500;
BA_ "GenSigTimeoutMsg_AG6" SG_ 672 BR4_Unterdruck 672;
BA_ "GenSigSendType" SG_ 672 BR4_Unterdruck 0;
BA_ "GenSigTimeoutTime_VAQ" SG_ 672 BR4_Status_ESP 500;
BA_ "GenSigTimeoutMsg_VAQ" SG_ 672 BR4_Status_ESP 672;
BA_ "GenSigTimeoutTime_Gateway_PQ35_A" SG_ 672 BR4_Status_ESP 500;
BA_ "GenSigTimeoutMsg_Gateway_PQ35_A" SG_ 672 BR4_Status_ESP 672;
BA_ "GenSigTimeoutTime_Gateway_PQ46_A" SG_ 672 BR4_Status_ESP 500;
BA_ "GenSigTimeoutMsg_Gateway_PQ46_A" SG_ 672 BR4_Status_ESP 672;
BA_ "GenSigSendType" SG_ 672 BR4_Status_ESP 0;
BA_ "GenSigStartValue" SG_ 672 BR4_Status_ESP 1;
BA_ "GenSigTimeoutTime_VAQ" SG_ 672 BR4_Checksum 500;
BA_ "GenSigTimeoutMsg_VAQ" SG_ 672 BR4_Checksum 672;
BA_ "GenSigTimeoutTime_Gateway_PQ35_A" SG_ 672 BR4_Checksum 500;
BA_ "GenSigTimeoutMsg_Gateway_PQ35_A" SG_ 672 BR4_Checksum 672;
BA_ "GenSigTimeoutTime_Gateway_PQ46_A" SG_ 672 BR4_Checksum 500;
BA_ "GenSigTimeoutMsg_Gateway_PQ46_A" SG_ 672 BR4_Checksum 672;
BA_ "GenSigSendType" SG_ 672 BR4_Checksum 0;
BA_ "INIT" SG_ 672 BR4_Checksum "CHK";
BA_ "GenSigTimeoutTime_Gateway_PQ35_A" SG_ 672 BR4_Reserve2 500;
BA_ "GenSigTimeoutMsg_Gateway_PQ35_A" SG_ 672 BR4_Reserve2 672;
BA_ "GenSigTimeoutTime_Gateway_PQ46_A" SG_ 672 BR4_Reserve2 500;
BA_ "GenSigTimeoutMsg_Gateway_PQ46_A" SG_ 672 BR4_Reserve2 672;
BA_ "GenSigSendType" SG_ 672 BR4_Reserve2 0;
BA_ "GenSigTimeoutTime_VAQ" SG_ 672 BR4_Zaehler 500;
BA_ "GenSigTimeoutMsg_VAQ" SG_ 672 BR4_Zaehler 672;
BA_ "GenSigTimeoutTime_Gateway_PQ35_A" SG_ 672 BR4_Zaehler 500;
BA_ "GenSigTimeoutMsg_Gateway_PQ35_A" SG_ 672 BR4_Zaehler 672;
BA_ "GenSigTimeoutTime_Gateway_PQ46_A" SG_ 672 BR4_Zaehler 500;
BA_ "GenSigTimeoutMsg_Gateway_PQ46_A" SG_ 672 BR4_Zaehler 672;
BA_ "GenSigSendType" SG_ 672 BR4_Zaehler 0;
BA_ "GenSigTimeoutTime_Hybrid_MSG" SG_ 672 BR4_Schwelle 500;
BA_ "GenSigTimeoutMsg_Hybrid_MSG" SG_ 672 BR4_Schwelle 672;
BA_ "GenSigTimeoutTime_Gateway_PQ35_A" SG_ 672 BR4_Schwelle 500;
BA_ "GenSigTimeoutMsg_Gateway_PQ35_A" SG_ 672 BR4_Schwelle 672;
BA_ "GenSigTimeoutTime_Otto" SG_ 672 BR4_Schwelle 500;
BA_ "GenSigTimeoutMsg_Otto" SG_ 672 BR4_Schwelle 672;
BA_ "GenSigTimeoutTime_Gateway_PQ46_A" SG_ 672 BR4_Schwelle 500;
BA_ "GenSigTimeoutMsg_Gateway_PQ46_A" SG_ 672 BR4_Schwelle 672;
BA_ "GenSigTimeoutTime_AG6" SG_ 672 BR4_Schwelle 500;
BA_ "GenSigTimeoutMsg_AG6" SG_ 672 BR4_Schwelle 672;
BA_ "GenSigSendType" SG_ 672 BR4_Schwelle 0;
BA_ "GenSigTimeoutTime_Gateway_PQ35_A" SG_ 672 BR4_res_42 500;
BA_ "GenSigTimeoutMsg_Gateway_PQ35_A" SG_ 672 BR4_res_42 672;
BA_ "GenSigTimeoutTime_Gateway_PQ46_A" SG_ 672 BR4_res_42 500;
BA_ "GenSigTimeoutMsg_Gateway_PQ46_A" SG_ 672 BR4_res_42 672;
BA_ "GenSigSendType" SG_ 672 BR4_res_42 0;
BA_ "GenSigTimeoutTime_Gateway_PQ35_A" SG_ 672 BR4_res_48 500;
BA_ "GenSigTimeoutMsg_Gateway_PQ35_A" SG_ 672 BR4_res_48 672;
BA_ "GenSigTimeoutTime_Gateway_PQ46_A" SG_ 672 BR4_res_48 500;
BA_ "GenSigTimeoutMsg_Gateway_PQ46_A" SG_ 672 BR4_res_48 672;
BA_ "GenSigSendType" SG_ 672 BR4_res_48 0;
BA_ "GenSigTimeoutTime_VAQ" SG_ 672 BR4_Vorgabe_Min 500;
BA_ "GenSigTimeoutMsg_VAQ" SG_ 672 BR4_Vorgabe_Min 672;
BA_ "GenSigTimeoutTime_Gateway_PQ35_A" SG_ 672 BR4_Vorgabe_Min 500;
BA_ "GenSigTimeoutMsg_Gateway_PQ35_A" SG_ 672 BR4_Vorgabe_Min 672;
BA_ "GenSigTimeoutTime_Gateway_PQ46_A" SG_ 672 BR4_Vorgabe_Min 500;
BA_ "GenSigTimeoutMsg_Gateway_PQ46_A" SG_ 672 BR4_Vorgabe_Min 672;
BA_ "GenSigSendType" SG_ 672 BR4_Vorgabe_Min 0;
BA_ "GenSigTimeoutTime_VAQ" SG_ 672 BR4_Vorgabe_Max 500;
BA_ "GenSigTimeoutMsg_VAQ" SG_ 672 BR4_Vorgabe_Max 672;
BA_ "GenSigTimeoutTime_Gateway_PQ35_A" SG_ 672 BR4_Vorgabe_Max 500;
BA_ "GenSigTimeoutMsg_Gateway_PQ35_A" SG_ 672 BR4_Vorgabe_Max 672;
BA_ "GenSigTimeoutTime_Gateway_PQ46_A" SG_ 672 BR4_Vorgabe_Max 500;
BA_ "GenSigTimeoutMsg_Gateway_PQ46_A" SG_ 672 BR4_Vorgabe_Max 672;
BA_ "GenSigSendType" SG_ 672 BR4_Vorgabe_Max 0;
BA_ "GenSigTimeoutTime_Otto" SG_ 428 BR8_Laengsbeschl 500;
BA_ "GenSigTimeoutMsg_Otto" SG_ 428 BR8_Laengsbeschl 428;
BA_ "GenSigTimeoutTime_ACC_Lidar" SG_ 428 BR8_Laengsbeschl 500;
BA_ "GenSigTimeoutMsg_ACC_Lidar" SG_ 428 BR8_Laengsbeschl 428;
BA_ "GenSigTimeoutTime_Gateway_PQ35_A" SG_ 428 BR8_Laengsbeschl 500;
BA_ "GenSigTimeoutMsg_Gateway_PQ35_A" SG_ 428 BR8_Laengsbeschl 428;
BA_ "GenSigTimeoutTime_Hybrid_DQ200" SG_ 428 BR8_Laengsbeschl 500;
BA_ "GenSigTimeoutMsg_Hybrid_DQ200" SG_ 428 BR8_Laengsbeschl 428;
BA_ "GenSigTimeoutTime_PDC_PLA" SG_ 428 BR8_Laengsbeschl 500;
BA_ "GenSigTimeoutMsg_PDC_PLA" SG_ 428 BR8_Laengsbeschl 428;
BA_ "GenSigTimeoutTime_ACC_Radar" SG_ 428 BR8_Laengsbeschl 500;
BA_ "GenSigTimeoutMsg_ACC_Radar" SG_ 428 BR8_Laengsbeschl 428;
BA_ "GenSigTimeoutTime_EPB" SG_ 428 BR8_Laengsbeschl 500;
BA_ "GenSigTimeoutMsg_EPB" SG_ 428 BR8_Laengsbeschl 428;
BA_ "GenSigTimeoutTime_DQ" SG_ 428 BR8_Laengsbeschl 500;
BA_ "GenSigTimeoutMsg_DQ" SG_ 428 BR8_Laengsbeschl 428;
BA_ "GenSigTimeoutTime_Diesel" SG_ 428 BR8_Laengsbeschl 500;
BA_ "GenSigTimeoutMsg_Diesel" SG_ 428 BR8_Laengsbeschl 428;
BA_ "GenSigTimeoutTime_AG6" SG_ 428 BR8_Laengsbeschl 500;
BA_ "GenSigTimeoutMsg_AG6" SG_ 428 BR8_Laengsbeschl 428;
BA_ "GenSigSendType" SG_ 428 BR8_Laengsbeschl 0;
BA_ "GenSigTimeoutTime_ACC_Lidar" SG_ 428 BR8_Checksumme 500;
BA_ "GenSigTimeoutMsg_ACC_Lidar" SG_ 428 BR8_Checksumme 428;
BA_ "GenSigTimeoutTime_Gateway_PQ35_A" SG_ 428 BR8_Checksumme 500;
BA_ "GenSigTimeoutMsg_Gateway_PQ35_A" SG_ 428 BR8_Checksumme 428;
BA_ "GenSigTimeoutTime_Hybrid_DQ200" SG_ 428 BR8_Checksumme 500;
BA_ "GenSigTimeoutMsg_Hybrid_DQ200" SG_ 428 BR8_Checksumme 428;
BA_ "GenSigTimeoutTime_PDC_PLA" SG_ 428 BR8_Checksumme 500;
BA_ "GenSigTimeoutMsg_PDC_PLA" SG_ 428 BR8_Checksumme 428;
BA_ "GenSigTimeoutTime_ACC_Radar" SG_ 428 BR8_Checksumme 500;
BA_ "GenSigTimeoutMsg_ACC_Radar" SG_ 428 BR8_Checksumme 428;
BA_ "GenSigTimeoutTime_EPB" SG_ 428 BR8_Checksumme 500;
BA_ "GenSigTimeoutMsg_EPB" SG_ 428 BR8_Checksumme 428;
BA_ "GenSigTimeoutTime_DQ" SG_ 428 BR8_Checksumme 500;
BA_ "GenSigTimeoutMsg_DQ" SG_ 428 BR8_Checksumme 428;
BA_ "GenSigTimeoutTime_Diesel" SG_ 428 BR8_Checksumme 500;
BA_ "GenSigTimeoutMsg_Diesel" SG_ 428 BR8_Checksumme 428;
BA_ "GenSigTimeoutTime_AG6" SG_ 428 BR8_Checksumme 500;
BA_ "GenSigTimeoutMsg_AG6" SG_ 428 BR8_Checksumme 428;
BA_ "GenSigSendType" SG_ 428 BR8_Checksumme 0;
BA_ "INIT" SG_ 428 BR8_Checksumme "CHK";
BA_ "GenSigTimeoutTime_ACC_Lidar" SG_ 428 BR8_Sta_Br_Druck 500;
BA_ "GenSigTimeoutMsg_ACC_Lidar" SG_ 428 BR8_Sta_Br_Druck 428;
BA_ "GenSigTimeoutTime_Gateway_PQ35_A" SG_ 428 BR8_Sta_Br_Druck 500;
BA_ "GenSigTimeoutMsg_Gateway_PQ35_A" SG_ 428 BR8_Sta_Br_Druck 428;
BA_ "GenSigTimeoutTime_ACC_Radar" SG_ 428 BR8_Sta_Br_Druck 500;
BA_ "GenSigTimeoutMsg_ACC_Radar" SG_ 428 BR8_Sta_Br_Druck 428;
BA_ "GenSigTimeoutTime_EPB" SG_ 428 BR8_Sta_Br_Druck 500;
BA_ "GenSigTimeoutMsg_EPB" SG_ 428 BR8_Sta_Br_Druck 428;
BA_ "GenSigTimeoutTime_Diesel" SG_ 428 BR8_Sta_Br_Druck 500;
BA_ "GenSigTimeoutMsg_Diesel" SG_ 428 BR8_Sta_Br_Druck 428;
BA_ "GenSigSendType" SG_ 428 BR8_Sta_Br_Druck 0;
BA_ "GenSigTimeoutTime_Diesel" SG_ 428 BR8_QB_LBeschl 500;
BA_ "GenSigTimeoutMsg_Diesel" SG_ 428 BR8_QB_LBeschl 428;
BA_ "GenSigTimeoutTime_Otto" SG_ 428 BR8_QB_LBeschl 500;
BA_ "GenSigTimeoutMsg_Otto" SG_ 428 BR8_QB_LBeschl 428;
BA_ "GenSigTimeoutTime_ACC_Lidar" SG_ 428 BR8_QB_LBeschl 500;
BA_ "GenSigTimeoutMsg_ACC_Lidar" SG_ 428 BR8_QB_LBeschl 428;
BA_ "GenSigTimeoutTime_Gateway_PQ35_A" SG_ 428 BR8_QB_LBeschl 500;
BA_ "GenSigTimeoutMsg_Gateway_PQ35_A" SG_ 428 BR8_QB_LBeschl 428;
BA_ "GenSigTimeoutTime_PDC_PLA" SG_ 428 BR8_QB_LBeschl 500;
BA_ "GenSigTimeoutMsg_PDC_PLA" SG_ 428 BR8_QB_LBeschl 428;
BA_ "GenSigTimeoutTime_ACC_Radar" SG_ 428 BR8_QB_LBeschl 500;
BA_ "GenSigTimeoutMsg_ACC_Radar" SG_ 428 BR8_QB_LBeschl 428;
BA_ "GenSigTimeoutTime_EPB" SG_ 428 BR8_QB_LBeschl 500;
BA_ "GenSigTimeoutMsg_EPB" SG_ 428 BR8_QB_LBeschl 428;
BA_ "GenSigSendType" SG_ 428 BR8_QB_LBeschl 0;
BA_ "GenSigStartValue" SG_ 428 BR8_QB_LBeschl 1;
BA_ "GenSigTimeoutTime_ACC_Lidar" SG_ 428 BR8_Istbeschl 500;
BA_ "GenSigTimeoutMsg_ACC_Lidar" SG_ 428 BR8_Istbeschl 428;
BA_ "GenSigTimeoutTime_Gateway_PQ35_A" SG_ 428 BR8_Istbeschl 500;
BA_ "GenSigTimeoutMsg_Gateway_PQ35_A" SG_ 428 BR8_Istbeschl 428;
BA_ "GenSigTimeoutTime_ACC_Radar" SG_ 428 BR8_Istbeschl 500;
BA_ "GenSigTimeoutMsg_ACC_Radar" SG_ 428 BR8_Istbeschl 428;
BA_ "GenSigTimeoutTime_EPB" SG_ 428 BR8_Istbeschl 500;
BA_ "GenSigTimeoutMsg_EPB" SG_ 428 BR8_Istbeschl 428;
BA_ "GenSigTimeoutTime_Otto" SG_ 428 BR8_Istbeschl 500;
BA_ "GenSigTimeoutMsg_Otto" SG_ 428 BR8_Istbeschl 428;
BA_ "GenSigTimeoutTime_Diesel" SG_ 428 BR8_Istbeschl 500;
BA_ "GenSigTimeoutMsg_Diesel" SG_ 428 BR8_Istbeschl 428;
BA_ "GenSigSendType" SG_ 428 BR8_Istbeschl 0;
BA_ "GenSigStartValue" SG_ 428 BR8_Istbeschl 361;
BA_ "GenSigTimeoutTime_ACC_Lidar" SG_ 428 BR8_Zaehler 500;
BA_ "GenSigTimeoutMsg_ACC_Lidar" SG_ 428 BR8_Zaehler 428;
BA_ "GenSigTimeoutTime_Gateway_PQ35_A" SG_ 428 BR8_Zaehler 500;
BA_ "GenSigTimeoutMsg_Gateway_PQ35_A" SG_ 428 BR8_Zaehler 428;
BA_ "GenSigTimeoutTime_PDC_PLA" SG_ 428 BR8_Zaehler 500;
BA_ "GenSigTimeoutMsg_PDC_PLA" SG_ 428 BR8_Zaehler 428;
BA_ "GenSigTimeoutTime_ACC_Radar" SG_ 428 BR8_Zaehler 500;
BA_ "GenSigTimeoutMsg_ACC_Radar" SG_ 428 BR8_Zaehler 428;
BA_ "GenSigTimeoutTime_EPB" SG_ 428 BR8_Zaehler 500;
BA_ "GenSigTimeoutMsg_EPB" SG_ 428 BR8_Zaehler 428;
BA_ "GenSigTimeoutTime_Diesel" SG_ 428 BR8_Zaehler 500;
BA_ "GenSigTimeoutMsg_Diesel" SG_ 428 BR8_Zaehler 428;
BA_ "GenSigTimeoutTime_AG6" SG_ 428 BR8_Zaehler 500;
BA_ "GenSigTimeoutMsg_AG6" SG_ 428 BR8_Zaehler 428;
BA_ "GenSigSendType" SG_ 428 BR8_Zaehler 0;
BA_ "GenSigTimeoutTime_ACC_Lidar" SG_ 428 BR8_Check_EPB 500;
BA_ "GenSigTimeoutMsg_ACC_Lidar" SG_ 428 BR8_Check_EPB 428;
BA_ "GenSigTimeoutTime_Gateway_PQ35_A" SG_ 428 BR8_Check_EPB 500;
BA_ "GenSigTimeoutMsg_Gateway_PQ35_A" SG_ 428 BR8_Check_EPB 428;
BA_ "GenSigTimeoutTime_ACC_Radar" SG_ 428 BR8_Check_EPB 500;
BA_ "GenSigTimeoutMsg_ACC_Radar" SG_ 428 BR8_Check_EPB 428;
BA_ "GenSigTimeoutTime_EPB" SG_ 428 BR8_Check_EPB 500;
BA_ "GenSigTimeoutMsg_EPB" SG_ 428 BR8_Check_EPB 428;
BA_ "GenSigSendType" SG_ 428 BR8_Check_EPB 0;
BA_ "GenSigStartValue" SG_ 428 BR8_Check_EPB 1;
BA_ "GenSigTimeoutTime_EPB" SG_ 428 BR8_TolAbgl_HL 500;
BA_ "GenSigTimeoutMsg_EPB" SG_ 428 BR8_TolAbgl_HL 428;
BA_ "GenSigTimeoutTime_ACC_Radar" SG_ 428 BR8_TolAbgl_HL 500;
BA_ "GenSigTimeoutMsg_ACC_Radar" SG_ 428 BR8_TolAbgl_HL 428;
BA_ "GenSigTimeoutTime_ACC_Lidar" SG_ 428 BR8_TolAbgl_HL 500;
BA_ "GenSigTimeoutMsg_ACC_Lidar" SG_ 428 BR8_TolAbgl_HL 428;
BA_ "GenSigTimeoutTime_Gateway_PQ35_A" SG_ 428 BR8_TolAbgl_HL 500;
BA_ "GenSigTimeoutMsg_Gateway_PQ35_A" SG_ 428 BR8_TolAbgl_HL 428;
BA_ "GenSigSendType" SG_ 428 BR8_TolAbgl_HL 0;
BA_ "GenSigStartValue" SG_ 428 BR8_TolAbgl_HL 254;
BA_ "GenSigTimeoutTime_EPB" SG_ 428 BR8_TolAbgl_HR 500;
BA_ "GenSigTimeoutMsg_EPB" SG_ 428 BR8_TolAbgl_HR 428;
BA_ "GenSigTimeoutTime_ACC_Radar" SG_ 428 BR8_TolAbgl_HR 500;
BA_ "GenSigTimeoutMsg_ACC_Radar" SG_ 428 BR8_TolAbgl_HR 428;
BA_ "GenSigTimeoutTime_ACC_Lidar" SG_ 428 BR8_TolAbgl_HR 500;
BA_ "GenSigTimeoutMsg_ACC_Lidar" SG_ 428 BR8_TolAbgl_HR 428;
BA_ "GenSigTimeoutTime_Gateway_PQ35_A" SG_ 428 BR8_TolAbgl_HR 500;
BA_ "GenSigTimeoutMsg_Gateway_PQ35_A" SG_ 428 BR8_TolAbgl_HR 428;
BA_ "GenSigSendType" SG_ 428 BR8_TolAbgl_HR 0;
BA_ "GenSigStartValue" SG_ 428 BR8_TolAbgl_HR 254;
BA_ "GenSigTimeoutTime_ACC_Lidar" SG_ 428 BR8_Sta_ADR_BR 500;
BA_ "GenSigTimeoutMsg_ACC_Lidar" SG_ 428 BR8_Sta_ADR_BR 428;
BA_ "GenSigTimeoutTime_Gateway_PQ35_A" SG_ 428 BR8_Sta_ADR_BR 500;
BA_ "GenSigTimeoutMsg_Gateway_PQ35_A" SG_ 428 BR8_Sta_ADR_BR 428;
BA_ "GenSigTimeoutTime_ACC_Radar" SG_ 428 BR8_Sta_ADR_BR 500;
BA_ "GenSigTimeoutMsg_ACC_Radar" SG_ 428 BR8_Sta_ADR_BR 428;
BA_ "GenSigTimeoutTime_EPB" SG_ 428 BR8_Sta_ADR_BR 500;
BA_ "GenSigTimeoutMsg_EPB" SG_ 428 BR8_Sta_ADR_BR 428;
BA_ "GenSigTimeoutTime_Otto" SG_ 428 BR8_Sta_ADR_BR 500;
BA_ "GenSigTimeoutMsg_Otto" SG_ 428 BR8_Sta_ADR_BR 428;
BA_ "GenSigTimeoutTime_Diesel" SG_ 428 BR8_Sta_ADR_BR 500;
BA_ "GenSigTimeoutMsg_Diesel" SG_ 428 BR8_Sta_ADR_BR 428;
BA_ "GenSigSendType" SG_ 428 BR8_Sta_ADR_BR 0;
BA_ "GenSigTimeoutTime_ACC_Lidar" SG_ 428 BR8_Sta_Br_temp 500;
BA_ "GenSigTimeoutMsg_ACC_Lidar" SG_ 428 BR8_Sta_Br_temp 428;
BA_ "GenSigTimeoutTime_Gateway_PQ35_A" SG_ 428 BR8_Sta_Br_temp 500;
BA_ "GenSigTimeoutMsg_Gateway_PQ35_A" SG_ 428 BR8_Sta_Br_temp 428;
BA_ "GenSigTimeoutTime_ACC_Radar" SG_ 428 BR8_Sta_Br_temp 500;
BA_ "GenSigTimeoutMsg_ACC_Radar" SG_ 428 BR8_Sta_Br_temp 428;
BA_ "GenSigTimeoutTime_EPB" SG_ 428 BR8_Sta_Br_temp 500;
BA_ "GenSigTimeoutMsg_EPB" SG_ 428 BR8_Sta_Br_temp 428;
BA_ "GenSigTimeoutTime_Diesel" SG_ 428 BR8_Sta_Br_temp 500;
BA_ "GenSigTimeoutMsg_Diesel" SG_ 428 BR8_Sta_Br_temp 428;
BA_ "GenSigSendType" SG_ 428 BR8_Sta_Br_temp 0;
BA_ "GenSigTimeoutTime_EPB" SG_ 428 BR8_Quattro 500;
BA_ "GenSigTimeoutMsg_EPB" SG_ 428 BR8_Quattro 428;
BA_ "GenSigTimeoutTime_ACC_Radar" SG_ 428 BR8_Quattro 500;
BA_ "GenSigTimeoutMsg_ACC_Radar" SG_ 428 BR8_Quattro 428;
BA_ "GenSigTimeoutTime_ACC_Lidar" SG_ 428 BR8_Quattro 500;
BA_ "GenSigTimeoutMsg_ACC_Lidar" SG_ 428 BR8_Quattro 428;
BA_ "GenSigTimeoutTime_Gateway_PQ35_A" SG_ 428 BR8_Quattro 500;
BA_ "GenSigTimeoutMsg_Gateway_PQ35_A" SG_ 428 BR8_Quattro 428;
BA_ "GenSigSendType" SG_ 428 BR8_Quattro 0;
BA_ "INIT" SG_ 428 BR8_Quattro "const";
BA_ "GenSigTimeoutTime_ACC_Lidar" SG_ 428 BR8_Sta_ACC_Anf 500;
BA_ "GenSigTimeoutMsg_ACC_Lidar" SG_ 428 BR8_Sta_ACC_Anf 428;
BA_ "GenSigTimeoutTime_Gateway_PQ35_A" SG_ 428 BR8_Sta_ACC_Anf 500;
BA_ "GenSigTimeoutMsg_Gateway_PQ35_A" SG_ 428 BR8_Sta_ACC_Anf 428;
BA_ "GenSigTimeoutTime_ACC_Radar" SG_ 428 BR8_Sta_ACC_Anf 500;
BA_ "GenSigTimeoutMsg_ACC_Radar" SG_ 428 BR8_Sta_ACC_Anf 428;
BA_ "GenSigTimeoutTime_EPB" SG_ 428 BR8_Sta_ACC_Anf 500;
BA_ "GenSigTimeoutMsg_EPB" SG_ 428 BR8_Sta_ACC_Anf 428;
BA_ "GenSigTimeoutTime_Otto" SG_ 428 BR8_Sta_ACC_Anf 500;
BA_ "GenSigTimeoutMsg_Otto" SG_ 428 BR8_Sta_ACC_Anf 428;
BA_ "GenSigTimeoutTime_Diesel" SG_ 428 BR8_Sta_ACC_Anf 500;
BA_ "GenSigTimeoutMsg_Diesel" SG_ 428 BR8_Sta_ACC_Anf 428;
BA_ "GenSigSendType" SG_ 428 BR8_Sta_ACC_Anf 0;
BA_ "GenSigTimeoutTime_ACC_Lidar" SG_ 428 BR8_Verz_EPB_akt 500;
BA_ "GenSigTimeoutMsg_ACC_Lidar" SG_ 428 BR8_Verz_EPB_akt 428;
BA_ "GenSigTimeoutTime_Gateway_PQ35_A" SG_ 428 BR8_Verz_EPB_akt 500;
BA_ "GenSigTimeoutMsg_Gateway_PQ35_A" SG_ 428 BR8_Verz_EPB_akt 428;
BA_ "GenSigTimeoutTime_ACC_Radar" SG_ 428 BR8_Verz_EPB_akt 500;
BA_ "GenSigTimeoutMsg_ACC_Radar" SG_ 428 BR8_Verz_EPB_akt 428;
BA_ "GenSigTimeoutTime_EPB" SG_ 428 BR8_Verz_EPB_akt 500;
BA_ "GenSigTimeoutMsg_EPB" SG_ 428 BR8_Verz_EPB_akt 428;
BA_ "GenSigTimeoutTime_Diesel" SG_ 428 BR8_Verz_EPB_akt 500;
BA_ "GenSigTimeoutMsg_Diesel" SG_ 428 BR8_Verz_EPB_akt 428;
BA_ "GenSigSendType" SG_ 428 BR8_Verz_EPB_akt 0;
BA_ "GenSigTimeoutTime_ACC_Lidar" SG_ 428 BR8_aktBrSyst 500;
BA_ "GenSigTimeoutMsg_ACC_Lidar" SG_ 428 BR8_aktBrSyst 428;
BA_ "GenSigTimeoutTime_Gateway_PQ35_A" SG_ 428 BR8_aktBrSyst 500;
BA_ "GenSigTimeoutMsg_Gateway_PQ35_A" SG_ 428 BR8_aktBrSyst 428;
BA_ "GenSigTimeoutTime_ACC_Radar" SG_ 428 BR8_aktBrSyst 500;
BA_ "GenSigTimeoutMsg_ACC_Radar" SG_ 428 BR8_aktBrSyst 428;
BA_ "GenSigTimeoutTime_EPB" SG_ 428 BR8_aktBrSyst 500;
BA_ "GenSigTimeoutMsg_EPB" SG_ 428 BR8_aktBrSyst 428;
BA_ "GenSigTimeoutTime_Otto" SG_ 428 BR8_aktBrSyst 500;
BA_ "GenSigTimeoutMsg_Otto" SG_ 428 BR8_aktBrSyst 428;
BA_ "GenSigTimeoutTime_Diesel" SG_ 428 BR8_aktBrSyst 500;
BA_ "GenSigTimeoutMsg_Diesel" SG_ 428 BR8_aktBrSyst 428;
BA_ "GenSigSendType" SG_ 428 BR8_aktBrSyst 0;
BA_ "INIT" SG_ 428 BR8_aktBrSyst "const";
BA_ "GenSigTimeoutTime_ACC_Lidar" SG_ 428 BR8_Sta_VerzReg 500;
BA_ "GenSigTimeoutMsg_ACC_Lidar" SG_ 428 BR8_Sta_VerzReg 428;
BA_ "GenSigTimeoutTime_Gateway_PQ35_A" SG_ 428 BR8_Sta_VerzReg 500;
BA_ "GenSigTimeoutMsg_Gateway_PQ35_A" SG_ 428 BR8_Sta_VerzReg 428;
BA_ "GenSigTimeoutTime_ACC_Radar" SG_ 428 BR8_Sta_VerzReg 500;
BA_ "GenSigTimeoutMsg_ACC_Radar" SG_ 428 BR8_Sta_VerzReg 428;
BA_ "GenSigTimeoutTime_EPB" SG_ 428 BR8_Sta_VerzReg 500;
BA_ "GenSigTimeoutMsg_EPB" SG_ 428 BR8_Sta_VerzReg 428;
BA_ "GenSigTimeoutTime_Diesel" SG_ 428 BR8_Sta_VerzReg 500;
BA_ "GenSigTimeoutMsg_Diesel" SG_ 428 BR8_Sta_VerzReg 428;
BA_ "GenSigSendType" SG_ 428 BR8_Sta_VerzReg 0;
BA_ "GenSigStartValue" SG_ 428 BR8_Sta_VerzReg 1;
BA_ "GenSigTimeoutTime_ACC_Lidar" SG_ 428 BR8_Fa_bremst 500;
BA_ "GenSigTimeoutMsg_ACC_Lidar" SG_ 428 BR8_Fa_bremst 428;
BA_ "GenSigTimeoutTime_Gateway_PQ35_A" SG_ 428 BR8_Fa_bremst 500;
BA_ "GenSigTimeoutMsg_Gateway_PQ35_A" SG_ 428 BR8_Fa_bremst 428;
BA_ "GenSigTimeoutTime_ACC_Radar" SG_ 428 BR8_Fa_bremst 500;
BA_ "GenSigTimeoutMsg_ACC_Radar" SG_ 428 BR8_Fa_bremst 428;
BA_ "GenSigTimeoutTime_EPB" SG_ 428 BR8_Fa_bremst 500;
BA_ "GenSigTimeoutMsg_EPB" SG_ 428 BR8_Fa_bremst 428;
BA_ "GenSigTimeoutTime_Diesel" SG_ 428 BR8_Fa_bremst 500;
BA_ "GenSigTimeoutMsg_Diesel" SG_ 428 BR8_Fa_bremst 428;
BA_ "GenSigSendType" SG_ 428 BR8_Fa_bremst 0;
BA_ "GenSigTimeoutTime_EPB" SG_ 428 BR8_Sta_BLS 500;
BA_ "GenSigTimeoutMsg_EPB" SG_ 428 BR8_Sta_BLS 428;
BA_ "GenSigTimeoutTime_ACC_Radar" SG_ 428 BR8_Sta_BLS 500;
BA_ "GenSigTimeoutMsg_ACC_Radar" SG_ 428 BR8_Sta_BLS 428;
BA_ "GenSigTimeoutTime_ACC_Lidar" SG_ 428 BR8_Sta_BLS 500;
BA_ "GenSigTimeoutMsg_ACC_Lidar" SG_ 428 BR8_Sta_BLS 428;
BA_ "GenSigTimeoutTime_Diesel" SG_ 428 BR8_Sta_BLS 500;
BA_ "GenSigTimeoutMsg_Diesel" SG_ 428 BR8_Sta_BLS 428;
BA_ "GenSigTimeoutTime_Gateway_PQ35_A" SG_ 428 BR8_Sta_BLS 500;
BA_ "GenSigTimeoutMsg_Gateway_PQ35_A" SG_ 428 BR8_Sta_BLS 428;
BA_ "GenSigSendType" SG_ 428 BR8_Sta_BLS 0;
BA_ "GenSigTimeoutTime_ACC_Lidar" SG_ 428 BR8_StaBrSyst 500;
BA_ "GenSigTimeoutMsg_ACC_Lidar" SG_ 428 BR8_StaBrSyst 428;
BA_ "GenSigTimeoutTime_Gateway_PQ35_A" SG_ 428 BR8_StaBrSyst 500;
BA_ "GenSigTimeoutMsg_Gateway_PQ35_A" SG_ 428 BR8_StaBrSyst 428;
BA_ "GenSigTimeoutTime_ACC_Radar" SG_ 428 BR8_StaBrSyst 500;
BA_ "GenSigTimeoutMsg_ACC_Radar" SG_ 428 BR8_StaBrSyst 428;
BA_ "GenSigTimeoutTime_EPB" SG_ 428 BR8_StaBrSyst 500;
BA_ "GenSigTimeoutMsg_EPB" SG_ 428 BR8_StaBrSyst 428;
BA_ "GenSigTimeoutTime_Otto" SG_ 428 BR8_StaBrSyst 500;
BA_ "GenSigTimeoutMsg_Otto" SG_ 428 BR8_StaBrSyst 428;
BA_ "GenSigTimeoutTime_Diesel" SG_ 428 BR8_StaBrSyst 500;
BA_ "GenSigTimeoutMsg_Diesel" SG_ 428 BR8_StaBrSyst 428;
BA_ "GenSigSendType" SG_ 428 BR8_StaBrSyst 0;
BA_ "GenSigTimeoutTime_EPB" SG_ 428 BR8_ESC_Mode 500;
BA_ "GenSigTimeoutMsg_EPB" SG_ 428 BR8_ESC_Mode 428;
BA_ "GenSigTimeoutTime_ACC_Radar" SG_ 428 BR8_ESC_Mode 500;
BA_ "GenSigTimeoutMsg_ACC_Radar" SG_ 428 BR8_ESC_Mode 428;
BA_ "GenSigTimeoutTime_ACC_Lidar" SG_ 428 BR8_ESC_Mode 500;
BA_ "GenSigTimeoutMsg_ACC_Lidar" SG_ 428 BR8_ESC_Mode 428;
BA_ "GenSigTimeoutTime_Gateway_PQ35_A" SG_ 428 BR8_ESC_Mode 500;
BA_ "GenSigTimeoutMsg_Gateway_PQ35_A" SG_ 428 BR8_ESC_Mode 428;
BA_ "GenSigSendType" SG_ 428 BR8_ESC_Mode 0;
BA_ "GenSigTimeoutTime_ACC_Lidar" SG_ 428 BR8_Verz_EPB 500;
BA_ "GenSigTimeoutMsg_ACC_Lidar" SG_ 428 BR8_Verz_EPB 428;
BA_ "GenSigTimeoutTime_Gateway_PQ35_A" SG_ 428 BR8_Verz_EPB 500;
BA_ "GenSigTimeoutMsg_Gateway_PQ35_A" SG_ 428 BR8_Verz_EPB 428;
BA_ "GenSigTimeoutTime_ACC_Radar" SG_ 428 BR8_Verz_EPB 500;
BA_ "GenSigTimeoutMsg_ACC_Radar" SG_ 428 BR8_Verz_EPB 428;
BA_ "GenSigTimeoutTime_EPB" SG_ 428 BR8_Verz_EPB 500;
BA_ "GenSigTimeoutMsg_EPB" SG_ 428 BR8_Verz_EPB 428;
BA_ "GenSigSendType" SG_ 428 BR8_Verz_EPB 0;
BA_ "GenSigTimeoutTime_EPB" SG_ 428 BR8_Sta_HW_BLS 500;
BA_ "GenSigTimeoutMsg_EPB" SG_ 428 BR8_Sta_HW_BLS 428;
BA_ "GenSigTimeoutTime_ACC_Radar" SG_ 428 BR8_Sta_HW_BLS 500;
BA_ "GenSigTimeoutMsg_ACC_Radar" SG_ 428 BR8_Sta_HW_BLS 428;
BA_ "GenSigTimeoutTime_ACC_Lidar" SG_ 428 BR8_Sta_HW_BLS 500;
BA_ "GenSigTimeoutMsg_ACC_Lidar" SG_ 428 BR8_Sta_HW_BLS 428;
BA_ "GenSigTimeoutTime_Gateway_PQ35_A" SG_ 428 BR8_Sta_HW_BLS 500;
BA_ "GenSigTimeoutMsg_Gateway_PQ35_A" SG_ 428 BR8_Sta_HW_BLS 428;
BA_ "GenSigSendType" SG_ 428 BR8_Sta_HW_BLS 0;
BA_ "GenSigTimeoutMsg_Gateway_PQ35_A" SG_ 515 ABS_TP_Er 515;
BA_ "GenSigTimeoutMsg_Gateway_PQ46_A" SG_ 515 ABS_TP_Er 515;
BA_ "GenSigSendType" SG_ 515 ABS_TP_Er 5;
BA_ "GenSigTimeoutTime_Lenkhilfe_ZF_3" SG_ 1184 BR3_Rad_kmh_VR 500;
BA_ "GenSigTimeoutMsg_Lenkhilfe_ZF_3" SG_ 1184 BR3_Rad_kmh_VR 1184;
BA_ "GenSigTimeoutTime_Lenkhilfe_ZF_2" SG_ 1184 BR3_Rad_kmh_VR 500;
BA_ "GenSigTimeoutMsg_Lenkhilfe_ZF_2" SG_ 1184 BR3_Rad_kmh_VR 1184;
BA_ "GenSigTimeoutTime_Magne_Ride" SG_ 1184 BR3_Rad_kmh_VR 500;
BA_ "GenSigTimeoutMsg_Magne_Ride" SG_ 1184 BR3_Rad_kmh_VR 1184;
BA_ "GenSigTimeoutTime_ACC_Lidar" SG_ 1184 BR3_Rad_kmh_VR 500;
BA_ "GenSigTimeoutMsg_ACC_Lidar" SG_ 1184 BR3_Rad_kmh_VR 1184;
BA_ "GenSigTimeoutTime_Selespeed" SG_ 1184 BR3_Rad_kmh_VR 500;
BA_ "GenSigTimeoutMsg_Selespeed" SG_ 1184 BR3_Rad_kmh_VR 1184;
BA_ "GenSigTimeoutTime_Hybrid_DQ200" SG_ 1184 BR3_Rad_kmh_VR 500;
BA_ "GenSigTimeoutMsg_Hybrid_DQ200" SG_ 1184 BR3_Rad_kmh_VR 1184;
BA_ "GenSigTimeoutTime_Hybrid_MSG" SG_ 1184 BR3_Rad_kmh_VR 500;
BA_ "GenSigTimeoutMsg_Hybrid_MSG" SG_ 1184 BR3_Rad_kmh_VR 1184;
BA_ "GenSigTimeoutTime_Lenkhilfe_APA" SG_ 1184 BR3_Rad_kmh_VR 500;
BA_ "GenSigTimeoutMsg_Lenkhilfe_APA" SG_ 1184 BR3_Rad_kmh_VR 1184;
BA_ "GenSigTimeoutTime_PDC_PLA" SG_ 1184 BR3_Rad_kmh_VR 500;
BA_ "GenSigTimeoutMsg_PDC_PLA" SG_ 1184 BR3_Rad_kmh_VR 1184;
BA_ "GenSigTimeoutTime_AFS" SG_ 1184 BR3_Rad_kmh_VR 500;
BA_ "GenSigTimeoutMsg_AFS" SG_ 1184 BR3_Rad_kmh_VR 1184;
BA_ "GenSigTimeoutTime_ACC_Radar" SG_ 1184 BR3_Rad_kmh_VR 500;
BA_ "GenSigTimeoutMsg_ACC_Radar" SG_ 1184 BR3_Rad_kmh_VR 1184;
BA_ "GenSigTimeoutTime_EPB" SG_ 1184 BR3_Rad_kmh_VR 500;
BA_ "GenSigTimeoutMsg_EPB" SG_ 1184 BR3_Rad_kmh_VR 1184;
BA_ "GenSigTimeoutTime_DQ" SG_ 1184 BR3_Rad_kmh_VR 500;
BA_ "GenSigTimeoutMsg_DQ" SG_ 1184 BR3_Rad_kmh_VR 1184;
BA_ "GenSigTimeoutTime_LWR" SG_ 1184 BR3_Rad_kmh_VR 500;
BA_ "GenSigTimeoutMsg_LWR" SG_ 1184 BR3_Rad_kmh_VR 1184;
BA_ "GenSigTimeoutTime_LWS" SG_ 1184 BR3_Rad_kmh_VR 500;
BA_ "GenSigTimeoutMsg_LWS" SG_ 1184 BR3_Rad_kmh_VR 1184;
BA_ "GenSigTimeoutTime_Otto" SG_ 1184 BR3_Rad_kmh_VR 500;
BA_ "GenSigTimeoutMsg_Otto" SG_ 1184 BR3_Rad_kmh_VR 1184;
BA_ "GenSigTimeoutTime_Allrad" SG_ 1184 BR3_Rad_kmh_VR 500;
BA_ "GenSigTimeoutMsg_Allrad" SG_ 1184 BR3_Rad_kmh_VR 1184;
BA_ "GenSigTimeoutTime_AG6" SG_ 1184 BR3_Rad_kmh_VR 500;
BA_ "GenSigTimeoutMsg_AG6" SG_ 1184 BR3_Rad_kmh_VR 1184;
BA_ "GenSigSendType" SG_ 1184 BR3_Rad_kmh_VR 0;
BA_ "GenSigStartValue" SG_ 1184 BR3_Rad_kmh_VR 32708;
BA_ "GenSigTimeoutTime_Lenkhilfe_ZF_3" SG_ 1184 BR3_Rad_kmh_VL 500;
BA_ "GenSigTimeoutMsg_Lenkhilfe_ZF_3" SG_ 1184 BR3_Rad_kmh_VL 1184;
BA_ "GenSigTimeoutTime_Lenkhilfe_ZF_2" SG_ 1184 BR3_Rad_kmh_VL 500;
BA_ "GenSigTimeoutMsg_Lenkhilfe_ZF_2" SG_ 1184 BR3_Rad_kmh_VL 1184;
BA_ "GenSigTimeoutTime_Magne_Ride" SG_ 1184 BR3_Rad_kmh_VL 500;
BA_ "GenSigTimeoutMsg_Magne_Ride" SG_ 1184 BR3_Rad_kmh_VL 1184;
BA_ "GenSigTimeoutTime_ACC_Lidar" SG_ 1184 BR3_Rad_kmh_VL 500;
BA_ "GenSigTimeoutMsg_ACC_Lidar" SG_ 1184 BR3_Rad_kmh_VL 1184;
BA_ "GenSigTimeoutTime_Selespeed" SG_ 1184 BR3_Rad_kmh_VL 500;
BA_ "GenSigTimeoutMsg_Selespeed" SG_ 1184 BR3_Rad_kmh_VL 1184;
BA_ "GenSigTimeoutTime_Hybrid_DQ200" SG_ 1184 BR3_Rad_kmh_VL 500;
BA_ "GenSigTimeoutMsg_Hybrid_DQ200" SG_ 1184 BR3_Rad_kmh_VL 1184;
BA_ "GenSigTimeoutTime_Hybrid_MSG" SG_ 1184 BR3_Rad_kmh_VL 500;
BA_ "GenSigTimeoutMsg_Hybrid_MSG" SG_ 1184 BR3_Rad_kmh_VL 1184;
BA_ "GenSigTimeoutTime_Lenkhilfe_APA" SG_ 1184 BR3_Rad_kmh_VL 500;
BA_ "GenSigTimeoutMsg_Lenkhilfe_APA" SG_ 1184 BR3_Rad_kmh_VL 1184;
BA_ "GenSigTimeoutTime_PDC_PLA" SG_ 1184 BR3_Rad_kmh_VL 500;
BA_ "GenSigTimeoutMsg_PDC_PLA" SG_ 1184 BR3_Rad_kmh_VL 1184;
BA_ "GenSigTimeoutTime_AFS" SG_ 1184 BR3_Rad_kmh_VL 500;
BA_ "GenSigTimeoutMsg_AFS" SG_ 1184 BR3_Rad_kmh_VL 1184;
BA_ "GenSigTimeoutTime_ACC_Radar" SG_ 1184 BR3_Rad_kmh_VL 500;
BA_ "GenSigTimeoutMsg_ACC_Radar" SG_ 1184 BR3_Rad_kmh_VL 1184;
BA_ "GenSigTimeoutTime_EPB" SG_ 1184 BR3_Rad_kmh_VL 500;
BA_ "GenSigTimeoutMsg_EPB" SG_ 1184 BR3_Rad_kmh_VL 1184;
BA_ "GenSigTimeoutTime_DQ" SG_ 1184 BR3_Rad_kmh_VL 500;
BA_ "GenSigTimeoutMsg_DQ" SG_ 1184 BR3_Rad_kmh_VL 1184;
BA_ "GenSigTimeoutTime_LWR" SG_ 1184 BR3_Rad_kmh_VL 500;
BA_ "GenSigTimeoutMsg_LWR" SG_ 1184 BR3_Rad_kmh_VL 1184;
BA_ "GenSigTimeoutTime_LWS" SG_ 1184 BR3_Rad_kmh_VL 500;
BA_ "GenSigTimeoutMsg_LWS" SG_ 1184 BR3_Rad_kmh_VL 1184;
BA_ "GenSigTimeoutTime_Otto" SG_ 1184 BR3_Rad_kmh_VL 500;
BA_ "GenSigTimeoutMsg_Otto" SG_ 1184 BR3_Rad_kmh_VL 1184;
BA_ "GenSigTimeoutTime_Allrad" SG_ 1184 BR3_Rad_kmh_VL 500;
BA_ "GenSigTimeoutMsg_Allrad" SG_ 1184 BR3_Rad_kmh_VL 1184;
BA_ "GenSigTimeoutTime_AG6" SG_ 1184 BR3_Rad_kmh_VL 500;
BA_ "GenSigTimeoutMsg_AG6" SG_ 1184 BR3_Rad_kmh_VL 1184;
BA_ "GenSigSendType" SG_ 1184 BR3_Rad_kmh_VL 0;
BA_ "GenSigStartValue" SG_ 1184 BR3_Rad_kmh_VL 32708;
BA_ "GenSigTimeoutTime_Lenkhilfe_ZF_3" SG_ 1184 BR3_Rad_kmh_HR 500;
BA_ "GenSigTimeoutMsg_Lenkhilfe_ZF_3" SG_ 1184 BR3_Rad_kmh_HR 1184;
BA_ "GenSigTimeoutTime_Lenkhilfe_ZF_2" SG_ 1184 BR3_Rad_kmh_HR 500;
BA_ "GenSigTimeoutMsg_Lenkhilfe_ZF_2" SG_ 1184 BR3_Rad_kmh_HR 1184;
BA_ "GenSigTimeoutTime_Magne_Ride" SG_ 1184 BR3_Rad_kmh_HR 500;
BA_ "GenSigTimeoutMsg_Magne_Ride" SG_ 1184 BR3_Rad_kmh_HR 1184;
BA_ "GenSigTimeoutTime_ACC_Lidar" SG_ 1184 BR3_Rad_kmh_HR 500;
BA_ "GenSigTimeoutMsg_ACC_Lidar" SG_ 1184 BR3_Rad_kmh_HR 1184;
BA_ "GenSigTimeoutTime_Selespeed" SG_ 1184 BR3_Rad_kmh_HR 500;
BA_ "GenSigTimeoutMsg_Selespeed" SG_ 1184 BR3_Rad_kmh_HR 1184;
BA_ "GenSigTimeoutTime_Hybrid_DQ200" SG_ 1184 BR3_Rad_kmh_HR 500;
BA_ "GenSigTimeoutMsg_Hybrid_DQ200" SG_ 1184 BR3_Rad_kmh_HR 1184;
BA_ "GenSigTimeoutTime_Hybrid_MSG" SG_ 1184 BR3_Rad_kmh_HR 500;
BA_ "GenSigTimeoutMsg_Hybrid_MSG" SG_ 1184 BR3_Rad_kmh_HR 1184;
BA_ "GenSigTimeoutTime_Lenkhilfe_APA" SG_ 1184 BR3_Rad_kmh_HR 500;
BA_ "GenSigTimeoutMsg_Lenkhilfe_APA" SG_ 1184 BR3_Rad_kmh_HR 1184;
BA_ "GenSigTimeoutTime_PDC_PLA" SG_ 1184 BR3_Rad_kmh_HR 500;
BA_ "GenSigTimeoutMsg_PDC_PLA" SG_ 1184 BR3_Rad_kmh_HR 1184;
BA_ "GenSigTimeoutTime_AFS" SG_ 1184 BR3_Rad_kmh_HR 500;
BA_ "GenSigTimeoutMsg_AFS" SG_ 1184 BR3_Rad_kmh_HR 1184;
BA_ "GenSigTimeoutTime_ACC_Radar" SG_ 1184 BR3_Rad_kmh_HR 500;
BA_ "GenSigTimeoutMsg_ACC_Radar" SG_ 1184 BR3_Rad_kmh_HR 1184;
BA_ "GenSigTimeoutTime_EPB" SG_ 1184 BR3_Rad_kmh_HR 500;
BA_ "GenSigTimeoutMsg_EPB" SG_ 1184 BR3_Rad_kmh_HR 1184;
BA_ "GenSigTimeoutTime_DQ" SG_ 1184 BR3_Rad_kmh_HR 500;
BA_ "GenSigTimeoutMsg_DQ" SG_ 1184 BR3_Rad_kmh_HR 1184;
BA_ "GenSigTimeoutTime_LWR" SG_ 1184 BR3_Rad_kmh_HR 500;
BA_ "GenSigTimeoutMsg_LWR" SG_ 1184 BR3_Rad_kmh_HR 1184;
BA_ "GenSigTimeoutTime_LWS" SG_ 1184 BR3_Rad_kmh_HR 500;
BA_ "GenSigTimeoutMsg_LWS" SG_ 1184 BR3_Rad_kmh_HR 1184;
BA_ "GenSigTimeoutTime_Otto" SG_ 1184 BR3_Rad_kmh_HR 500;
BA_ "GenSigTimeoutMsg_Otto" SG_ 1184 BR3_Rad_kmh_HR 1184;
BA_ "GenSigTimeoutTime_Allrad" SG_ 1184 BR3_Rad_kmh_HR 500;
BA_ "GenSigTimeoutMsg_Allrad" SG_ 1184 BR3_Rad_kmh_HR 1184;
BA_ "GenSigTimeoutTime_AG6" SG_ 1184 BR3_Rad_kmh_HR 500;
BA_ "GenSigTimeoutMsg_AG6" SG_ 1184 BR3_Rad_kmh_HR 1184;
BA_ "GenSigSendType" SG_ 1184 BR3_Rad_kmh_HR 0;
BA_ "GenSigStartValue" SG_ 1184 BR3_Rad_kmh_HR 32708;
BA_ "GenSigTimeoutTime_ACC_Radar" SG_ 1184 BR3_Fahrtr_VL 500;
BA_ "GenSigTimeoutMsg_ACC_Radar" SG_ 1184 BR3_Fahrtr_VL 1184;
BA_ "GenSigTimeoutTime_Magne_Ride" SG_ 1184 BR3_Fahrtr_VL 500;
BA_ "GenSigTimeoutMsg_Magne_Ride" SG_ 1184 BR3_Fahrtr_VL 1184;
BA_ "GenSigTimeoutTime_ACC_Lidar" SG_ 1184 BR3_Fahrtr_VL 500;
BA_ "GenSigTimeoutMsg_ACC_Lidar" SG_ 1184 BR3_Fahrtr_VL 1184;
BA_ "GenSigSendType" SG_ 1184 BR3_Fahrtr_VL 0;
BA_ "GenSigTimeoutTime_ACC_Radar" SG_ 1184 BR3_Fahrtr_VR 500;
BA_ "GenSigTimeoutMsg_ACC_Radar" SG_ 1184 BR3_Fahrtr_VR 1184;
BA_ "GenSigTimeoutTime_Magne_Ride" SG_ 1184 BR3_Fahrtr_VR 500;
BA_ "GenSigTimeoutMsg_Magne_Ride" SG_ 1184 BR3_Fahrtr_VR 1184;
BA_ "GenSigTimeoutTime_ACC_Lidar" SG_ 1184 BR3_Fahrtr_VR 500;
BA_ "GenSigTimeoutMsg_ACC_Lidar" SG_ 1184 BR3_Fahrtr_VR 1184;
BA_ "GenSigSendType" SG_ 1184 BR3_Fahrtr_VR 0;
BA_ "GenSigTimeoutTime_ACC_Radar" SG_ 1184 BR3_Fahrtr_HR 500;
BA_ "GenSigTimeoutMsg_ACC_Radar" SG_ 1184 BR3_Fahrtr_HR 1184;
BA_ "GenSigTimeoutTime_Magne_Ride" SG_ 1184 BR3_Fahrtr_HR 500;
BA_ "GenSigTimeoutMsg_Magne_Ride" SG_ 1184 BR3_Fahrtr_HR 1184;
BA_ "GenSigTimeoutTime_ACC_Lidar" SG_ 1184 BR3_Fahrtr_HR 500;
BA_ "GenSigTimeoutMsg_ACC_Lidar" SG_ 1184 BR3_Fahrtr_HR 1184;
BA_ "GenSigSendType" SG_ 1184 BR3_Fahrtr_HR 0;
BA_ "GenSigTimeoutTime_Lenkhilfe_ZF_2" SG_ 1184 BR3_Rad_kmh_HL 500;
BA_ "GenSigTimeoutMsg_Lenkhilfe_ZF_2" SG_ 1184 BR3_Rad_kmh_HL 1184;
BA_ "GenSigTimeoutTime_Lenkhilfe_ZF_3" SG_ 1184 BR3_Rad_kmh_HL 500;
BA_ "GenSigTimeoutMsg_Lenkhilfe_ZF_3" SG_ 1184 BR3_Rad_kmh_HL 1184;
BA_ "GenSigTimeoutTime_Magne_Ride" SG_ 1184 BR3_Rad_kmh_HL 500;
BA_ "GenSigTimeoutMsg_Magne_Ride" SG_ 1184 BR3_Rad_kmh_HL 1184;
BA_ "GenSigTimeoutTime_ACC_Lidar" SG_ 1184 BR3_Rad_kmh_HL 500;
BA_ "GenSigTimeoutMsg_ACC_Lidar" SG_ 1184 BR3_Rad_kmh_HL 1184;
BA_ "GenSigTimeoutTime_Selespeed" SG_ 1184 BR3_Rad_kmh_HL 500;
BA_ "GenSigTimeoutMsg_Selespeed" SG_ 1184 BR3_Rad_kmh_HL 1184;
BA_ "GenSigTimeoutTime_Hybrid_DQ200" SG_ 1184 BR3_Rad_kmh_HL 500;
BA_ "GenSigTimeoutMsg_Hybrid_DQ200" SG_ 1184 BR3_Rad_kmh_HL 1184;
BA_ "GenSigTimeoutTime_Hybrid_MSG" SG_ 1184 BR3_Rad_kmh_HL 500;
BA_ "GenSigTimeoutMsg_Hybrid_MSG" SG_ 1184 BR3_Rad_kmh_HL 1184;
BA_ "GenSigTimeoutTime_Lenkhilfe_APA" SG_ 1184 BR3_Rad_kmh_HL 500;
BA_ "GenSigTimeoutMsg_Lenkhilfe_APA" SG_ 1184 BR3_Rad_kmh_HL 1184;
BA_ "GenSigTimeoutTime_PDC_PLA" SG_ 1184 BR3_Rad_kmh_HL 500;
BA_ "GenSigTimeoutMsg_PDC_PLA" SG_ 1184 BR3_Rad_kmh_HL 1184;
BA_ "GenSigTimeoutTime_AFS" SG_ 1184 BR3_Rad_kmh_HL 500;
BA_ "GenSigTimeoutMsg_AFS" SG_ 1184 BR3_Rad_kmh_HL 1184;
BA_ "GenSigTimeoutTime_ACC_Radar" SG_ 1184 BR3_Rad_kmh_HL 500;
BA_ "GenSigTimeoutMsg_ACC_Radar" SG_ 1184 BR3_Rad_kmh_HL 1184;
BA_ "GenSigTimeoutTime_EPB" SG_ 1184 BR3_Rad_kmh_HL 500;
BA_ "GenSigTimeoutMsg_EPB" SG_ 1184 BR3_Rad_kmh_HL 1184;
BA_ "GenSigTimeoutTime_DQ" SG_ 1184 BR3_Rad_kmh_HL 500;
BA_ "GenSigTimeoutMsg_DQ" SG_ 1184 BR3_Rad_kmh_HL 1184;
BA_ "GenSigTimeoutTime_LWR" SG_ 1184 BR3_Rad_kmh_HL 500;
BA_ "GenSigTimeoutMsg_LWR" SG_ 1184 BR3_Rad_kmh_HL 1184;
BA_ "GenSigTimeoutTime_LWS" SG_ 1184 BR3_Rad_kmh_HL 500;
BA_ "GenSigTimeoutMsg_LWS" SG_ 1184 BR3_Rad_kmh_HL 1184;
BA_ "GenSigTimeoutTime_Otto" SG_ 1184 BR3_Rad_kmh_HL 500;
BA_ "GenSigTimeoutMsg_Otto" SG_ 1184 BR3_Rad_kmh_HL 1184;
BA_ "GenSigTimeoutTime_Allrad" SG_ 1184 BR3_Rad_kmh_HL 500;
BA_ "GenSigTimeoutMsg_Allrad" SG_ 1184 BR3_Rad_kmh_HL 1184;
BA_ "GenSigTimeoutTime_AG6" SG_ 1184 BR3_Rad_kmh_HL 500;
BA_ "GenSigTimeoutMsg_AG6" SG_ 1184 BR3_Rad_kmh_HL 1184;
BA_ "GenSigSendType" SG_ 1184 BR3_Rad_kmh_HL 0;
BA_ "GenSigStartValue" SG_ 1184 BR3_Rad_kmh_HL 32708;
BA_ "GenSigTimeoutTime_ACC_Radar" SG_ 1184 BR3_Fahrtr_HL 500;
BA_ "GenSigTimeoutMsg_ACC_Radar" SG_ 1184 BR3_Fahrtr_HL 1184;
BA_ "GenSigTimeoutTime_Magne_Ride" SG_ 1184 BR3_Fahrtr_HL 500;
BA_ "GenSigTimeoutMsg_Magne_Ride" SG_ 1184 BR3_Fahrtr_HL 1184;
BA_ "GenSigTimeoutTime_ACC_Lidar" SG_ 1184 BR3_Fahrtr_HL 500;
BA_ "GenSigTimeoutMsg_ACC_Lidar" SG_ 1184 BR3_Fahrtr_HL 1184;
BA_ "GenSigSendType" SG_ 1184 BR3_Fahrtr_HL 0;
BA_ "GenSigTimeoutTime_Lenkhilfe_ZF_2" SG_ 174 BR9_res_09 500;
BA_ "GenSigTimeoutMsg_Lenkhilfe_ZF_2" SG_ 174 BR9_res_09 174;
BA_ "GenSigTimeoutTime_Lenkhilfe_APA" SG_ 174 BR9_res_09 500;
BA_ "GenSigTimeoutMsg_Lenkhilfe_APA" SG_ 174 BR9_res_09 174;
BA_ "GenSigTimeoutTime_Lenkhilfe_ZF_3" SG_ 174 BR9_res_09 500;
BA_ "GenSigTimeoutMsg_Lenkhilfe_ZF_3" SG_ 174 BR9_res_09 174;
BA_ "GenSigSendType" SG_ 174 BR9_res_09 0;
BA_ "GenSigTimeoutTime_Lenkhilfe_ZF_2" SG_ 174 BR9_res_10 500;
BA_ "GenSigTimeoutMsg_Lenkhilfe_ZF_2" SG_ 174 BR9_res_10 174;
BA_ "GenSigTimeoutTime_Lenkhilfe_APA" SG_ 174 BR9_res_10 500;
BA_ "GenSigTimeoutMsg_Lenkhilfe_APA" SG_ 174 BR9_res_10 174;
BA_ "GenSigTimeoutTime_Lenkhilfe_ZF_3" SG_ 174 BR9_res_10 500;
BA_ "GenSigTimeoutMsg_Lenkhilfe_ZF_3" SG_ 174 BR9_res_10 174;
BA_ "GenSigSendType" SG_ 174 BR9_res_10 0;
BA_ "GenSigTimeoutTime_Lenkhilfe_ZF_2" SG_ 174 BR9_res_08 500;
BA_ "GenSigTimeoutMsg_Lenkhilfe_ZF_2" SG_ 174 BR9_res_08 174;
BA_ "GenSigTimeoutTime_Lenkhilfe_APA" SG_ 174 BR9_res_08 500;
BA_ "GenSigTimeoutMsg_Lenkhilfe_APA" SG_ 174 BR9_res_08 174;
BA_ "GenSigTimeoutTime_Lenkhilfe_ZF_3" SG_ 174 BR9_res_08 500;
BA_ "GenSigTimeoutMsg_Lenkhilfe_ZF_3" SG_ 174 BR9_res_08 174;
BA_ "GenSigSendType" SG_ 174 BR9_res_08 0;
BA_ "GenSigTimeoutTime_Lenkhilfe_ZF_3" SG_ 174 BR9_Zaehler 500;
BA_ "GenSigTimeoutMsg_Lenkhilfe_ZF_3" SG_ 174 BR9_Zaehler 174;
BA_ "GenSigTimeoutTime_Lenkhilfe_APA" SG_ 174 BR9_Zaehler 500;
BA_ "GenSigTimeoutMsg_Lenkhilfe_APA" SG_ 174 BR9_Zaehler 174;
BA_ "GenSigTimeoutTime_Lenkhilfe_ZF_2" SG_ 174 BR9_Zaehler 500;
BA_ "GenSigTimeoutMsg_Lenkhilfe_ZF_2" SG_ 174 BR9_Zaehler 174;
BA_ "GenSigSendType" SG_ 174 BR9_Zaehler 0;
BA_ "GenSigTimeoutTime_Lenkhilfe_ZF_3" SG_ 174 BR9_Checksumme 500;
BA_ "GenSigTimeoutMsg_Lenkhilfe_ZF_3" SG_ 174 BR9_Checksumme 174;
BA_ "GenSigTimeoutTime_Lenkhilfe_APA" SG_ 174 BR9_Checksumme 500;
BA_ "GenSigTimeoutMsg_Lenkhilfe_APA" SG_ 174 BR9_Checksumme 174;
BA_ "GenSigTimeoutTime_Lenkhilfe_ZF_2" SG_ 174 BR9_Checksumme 500;
BA_ "GenSigTimeoutMsg_Lenkhilfe_ZF_2" SG_ 174 BR9_Checksumme 174;
BA_ "GenSigSendType" SG_ 174 BR9_Checksumme 0;
BA_ "INIT" SG_ 174 BR9_Checksumme "CHK";
BA_ "GenSigTimeoutTime_Lenkhilfe_ZF_2" SG_ 174 BR9_res_52 500;
BA_ "GenSigTimeoutMsg_Lenkhilfe_ZF_2" SG_ 174 BR9_res_52 174;
BA_ "GenSigTimeoutTime_Lenkhilfe_APA" SG_ 174 BR9_res_52 500;
BA_ "GenSigTimeoutMsg_Lenkhilfe_APA" SG_ 174 BR9_res_52 174;
BA_ "GenSigTimeoutTime_Lenkhilfe_ZF_3" SG_ 174 BR9_res_52 500;
BA_ "GenSigTimeoutMsg_Lenkhilfe_ZF_3" SG_ 174 BR9_res_52 174;
BA_ "GenSigSendType" SG_ 174 BR9_res_52 0;
BA_ "GenSigTimeoutTime_Lenkhilfe_ZF_2" SG_ 174 BR9_res_54 500;
BA_ "GenSigTimeoutMsg_Lenkhilfe_ZF_2" SG_ 174 BR9_res_54 174;
BA_ "GenSigTimeoutTime_Lenkhilfe_APA" SG_ 174 BR9_res_54 500;
BA_ "GenSigTimeoutMsg_Lenkhilfe_APA" SG_ 174 BR9_res_54 174;
BA_ "GenSigTimeoutTime_Lenkhilfe_ZF_3" SG_ 174 BR9_res_54 500;
BA_ "GenSigTimeoutMsg_Lenkhilfe_ZF_3" SG_ 174 BR9_res_54 174;
BA_ "GenSigSendType" SG_ 174 BR9_res_54 0;
BA_ "GenSigTimeoutTime_Lenkhilfe_ZF_2" SG_ 174 BR9_res_53 500;
BA_ "GenSigTimeoutMsg_Lenkhilfe_ZF_2" SG_ 174 BR9_res_53 174;
BA_ "GenSigTimeoutTime_Lenkhilfe_APA" SG_ 174 BR9_res_53 500;
BA_ "GenSigTimeoutMsg_Lenkhilfe_APA" SG_ 174 BR9_res_53 174;
BA_ "GenSigTimeoutTime_Lenkhilfe_ZF_3" SG_ 174 BR9_res_53 500;
BA_ "GenSigTimeoutMsg_Lenkhilfe_ZF_3" SG_ 174 BR9_res_53 174;
BA_ "GenSigSendType" SG_ 174 BR9_res_53 0;
BA_ "GenSigTimeoutTime_Lenkhilfe_ZF_2" SG_ 174 BR9_res_55 500;
BA_ "GenSigTimeoutMsg_Lenkhilfe_ZF_2" SG_ 174 BR9_res_55 174;
BA_ "GenSigTimeoutTime_Lenkhilfe_APA" SG_ 174 BR9_res_55 500;
BA_ "GenSigTimeoutMsg_Lenkhilfe_APA" SG_ 174 BR9_res_55 174;
BA_ "GenSigTimeoutTime_Lenkhilfe_ZF_3" SG_ 174 BR9_res_55 500;
BA_ "GenSigTimeoutMsg_Lenkhilfe_ZF_3" SG_ 174 BR9_res_55 174;
BA_ "GenSigSendType" SG_ 174 BR9_res_55 0;
BA_ "GenSigTimeoutTime_Lenkhilfe_ZF_2" SG_ 174 BR9_res_11 500;
BA_ "GenSigTimeoutMsg_Lenkhilfe_ZF_2" SG_ 174 BR9_res_11 174;
BA_ "GenSigTimeoutTime_Lenkhilfe_APA" SG_ 174 BR9_res_11 500;
BA_ "GenSigTimeoutMsg_Lenkhilfe_APA" SG_ 174 BR9_res_11 174;
BA_ "GenSigTimeoutTime_Lenkhilfe_ZF_3" SG_ 174 BR9_res_11 500;
BA_ "GenSigTimeoutMsg_Lenkhilfe_ZF_3" SG_ 174 BR9_res_11 174;
BA_ "GenSigSendType" SG_ 174 BR9_res_11 0;
BA_ "GenSigTimeoutTime_Lenkhilfe_ZF_3" SG_ 174 BR9_LMOffset 500;
BA_ "GenSigTimeoutMsg_Lenkhilfe_ZF_3" SG_ 174 BR9_LMOffset 174;
BA_ "GenSigTimeoutTime_Lenkhilfe_APA" SG_ 174 BR9_LMOffset 500;
BA_ "GenSigTimeoutMsg_Lenkhilfe_APA" SG_ 174 BR9_LMOffset 174;
BA_ "GenSigTimeoutTime_Lenkhilfe_ZF_2" SG_ 174 BR9_LMOffset 500;
BA_ "GenSigTimeoutMsg_Lenkhilfe_ZF_2" SG_ 174 BR9_LMOffset 174;
BA_ "GenSigSendType" SG_ 174 BR9_LMOffset 0;
BA_ "GenSigTimeoutTime_Lenkhilfe_ZF_3" SG_ 174 BR9_LMOffSign 500;
BA_ "GenSigTimeoutMsg_Lenkhilfe_ZF_3" SG_ 174 BR9_LMOffSign 174;
BA_ "GenSigTimeoutTime_Lenkhilfe_APA" SG_ 174 BR9_LMOffSign 500;
BA_ "GenSigTimeoutMsg_Lenkhilfe_APA" SG_ 174 BR9_LMOffSign 174;
BA_ "GenSigTimeoutTime_Lenkhilfe_ZF_2" SG_ 174 BR9_LMOffSign 500;
BA_ "GenSigTimeoutMsg_Lenkhilfe_ZF_2" SG_ 174 BR9_LMOffSign 174;
BA_ "GenSigSendType" SG_ 174 BR9_LMOffSign 0;
BA_ "GenSigTimeoutTime_Lenkhilfe_ZF_3" SG_ 174 BR9_LWOffset 500;
BA_ "GenSigTimeoutMsg_Lenkhilfe_ZF_3" SG_ 174 BR9_LWOffset 174;
BA_ "GenSigTimeoutTime_Lenkhilfe_APA" SG_ 174 BR9_LWOffset 500;
BA_ "GenSigTimeoutMsg_Lenkhilfe_APA" SG_ 174 BR9_LWOffset 174;
BA_ "GenSigTimeoutTime_Lenkhilfe_ZF_2" SG_ 174 BR9_LWOffset 500;
BA_ "GenSigTimeoutMsg_Lenkhilfe_ZF_2" SG_ 174 BR9_LWOffset 174;
BA_ "GenSigSendType" SG_ 174 BR9_LWOffset 0;
BA_ "GenSigTimeoutTime_Lenkhilfe_ZF_3" SG_ 174 BR9_LWOffSign 500;
BA_ "GenSigTimeoutMsg_Lenkhilfe_ZF_3" SG_ 174 BR9_LWOffSign 174;
BA_ "GenSigTimeoutTime_Lenkhilfe_APA" SG_ 174 BR9_LWOffSign 500;
BA_ "GenSigTimeoutMsg_Lenkhilfe_APA" SG_ 174 BR9_LWOffSign 174;
BA_ "GenSigTimeoutTime_Lenkhilfe_ZF_2" SG_ 174 BR9_LWOffSign 500;
BA_ "GenSigTimeoutMsg_Lenkhilfe_ZF_2" SG_ 174 BR9_LWOffSign 174;
BA_ "GenSigSendType" SG_ 174 BR9_LWOffSign 0;
BA_ "GenSigTimeoutTime_Lenkhilfe_ZF_2" SG_ 174 BR9_res_56 500;
BA_ "GenSigTimeoutMsg_Lenkhilfe_ZF_2" SG_ 174 BR9_res_56 174;
BA_ "GenSigTimeoutTime_Lenkhilfe_APA" SG_ 174 BR9_res_56 500;
BA_ "GenSigTimeoutMsg_Lenkhilfe_APA" SG_ 174 BR9_res_56 174;
BA_ "GenSigTimeoutTime_Lenkhilfe_ZF_3" SG_ 174 BR9_res_56 500;
BA_ "GenSigTimeoutMsg_Lenkhilfe_ZF_3" SG_ 174 BR9_res_56 174;
BA_ "GenSigSendType" SG_ 174 BR9_res_56 0;
BA_ "GenSigTimeoutTime_Lenkhilfe_ZF_2" SG_ 174 BR9_res_59 500;
BA_ "GenSigTimeoutMsg_Lenkhilfe_ZF_2" SG_ 174 BR9_res_59 174;
BA_ "GenSigTimeoutTime_Lenkhilfe_APA" SG_ 174 BR9_res_59 500;
BA_ "GenSigTimeoutMsg_Lenkhilfe_APA" SG_ 174 BR9_res_59 174;
BA_ "GenSigTimeoutTime_Lenkhilfe_ZF_3" SG_ 174 BR9_res_59 500;
BA_ "GenSigTimeoutMsg_Lenkhilfe_ZF_3" SG_ 174 BR9_res_59 174;
BA_ "GenSigSendType" SG_ 174 BR9_res_59 0;
BA_ "GenSigTimeoutTime_Lenkhilfe_ZF_2" SG_ 174 BR9_res_60 500;
BA_ "GenSigTimeoutMsg_Lenkhilfe_ZF_2" SG_ 174 BR9_res_60 174;
BA_ "GenSigTimeoutTime_Lenkhilfe_APA" SG_ 174 BR9_res_60 500;
BA_ "GenSigTimeoutMsg_Lenkhilfe_APA" SG_ 174 BR9_res_60 174;
BA_ "GenSigTimeoutTime_Lenkhilfe_ZF_3" SG_ 174 BR9_res_60 500;
BA_ "GenSigTimeoutMsg_Lenkhilfe_ZF_3" SG_ 174 BR9_res_60 174;
BA_ "GenSigSendType" SG_ 174 BR9_res_60 0;
BA_ "GenSigTimeoutTime_Lenkhilfe_ZF_3" SG_ 174 BR9_Sta_DSR 500;
BA_ "GenSigTimeoutMsg_Lenkhilfe_ZF_3" SG_ 174 BR9_Sta_DSR 174;
BA_ "GenSigTimeoutTime_Lenkhilfe_APA" SG_ 174 BR9_Sta_DSR 500;
BA_ "GenSigTimeoutMsg_Lenkhilfe_APA" SG_ 174 BR9_Sta_DSR 174;
BA_ "GenSigTimeoutTime_Lenkhilfe_ZF_2" SG_ 174 BR9_Sta_DSR 500;
BA_ "GenSigTimeoutMsg_Lenkhilfe_ZF_2" SG_ 174 BR9_Sta_DSR 174;
BA_ "GenSigSendType" SG_ 174 BR9_Sta_DSR 0;
BA_ "GenSigTimeoutTime_Lenkhilfe_ZF_2" SG_ 174 BR9_res_57 500;
BA_ "GenSigTimeoutMsg_Lenkhilfe_ZF_2" SG_ 174 BR9_res_57 174;
BA_ "GenSigTimeoutTime_Lenkhilfe_APA" SG_ 174 BR9_res_57 500;
BA_ "GenSigTimeoutMsg_Lenkhilfe_APA" SG_ 174 BR9_res_57 174;
BA_ "GenSigTimeoutTime_Lenkhilfe_ZF_3" SG_ 174 BR9_res_57 500;
BA_ "GenSigTimeoutMsg_Lenkhilfe_ZF_3" SG_ 174 BR9_res_57 174;
BA_ "GenSigSendType" SG_ 174 BR9_res_57 0;
BA_ "GenSigTimeoutTime_Lenkhilfe_ZF_2" SG_ 174 BR9_res_63 500;
BA_ "GenSigTimeoutMsg_Lenkhilfe_ZF_2" SG_ 174 BR9_res_63 174;
BA_ "GenSigTimeoutTime_Lenkhilfe_APA" SG_ 174 BR9_res_63 500;
BA_ "GenSigTimeoutMsg_Lenkhilfe_APA" SG_ 174 BR9_res_63 174;
BA_ "GenSigTimeoutTime_Lenkhilfe_ZF_3" SG_ 174 BR9_res_63 500;
BA_ "GenSigTimeoutMsg_Lenkhilfe_ZF_3" SG_ 174 BR9_res_63 174;
BA_ "GenSigSendType" SG_ 174 BR9_res_63 0;
BA_ "GenSigTimeoutTime_Lenkhilfe_ZF_2" SG_ 174 BR9_res_58 500;
BA_ "GenSigTimeoutMsg_Lenkhilfe_ZF_2" SG_ 174 BR9_res_58 174;
BA_ "GenSigTimeoutTime_Lenkhilfe_APA" SG_ 174 BR9_res_58 500;
BA_ "GenSigTimeoutMsg_Lenkhilfe_APA" SG_ 174 BR9_res_58 174;
BA_ "GenSigTimeoutTime_Lenkhilfe_ZF_3" SG_ 174 BR9_res_58 500;
BA_ "GenSigTimeoutMsg_Lenkhilfe_ZF_3" SG_ 174 BR9_res_58 174;
BA_ "GenSigSendType" SG_ 174 BR9_res_58 0;
BA_ "GenSigTimeoutTime_Lenkhilfe_ZF_2" SG_ 174 BR9_res_62 500;
BA_ "GenSigTimeoutMsg_Lenkhilfe_ZF_2" SG_ 174 BR9_res_62 174;
BA_ "GenSigTimeoutTime_Lenkhilfe_APA" SG_ 174 BR9_res_62 500;
BA_ "GenSigTimeoutMsg_Lenkhilfe_APA" SG_ 174 BR9_res_62 174;
BA_ "GenSigTimeoutTime_Lenkhilfe_ZF_3" SG_ 174 BR9_res_62 500;
BA_ "GenSigTimeoutMsg_Lenkhilfe_ZF_3" SG_ 174 BR9_res_62 174;
BA_ "GenSigSendType" SG_ 174 BR9_res_62 0;
BA_ "GenSigTimeoutTime_Lenkhilfe_ZF_2" SG_ 174 BR9_res_61 500;
BA_ "GenSigTimeoutMsg_Lenkhilfe_ZF_2" SG_ 174 BR9_res_61 174;
BA_ "GenSigTimeoutTime_Lenkhilfe_APA" SG_ 174 BR9_res_61 500;
BA_ "GenSigTimeoutMsg_Lenkhilfe_APA" SG_ 174 BR9_res_61 174;
BA_ "GenSigTimeoutTime_Lenkhilfe_ZF_3" SG_ 174 BR9_res_61 500;
BA_ "GenSigTimeoutMsg_Lenkhilfe_ZF_3" SG_ 174 BR9_res_61 174;
BA_ "GenSigSendType" SG_ 174 BR9_res_61 0;
BA_ "GenSigTimeoutTime_Magne_Ride" SG_ 684 GS1_Checksumme 500;
BA_ "GenSigTimeoutMsg_Magne_Ride" SG_ 684 GS1_Checksumme 684;
BA_ "GenSigSendType" SG_ 684 GS1_Checksumme 0;
BA_ "INIT" SG_ 684 GS1_Checksumme "CHK";
BA_ "GenSigTimeoutTime_Magne_Ride" SG_ 684 GS1_Rad_kmh 500;
BA_ "GenSigTimeoutMsg_Magne_Ride" SG_ 684 GS1_Rad_kmh 684;
BA_ "GenSigSendType" SG_ 684 GS1_Rad_kmh 0;
BA_ "GenSigStartValue" SG_ 684 GS1_Rad_kmh 65416;
BA_ "GenSigTimeoutTime_Magne_Ride" SG_ 684 GS1_QBit_Rad_kmh 500;
BA_ "GenSigTimeoutMsg_Magne_Ride" SG_ 684 GS1_QBit_Rad_kmh 684;
BA_ "GenSigSendType" SG_ 684 GS1_QBit_Rad_kmh 0;
BA_ "GenSigStartValue" SG_ 684 GS1_QBit_Rad_kmh 1;
BA_ "GenSigTimeoutTime_Magne_Ride" SG_ 684 GS1_Zaehler 500;
BA_ "GenSigTimeoutMsg_Magne_Ride" SG_ 684 GS1_Zaehler 684;
BA_ "GenSigSendType" SG_ 684 GS1_Zaehler 0;
BA_ "GenSigSendType" SG_ 684 GS1_res_04 0;
BA_ "GenSigSendType" SG_ 684 GS1_res_05 0;
BA_ "GenSigSendType" SG_ 684 GS1_res_08 0;
BA_ "GenSigSendType" SG_ 684 GS1_Fahrtrichtung 0;
BA_ "GenSigTimeoutMsg_LWS" SG_ 1986 LWI_Codierbytes 1986;
BA_ "GenSigSendType" SG_ 1986 LWI_Codierbytes 3;
BA_ "GenSigTimeoutMsg_LWS" SG_ 1986 LWI_Init_ID 1986;
BA_ "GenSigSendType" SG_ 1986 LWI_Init_ID 3;
BA_ "GenSigTimeoutTime_Gateway_PQ46_A" SG_ 928 B10_Zaehler 500;
BA_ "GenSigTimeoutMsg_Gateway_PQ46_A" SG_ 928 B10_Zaehler 928;
BA_ "GenSigTimeoutTime_Gateway_PQ35_A" SG_ 928 B10_Zaehler 500;
BA_ "GenSigTimeoutMsg_Gateway_PQ35_A" SG_ 928 B10_Zaehler 928;
BA_ "GenSigTimeoutTime_PDC_PLA" SG_ 928 B10_Zaehler 500;
BA_ "GenSigTimeoutMsg_PDC_PLA" SG_ 928 B10_Zaehler 928;
BA_ "GenSigSendType" SG_ 928 B10_Zaehler 0;
BA_ "GenSigTimeoutTime_Gateway_PQ46_A" SG_ 928 B10_QB_Wegimp_VL 500;
BA_ "GenSigTimeoutMsg_Gateway_PQ46_A" SG_ 928 B10_QB_Wegimp_VL 928;
BA_ "GenSigTimeoutTime_Gateway_PQ35_A" SG_ 928 B10_QB_Wegimp_VL 500;
BA_ "GenSigTimeoutMsg_Gateway_PQ35_A" SG_ 928 B10_QB_Wegimp_VL 928;
BA_ "GenSigTimeoutTime_PDC_PLA" SG_ 928 B10_QB_Wegimp_VL 500;
BA_ "GenSigTimeoutMsg_PDC_PLA" SG_ 928 B10_QB_Wegimp_VL 928;
BA_ "GenSigSendType" SG_ 928 B10_QB_Wegimp_VL 0;
BA_ "GenSigStartValue" SG_ 928 B10_QB_Wegimp_VL 1;
BA_ "GenSigTimeoutTime_Gateway_PQ46_A" SG_ 928 B10_QB_Wegimp_VR 500;
BA_ "GenSigTimeoutMsg_Gateway_PQ46_A" SG_ 928 B10_QB_Wegimp_VR 928;
BA_ "GenSigTimeoutTime_Gateway_PQ35_A" SG_ 928 B10_QB_Wegimp_VR 500;
BA_ "GenSigTimeoutMsg_Gateway_PQ35_A" SG_ 928 B10_QB_Wegimp_VR 928;
BA_ "GenSigTimeoutTime_PDC_PLA" SG_ 928 B10_QB_Wegimp_VR 500;
BA_ "GenSigTimeoutMsg_PDC_PLA" SG_ 928 B10_QB_Wegimp_VR 928;
BA_ "GenSigSendType" SG_ 928 B10_QB_Wegimp_VR 0;
BA_ "GenSigStartValue" SG_ 928 B10_QB_Wegimp_VR 1;
BA_ "GenSigTimeoutTime_Gateway_PQ46_A" SG_ 928 B10_QB_Wegimp_HL 500;
BA_ "GenSigTimeoutMsg_Gateway_PQ46_A" SG_ 928 B10_QB_Wegimp_HL 928;
BA_ "GenSigTimeoutTime_Gateway_PQ35_A" SG_ 928 B10_QB_Wegimp_HL 500;
BA_ "GenSigTimeoutMsg_Gateway_PQ35_A" SG_ 928 B10_QB_Wegimp_HL 928;
BA_ "GenSigTimeoutTime_PDC_PLA" SG_ 928 B10_QB_Wegimp_HL 500;
BA_ "GenSigTimeoutMsg_PDC_PLA" SG_ 928 B10_QB_Wegimp_HL 928;
BA_ "GenSigSendType" SG_ 928 B10_QB_Wegimp_HL 0;
BA_ "GenSigStartValue" SG_ 928 B10_QB_Wegimp_HL 1;
BA_ "GenSigTimeoutTime_Gateway_PQ46_A" SG_ 928 B10_QB_Wegimp_HR 500;
BA_ "GenSigTimeoutMsg_Gateway_PQ46_A" SG_ 928 B10_QB_Wegimp_HR 928;
BA_ "GenSigTimeoutTime_Gateway_PQ35_A" SG_ 928 B10_QB_Wegimp_HR 500;
BA_ "GenSigTimeoutMsg_Gateway_PQ35_A" SG_ 928 B10_QB_Wegimp_HR 928;
BA_ "GenSigTimeoutTime_PDC_PLA" SG_ 928 B10_QB_Wegimp_HR 500;
BA_ "GenSigTimeoutMsg_PDC_PLA" SG_ 928 B10_QB_Wegimp_HR 928;
BA_ "GenSigSendType" SG_ 928 B10_QB_Wegimp_HR 0;
BA_ "GenSigStartValue" SG_ 928 B10_QB_Wegimp_HR 1;
BA_ "GenSigTimeoutTime_Gateway_PQ46_A" SG_ 928 B10_Checksumme 500;
BA_ "GenSigTimeoutMsg_Gateway_PQ46_A" SG_ 928 B10_Checksumme 928;
BA_ "GenSigTimeoutTime_Gateway_PQ35_A" SG_ 928 B10_Checksumme 500;
BA_ "GenSigTimeoutMsg_Gateway_PQ35_A" SG_ 928 B10_Checksumme 928;
BA_ "GenSigTimeoutTime_PDC_PLA" SG_ 928 B10_Checksumme 500;
BA_ "GenSigTimeoutMsg_PDC_PLA" SG_ 928 B10_Checksumme 928;
BA_ "GenSigSendType" SG_ 928 B10_Checksumme 0;
BA_ "INIT" SG_ 928 B10_Checksumme "CHK";
BA_ "GenSigTimeoutTime_Gateway_PQ46_A" SG_ 928 B10_Wegimp_VL 500;
BA_ "GenSigTimeoutMsg_Gateway_PQ46_A" SG_ 928 B10_Wegimp_VL 928;
BA_ "GenSigTimeoutTime_Gateway_PQ35_A" SG_ 928 B10_Wegimp_VL 500;
BA_ "GenSigTimeoutMsg_Gateway_PQ35_A" SG_ 928 B10_Wegimp_VL 928;
BA_ "GenSigTimeoutTime_PDC_PLA" SG_ 928 B10_Wegimp_VL 500;
BA_ "GenSigTimeoutMsg_PDC_PLA" SG_ 928 B10_Wegimp_VL 928;
BA_ "GenSigSendType" SG_ 928 B10_Wegimp_VL 0;
BA_ "GenSigStartValue" SG_ 928 B10_Wegimp_VL 1021;
BA_ "GenSigTimeoutTime_Gateway_PQ46_A" SG_ 928 B10_Wegimp_VR 500;
BA_ "GenSigTimeoutMsg_Gateway_PQ46_A" SG_ 928 B10_Wegimp_VR 928;
BA_ "GenSigTimeoutTime_Gateway_PQ35_A" SG_ 928 B10_Wegimp_VR 500;
BA_ "GenSigTimeoutMsg_Gateway_PQ35_A" SG_ 928 B10_Wegimp_VR 928;
BA_ "GenSigTimeoutTime_PDC_PLA" SG_ 928 B10_Wegimp_VR 500;
BA_ "GenSigTimeoutMsg_PDC_PLA" SG_ 928 B10_Wegimp_VR 928;
BA_ "GenSigSendType" SG_ 928 B10_Wegimp_VR 0;
BA_ "GenSigStartValue" SG_ 928 B10_Wegimp_VR 1021;
BA_ "GenSigTimeoutTime_Gateway_PQ46_A" SG_ 928 B10_Wegimp_HL 500;
BA_ "GenSigTimeoutMsg_Gateway_PQ46_A" SG_ 928 B10_Wegimp_HL 928;
BA_ "GenSigTimeoutTime_Gateway_PQ35_A" SG_ 928 B10_Wegimp_HL 500;
BA_ "GenSigTimeoutMsg_Gateway_PQ35_A" SG_ 928 B10_Wegimp_HL 928;
BA_ "GenSigTimeoutTime_PDC_PLA" SG_ 928 B10_Wegimp_HL 500;
BA_ "GenSigTimeoutMsg_PDC_PLA" SG_ 928 B10_Wegimp_HL 928;
BA_ "GenSigSendType" SG_ 928 B10_Wegimp_HL 0;
BA_ "GenSigStartValue" SG_ 928 B10_Wegimp_HL 1021;
BA_ "GenSigTimeoutTime_Gateway_PQ46_A" SG_ 928 B10_Wegimp_HR 500;
BA_ "GenSigTimeoutMsg_Gateway_PQ46_A" SG_ 928 B10_Wegimp_HR 928;
BA_ "GenSigTimeoutTime_Gateway_PQ35_A" SG_ 928 B10_Wegimp_HR 500;
BA_ "GenSigTimeoutMsg_Gateway_PQ35_A" SG_ 928 B10_Wegimp_HR 928;
BA_ "GenSigTimeoutTime_PDC_PLA" SG_ 928 B10_Wegimp_HR 500;
BA_ "GenSigTimeoutMsg_PDC_PLA" SG_ 928 B10_Wegimp_HR 928;
BA_ "GenSigSendType" SG_ 928 B10_Wegimp_HR 0;
BA_ "GenSigStartValue" SG_ 928 B10_Wegimp_HR 1021;
BA_ "GenSigTimeoutTime_Gateway_PQ46_A" SG_ 928 B10_QB_Fahrtr_VL 500;
BA_ "GenSigTimeoutMsg_Gateway_PQ46_A" SG_ 928 B10_QB_Fahrtr_VL 928;
BA_ "GenSigTimeoutTime_Gateway_PQ35_A" SG_ 928 B10_QB_Fahrtr_VL 500;
BA_ "GenSigTimeoutMsg_Gateway_PQ35_A" SG_ 928 B10_QB_Fahrtr_VL 928;
BA_ "GenSigTimeoutTime_PDC_PLA" SG_ 928 B10_QB_Fahrtr_VL 500;
BA_ "GenSigTimeoutMsg_PDC_PLA" SG_ 928 B10_QB_Fahrtr_VL 928;
BA_ "GenSigSendType" SG_ 928 B10_QB_Fahrtr_VL 0;
BA_ "GenSigStartValue" SG_ 928 B10_QB_Fahrtr_VL 1;
BA_ "GenSigTimeoutTime_Gateway_PQ46_A" SG_ 928 B10_QB_Fahrtr_HL 500;
BA_ "GenSigTimeoutMsg_Gateway_PQ46_A" SG_ 928 B10_QB_Fahrtr_HL 928;
BA_ "GenSigTimeoutTime_Gateway_PQ35_A" SG_ 928 B10_QB_Fahrtr_HL 500;
BA_ "GenSigTimeoutMsg_Gateway_PQ35_A" SG_ 928 B10_QB_Fahrtr_HL 928;
BA_ "GenSigTimeoutTime_PDC_PLA" SG_ 928 B10_QB_Fahrtr_HL 500;
BA_ "GenSigTimeoutMsg_PDC_PLA" SG_ 928 B10_QB_Fahrtr_HL 928;
BA_ "GenSigSendType" SG_ 928 B10_QB_Fahrtr_HL 0;
BA_ "GenSigStartValue" SG_ 928 B10_QB_Fahrtr_HL 1;
BA_ "GenSigTimeoutTime_Gateway_PQ46_A" SG_ 928 B10_QB_Fahrtr_HR 500;
BA_ "GenSigTimeoutMsg_Gateway_PQ46_A" SG_ 928 B10_QB_Fahrtr_HR 928;
BA_ "GenSigTimeoutTime_Gateway_PQ35_A" SG_ 928 B10_QB_Fahrtr_HR 500;
BA_ "GenSigTimeoutMsg_Gateway_PQ35_A" SG_ 928 B10_QB_Fahrtr_HR 928;
BA_ "GenSigTimeoutTime_PDC_PLA" SG_ 928 B10_QB_Fahrtr_HR 500;
BA_ "GenSigTimeoutMsg_PDC_PLA" SG_ 928 B10_QB_Fahrtr_HR 928;
BA_ "GenSigSendType" SG_ 928 B10_QB_Fahrtr_HR 0;
BA_ "GenSigStartValue" SG_ 928 B10_QB_Fahrtr_HR 1;
BA_ "GenSigTimeoutTime_PDC_PLA" SG_ 928 B10_Fahrtr_HL 500;
BA_ "GenSigTimeoutMsg_PDC_PLA" SG_ 928 B10_Fahrtr_HL 928;
BA_ "GenSigTimeoutTime_Gateway_PQ35_A" SG_ 928 B10_Fahrtr_HL 500;
BA_ "GenSigTimeoutMsg_Gateway_PQ35_A" SG_ 928 B10_Fahrtr_HL 928;
BA_ "GenSigTimeoutTime_Gateway_PQ46_A" SG_ 928 B10_Fahrtr_HL 500;
BA_ "GenSigTimeoutMsg_Gateway_PQ46_A" SG_ 928 B10_Fahrtr_HL 928;
BA_ "GenSigSendType" SG_ 928 B10_Fahrtr_HL 0;
BA_ "GenSigTimeoutTime_PDC_PLA" SG_ 928 B10_Fahrtr_HR 500;
BA_ "GenSigTimeoutMsg_PDC_PLA" SG_ 928 B10_Fahrtr_HR 928;
BA_ "GenSigTimeoutTime_Gateway_PQ35_A" SG_ 928 B10_Fahrtr_HR 500;
BA_ "GenSigTimeoutMsg_Gateway_PQ35_A" SG_ 928 B10_Fahrtr_HR 928;
BA_ "GenSigTimeoutTime_Gateway_PQ46_A" SG_ 928 B10_Fahrtr_HR 500;
BA_ "GenSigTimeoutMsg_Gateway_PQ46_A" SG_ 928 B10_Fahrtr_HR 928;
BA_ "GenSigSendType" SG_ 928 B10_Fahrtr_HR 0;
BA_ "GenSigTimeoutTime_Gateway_PQ46_A" SG_ 928 B10_QB_Fahrtr_VR 500;
BA_ "GenSigTimeoutMsg_Gateway_PQ46_A" SG_ 928 B10_QB_Fahrtr_VR 928;
BA_ "GenSigTimeoutTime_Gateway_PQ35_A" SG_ 928 B10_QB_Fahrtr_VR 500;
BA_ "GenSigTimeoutMsg_Gateway_PQ35_A" SG_ 928 B10_QB_Fahrtr_VR 928;
BA_ "GenSigTimeoutTime_PDC_PLA" SG_ 928 B10_QB_Fahrtr_VR 500;
BA_ "GenSigTimeoutMsg_PDC_PLA" SG_ 928 B10_QB_Fahrtr_VR 928;
BA_ "GenSigSendType" SG_ 928 B10_QB_Fahrtr_VR 0;
BA_ "GenSigStartValue" SG_ 928 B10_QB_Fahrtr_VR 1;
BA_ "GenSigTimeoutTime_PDC_PLA" SG_ 928 B10_Fahrtr_VR 500;
BA_ "GenSigTimeoutMsg_PDC_PLA" SG_ 928 B10_Fahrtr_VR 928;
BA_ "GenSigTimeoutTime_Gateway_PQ35_A" SG_ 928 B10_Fahrtr_VR 500;
BA_ "GenSigTimeoutMsg_Gateway_PQ35_A" SG_ 928 B10_Fahrtr_VR 928;
BA_ "GenSigTimeoutTime_Gateway_PQ46_A" SG_ 928 B10_Fahrtr_VR 500;
BA_ "GenSigTimeoutMsg_Gateway_PQ46_A" SG_ 928 B10_Fahrtr_VR 928;
BA_ "GenSigSendType" SG_ 928 B10_Fahrtr_VR 0;
BA_ "GenSigTimeoutTime_PDC_PLA" SG_ 928 B10_Fahrtr_VL 500;
BA_ "GenSigTimeoutMsg_PDC_PLA" SG_ 928 B10_Fahrtr_VL 928;
BA_ "GenSigTimeoutTime_Gateway_PQ35_A" SG_ 928 B10_Fahrtr_VL 500;
BA_ "GenSigTimeoutMsg_Gateway_PQ35_A" SG_ 928 B10_Fahrtr_VL 928;
BA_ "GenSigTimeoutTime_Gateway_PQ46_A" SG_ 928 B10_Fahrtr_VL 500;
BA_ "GenSigTimeoutMsg_Gateway_PQ46_A" SG_ 928 B10_Fahrtr_VL 928;
BA_ "GenSigSendType" SG_ 928 B10_Fahrtr_VL 0;
BA_ "GenSigSendType" SG_ 1827 NMH_ABS_Abschaltstufe_aktiv 0;
BA_ "GenSigTimeoutTime_Gateway_PQ35_A" SG_ 1827 NMH_ABS_Car_WakeUp 2000;
BA_ "GenSigTimeoutMsg_Gateway_PQ35_A" SG_ 1827 NMH_ABS_Car_WakeUp 1827;
BA_ "GenSigTimeoutTime_Gateway_PQ46_A" SG_ 1827 NMH_ABS_Car_WakeUp 2000;
BA_ "GenSigTimeoutMsg_Gateway_PQ46_A" SG_ 1827 NMH_ABS_Car_WakeUp 1827;
BA_ "GenSigSendType" SG_ 1827 NMH_ABS_Car_WakeUp 0;
BA_ "GenSigSendType" SG_ 1827 NMH_ABS_Eindraht_Fehler 0;
BA_ "GenSigSendType" SG_ 1827 NMH_ABS_Fkt_WakeUp 0;
BA_ "GenSigSendType" SG_ 1827 NMH_ABS_kein_NL 0;
BA_ "GenSigSendType" SG_ 1827 NMH_ABS_KompSchutz 0;
BA_ "GenSigSendType" SG_ 1827 NMH_ABS_Mute_Mode 0;
BA_ "GenSigSendType" SG_ 1827 NMH_ABS_CAN_Diag_deaktiv 0;
BA_ "GenSigSendType" SG_ 1827 NMH_ABS_NL_1 0;
BA_ "GenSigSendType" SG_ 1827 NMH_ABS_NL_2 0;
BA_ "GenSigSendType" SG_ 1827 NMH_ABS_NL_3 0;
BA_ "GenSigSendType" SG_ 1827 NMH_ABS_NL_4 0;
BA_ "GenSigSendType" SG_ 1827 NMH_ABS_NL_5 0;
BA_ "GenSigSendType" SG_ 1827 NMH_ABS_NL_6 0;
BA_ "GenSigSendType" SG_ 1827 NMH_ABS_NL_7 0;
BA_ "GenSigSendType" SG_ 1827 NMH_ABS_NL_aktiv_5 0;
BA_ "GenSigSendType" SG_ 1827 NMH_ABS_NL_aktiv_6 0;
BA_ "GenSigSendType" SG_ 1827 NMH_ABS_NL_aktiv_7 0;
BA_ "GenSigSendType" SG_ 1827 NMH_ABS_NL_aktiv_8 0;
BA_ "GenSigSendType" SG_ 1827 NMH_ABS_NM_aktiv_Diagnose 0;
BA_ "GenSigSendType" SG_ 1827 NMH_ABS_NM_aktiv_Klemme_15 0;
BA_ "GenSigSendType" SG_ 1827 NMH_ABS_NL_aktiv_4 0;
BA_ "GenSigSendType" SG_ 1827 NMH_ABS_NM_aktiv_Start 0;
BA_ "GenSigSendType" SG_ 1827 NMH_ABS_Normal_Mode_1 0;
BA_ "GenSigSendType" SG_ 1827 NMH_ABS_Normal_Mode_2 0;
BA_ "GenSigSendType" SG_ 1827 NMH_ABS_Per_WakeUp 0;
BA_ "GenSigSendType" SG_ 1827 NMH_ABS_TimeOut_Fehler 0;
BA_ "GenSigSendType" SG_ 1827 NMH_ABS_Transport_Mode 0;
BA_ "GenSigTimeoutTime_Gateway_PQ46_A" SG_ 1827 NMH_ABS_Start_1 2000;
BA_ "GenSigTimeoutMsg_Gateway_PQ46_A" SG_ 1827 NMH_ABS_Start_1 1827;
BA_ "GenSigTimeoutTime_Gateway_PQ35_A" SG_ 1827 NMH_ABS_Start_1 2000;
BA_ "GenSigTimeoutMsg_Gateway_PQ35_A" SG_ 1827 NMH_ABS_Start_1 1827;
BA_ "GenSigSendType" SG_ 1827 NMH_ABS_Start_1 0;
BA_ "GenSigSendType" SG_ 1827 NMH_ABS_Start_2 0;
BA_ "GenSigSendType" SG_ 1827 NMH_ABS_res_04 0;
BA_ "GenSigSendType" SG_ 1827 NMH_ABS_res_05 0;
BA_ "GenSigSendType" SG_ 1827 NMH_ABS_res_07 0;
BA_ "GenSigSendType" SG_ 1827 NMH_ABS_res_32 0;
BA_ "GenSigSendType" SG_ 1827 NMH_ABS_res_40 0;
BA_ "GenSigSendType" SG_ 1827 NMH_ABS_res_41 0;
BA_ "GenSigSendType" SG_ 1827 NMH_ABS_res_42 0;
BA_ "GenSigSendType" SG_ 1827 NMH_ABS_res_43 0;
BA_ "GenSigSendType" SG_ 1827 NMH_ABS_res_44 0;
BA_ "GenSigSendType" SG_ 1827 NMH_ABS_res_45 0;
BA_ "GenSigSendType" SG_ 1827 NMH_ABS_res_46 0;
BA_ "GenSigSendType" SG_ 1827 NMH_ABS_res_47 0;
BA_ "GenSigSendType" SG_ 1827 NMH_ABS_res_48 0;
BA_ "GenSigSendType" SG_ 1827 NMH_ABS_res_49 0;
BA_ "GenSigSendType" SG_ 1827 NMH_ABS_res_50 0;
BA_ "GenSigSendType" SG_ 1827 NMH_ABS_res_51 0;
BA_ "GenSigSendType" SG_ 1827 NMH_ABS_res_52 0;
BA_ "GenSigSendType" SG_ 1827 NMH_ABS_res_53 0;
BA_ "GenSigSendType" SG_ 1827 NMH_ABS_res_54 0;
BA_ "GenSigSendType" SG_ 1827 NMH_ABS_res_55 0;
BA_ "GenSigSendType" SG_ 1463 B11_res_00 0;
BA_ "GenSigSendType" SG_ 1463 B11_res_08 0;
BA_ "GenSigTimeoutTime_Otto" SG_ 1463 B11_Br_StSt_Info 1000;
BA_ "GenSigTimeoutMsg_Otto" SG_ 1463 B11_Br_StSt_Info 1463;
BA_ "GenSigTimeoutTime_Diesel" SG_ 1463 B11_Br_StSt_Info 1000;
BA_ "GenSigTimeoutMsg_Diesel" SG_ 1463 B11_Br_StSt_Info 1463;
BA_ "GenSigSendType" SG_ 1463 B11_Br_StSt_Info 0;
BA_ "INIT" SG_ 1463 B11_Br_StSt_Info "0/3";
BA_ "GenSigTimeoutTime_Otto" SG_ 1463 B11_OBD_Nib_VL 1000;
BA_ "GenSigTimeoutMsg_Otto" SG_ 1463 B11_OBD_Nib_VL 1463;
BA_ "GenSigTimeoutTime_Diesel" SG_ 1463 B11_OBD_Nib_VL 1000;
BA_ "GenSigTimeoutMsg_Diesel" SG_ 1463 B11_OBD_Nib_VL 1463;
BA_ "GenSigSendType" SG_ 1463 B11_OBD_Nib_VL 0;
BA_ "GenSigTimeoutTime_Otto" SG_ 1463 B11_OBD_Nib_VR 1000;
BA_ "GenSigTimeoutMsg_Otto" SG_ 1463 B11_OBD_Nib_VR 1463;
BA_ "GenSigTimeoutTime_Diesel" SG_ 1463 B11_OBD_Nib_VR 1000;
BA_ "GenSigTimeoutMsg_Diesel" SG_ 1463 B11_OBD_Nib_VR 1463;
BA_ "GenSigSendType" SG_ 1463 B11_OBD_Nib_VR 0;
BA_ "GenSigTimeoutTime_Otto" SG_ 1463 B11_OBD_Nib_HL 1000;
BA_ "GenSigTimeoutMsg_Otto" SG_ 1463 B11_OBD_Nib_HL 1463;
BA_ "GenSigTimeoutTime_Diesel" SG_ 1463 B11_OBD_Nib_HL 1000;
BA_ "GenSigTimeoutMsg_Diesel" SG_ 1463 B11_OBD_Nib_HL 1463;
BA_ "GenSigSendType" SG_ 1463 B11_OBD_Nib_HL 0;
BA_ "GenSigTimeoutTime_Otto" SG_ 1463 B11_OBD_Nib_HR 1000;
BA_ "GenSigTimeoutMsg_Otto" SG_ 1463 B11_OBD_Nib_HR 1463;
BA_ "GenSigTimeoutTime_Diesel" SG_ 1463 B11_OBD_Nib_HR 1000;
BA_ "GenSigTimeoutMsg_Diesel" SG_ 1463 B11_OBD_Nib_HR 1463;
BA_ "GenSigSendType" SG_ 1463 B11_OBD_Nib_HR 0;
BA_ "GenSigTimeoutTime_Otto" SG_ 1463 B11_HydHalten 1000;
BA_ "GenSigTimeoutMsg_Otto" SG_ 1463 B11_HydHalten 1463;
BA_ "GenSigTimeoutTime_Diesel" SG_ 1463 B11_HydHalten 1000;
BA_ "GenSigTimeoutMsg_Diesel" SG_ 1463 B11_HydHalten 1463;
BA_ "GenSigSendType" SG_ 1463 B11_HydHalten 0;
BA_ "GenSigSendType" SG_ 1463 B11_res_12 0;
BA_ "GenSigTimeoutTime_Diesel" SG_ 1463 B11_EPB_Steller_akt 1000;
BA_ "GenSigTimeoutMsg_Diesel" SG_ 1463 B11_EPB_Steller_akt 1463;
BA_ "GenSigTimeoutTime_Otto" SG_ 1463 B11_EPB_Steller_akt 1000;
BA_ "GenSigTimeoutMsg_Otto" SG_ 1463 B11_EPB_Steller_akt 1463;
BA_ "GenSigSendType" SG_ 1463 B11_EPB_Steller_akt 0;
BA_ "GenSigTimeoutTime_Otto" SG_ 1463 B11_EPB_Steller_gue 1000;
BA_ "GenSigTimeoutMsg_Otto" SG_ 1463 B11_EPB_Steller_gue 1463;
BA_ "GenSigTimeoutTime_Diesel" SG_ 1463 B11_EPB_Steller_gue 1000;
BA_ "GenSigTimeoutMsg_Diesel" SG_ 1463 B11_EPB_Steller_gue 1463;
BA_ "GenSigSendType" SG_ 1463 B11_EPB_Steller_gue 0;
BA_ "GenSigSendType" SG_ 1463 B11_res_34 0;
BA_ "GenSigSendType" SG_ 1463 B11_res_35 0;
BA_ "GenSigSendType" SG_ 1463 B11_res_36 0;
BA_ "GenSigSendType" SG_ 1463 B11_res_37 0;
BA_ "GenSigSendType" SG_ 1463 B11_res_38 0;
BA_ "GenSigSendType" SG_ 1463 B11_res_39 0;
BA_ "GenSigSendType" SG_ 1463 B11_res_40 0;
BA_ "GenSigSendType" SG_ 1463 B11_res_41 0;
BA_ "GenSigSendType" SG_ 1463 B11_res_42 0;
BA_ "GenSigSendType" SG_ 1463 B11_res_43 0;
BA_ "GenSigSendType" SG_ 1463 B11_res_44 0;
BA_ "GenSigSendType" SG_ 1463 B11_res_45 0;
BA_ "GenSigSendType" SG_ 1463 B11_res_46 0;
BA_ "GenSigSendType" SG_ 1463 B11_res_47 0;
BA_ "GenSigSendType" SG_ 1463 B11_res_48 0;
BA_ "GenSigSendType" SG_ 1463 B11_res_49 0;
BA_ "GenSigSendType" SG_ 1463 B11_res_50 0;
BA_ "GenSigSendType" SG_ 1463 B11_res_51 0;
BA_ "GenSigSendType" SG_ 1463 B11_res_52 0;
BA_ "GenSigSendType" SG_ 1463 B11_res_53 0;
BA_ "GenSigSendType" SG_ 1463 B11_res_54 0;
BA_ "GenSigSendType" SG_ 1463 B11_res_55 0;
BA_ "GenSigSendType" SG_ 1463 B11_res_56 0;
BA_ "GenSigSendType" SG_ 1463 B11_res_57 0;
BA_ "GenSigSendType" SG_ 1463 B11_res_58 0;
BA_ "GenSigSendType" SG_ 1463 B11_res_59 0;
BA_ "GenSigSendType" SG_ 1463 B11_res_61 0;
BA_ "GenSigSendType" SG_ 1463 B11_res_62 0;
BA_ "GenSigSendType" SG_ 1463 B11_res_63 0;
BA_ "GenSigSendType" SG_ 1463 B11_res_60 0;
BA_ "GenSigTimeoutTime_Diesel" SG_ 194 LW1_LRW_Sign 500;
BA_ "GenSigTimeoutMsg_Diesel" SG_ 194 LW1_LRW_Sign 194;
BA_ "GenSigTimeoutTime_ACC_Lidar" SG_ 194 LW1_LRW_Sign 500;
BA_ "GenSigTimeoutMsg_ACC_Lidar" SG_ 194 LW1_LRW_Sign 194;
BA_ "GenSigTimeoutTime_HCA" SG_ 194 LW1_LRW_Sign 500;
BA_ "GenSigTimeoutMsg_HCA" SG_ 194 LW1_LRW_Sign 194;
BA_ "GenSigTimeoutTime_Hybrid_MSG" SG_ 194 LW1_LRW_Sign 500;
BA_ "GenSigTimeoutMsg_Hybrid_MSG" SG_ 194 LW1_LRW_Sign 194;
BA_ "GenSigTimeoutTime_Daempfer" SG_ 194 LW1_LRW_Sign 500;
BA_ "GenSigTimeoutMsg_Daempfer" SG_ 194 LW1_LRW_Sign 194;
BA_ "GenSigTimeoutTime_Lenkhilfe_APA" SG_ 194 LW1_LRW_Sign 500;
BA_ "GenSigTimeoutMsg_Lenkhilfe_APA" SG_ 194 LW1_LRW_Sign 194;
BA_ "GenSigTimeoutTime_RKA_Plus" SG_ 194 LW1_LRW_Sign 500;
BA_ "GenSigTimeoutMsg_RKA_Plus" SG_ 194 LW1_LRW_Sign 194;
BA_ "GenSigTimeoutTime_Magne_Ride" SG_ 194 LW1_LRW_Sign 500;
BA_ "GenSigTimeoutMsg_Magne_Ride" SG_ 194 LW1_LRW_Sign 194;
BA_ "GenSigTimeoutTime_Gateway_PQ35_A" SG_ 194 LW1_LRW_Sign 500;
BA_ "GenSigTimeoutMsg_Gateway_PQ35_A" SG_ 194 LW1_LRW_Sign 194;
BA_ "GenSigTimeoutTime_AFS" SG_ 194 LW1_LRW_Sign 500;
BA_ "GenSigTimeoutMsg_AFS" SG_ 194 LW1_LRW_Sign 194;
BA_ "GenSigTimeoutTime_ACC_Radar" SG_ 194 LW1_LRW_Sign 500;
BA_ "GenSigTimeoutMsg_ACC_Radar" SG_ 194 LW1_LRW_Sign 194;
BA_ "GenSigTimeoutTime_TRW_ESP" SG_ 194 LW1_LRW_Sign 500;
BA_ "GenSigTimeoutMsg_TRW_ESP" SG_ 194 LW1_LRW_Sign 194;
BA_ "GenSigTimeoutTime_LWR" SG_ 194 LW1_LRW_Sign 500;
BA_ "GenSigTimeoutMsg_LWR" SG_ 194 LW1_LRW_Sign 194;
BA_ "GenSigTimeoutTime_Teves_MK60_ESP" SG_ 194 LW1_LRW_Sign 500;
BA_ "GenSigTimeoutMsg_Teves_MK60_ESP" SG_ 194 LW1_LRW_Sign 194;
BA_ "GenSigTimeoutTime_Otto" SG_ 194 LW1_LRW_Sign 500;
BA_ "GenSigTimeoutMsg_Otto" SG_ 194 LW1_LRW_Sign 194;
BA_ "GenSigTimeoutTime_Lenkhilfe_ZF_2" SG_ 194 LW1_LRW_Sign 500;
BA_ "GenSigTimeoutMsg_Lenkhilfe_ZF_2" SG_ 194 LW1_LRW_Sign 194;
BA_ "GenSigTimeoutTime_Allrad" SG_ 194 LW1_LRW_Sign 500;
BA_ "GenSigTimeoutMsg_Allrad" SG_ 194 LW1_LRW_Sign 194;
BA_ "GenSigTimeoutTime_Gateway_PQ46_A" SG_ 194 LW1_LRW_Sign 500;
BA_ "GenSigTimeoutMsg_Gateway_PQ46_A" SG_ 194 LW1_LRW_Sign 194;
BA_ "GenSigSendType" SG_ 194 LW1_LRW_Sign 0;
BA_ "GenSigStartValue" SG_ 194 LW1_LRW_Sign 1;
BA_ "GenSigTimeoutTime_ACC_Lidar" SG_ 194 LW1_Lenk_Gesch 500;
BA_ "GenSigTimeoutMsg_ACC_Lidar" SG_ 194 LW1_Lenk_Gesch 194;
BA_ "GenSigTimeoutTime_HCA" SG_ 194 LW1_Lenk_Gesch 500;
BA_ "GenSigTimeoutMsg_HCA" SG_ 194 LW1_Lenk_Gesch 194;
BA_ "GenSigTimeoutTime_Daempfer" SG_ 194 LW1_Lenk_Gesch 500;
BA_ "GenSigTimeoutMsg_Daempfer" SG_ 194 LW1_Lenk_Gesch 194;
BA_ "GenSigTimeoutTime_TRW_ESP" SG_ 194 LW1_Lenk_Gesch 500;
BA_ "GenSigTimeoutMsg_TRW_ESP" SG_ 194 LW1_Lenk_Gesch 194;
BA_ "GenSigTimeoutTime_Hybrid_MSG" SG_ 194 LW1_Lenk_Gesch 500;
BA_ "GenSigTimeoutMsg_Hybrid_MSG" SG_ 194 LW1_Lenk_Gesch 194;
BA_ "GenSigTimeoutTime_Lenkhilfe_APA" SG_ 194 LW1_Lenk_Gesch 500;
BA_ "GenSigTimeoutMsg_Lenkhilfe_APA" SG_ 194 LW1_Lenk_Gesch 194;
BA_ "GenSigTimeoutTime_Magne_Ride" SG_ 194 LW1_Lenk_Gesch 500;
BA_ "GenSigTimeoutMsg_Magne_Ride" SG_ 194 LW1_Lenk_Gesch 194;
BA_ "GenSigTimeoutTime_Gateway_PQ35_A" SG_ 194 LW1_Lenk_Gesch 500;
BA_ "GenSigTimeoutMsg_Gateway_PQ35_A" SG_ 194 LW1_Lenk_Gesch 194;
BA_ "GenSigTimeoutTime_AFS" SG_ 194 LW1_Lenk_Gesch 500;
BA_ "GenSigTimeoutMsg_AFS" SG_ 194 LW1_Lenk_Gesch 194;
BA_ "GenSigTimeoutTime_ACC_Radar" SG_ 194 LW1_Lenk_Gesch 500;
BA_ "GenSigTimeoutMsg_ACC_Radar" SG_ 194 LW1_Lenk_Gesch 194;
BA_ "GenSigTimeoutTime_LWR" SG_ 194 LW1_Lenk_Gesch 500;
BA_ "GenSigTimeoutMsg_LWR" SG_ 194 LW1_Lenk_Gesch 194;
BA_ "GenSigTimeoutTime_Teves_MK60_ESP" SG_ 194 LW1_Lenk_Gesch 500;
BA_ "GenSigTimeoutMsg_Teves_MK60_ESP" SG_ 194 LW1_Lenk_Gesch 194;
BA_ "GenSigTimeoutTime_Otto" SG_ 194 LW1_Lenk_Gesch 500;
BA_ "GenSigTimeoutMsg_Otto" SG_ 194 LW1_Lenk_Gesch 194;
BA_ "GenSigTimeoutTime_Lenkhilfe_ZF_2" SG_ 194 LW1_Lenk_Gesch 500;
BA_ "GenSigTimeoutMsg_Lenkhilfe_ZF_2" SG_ 194 LW1_Lenk_Gesch 194;
BA_ "GenSigTimeoutTime_Gateway_PQ46_A" SG_ 194 LW1_Lenk_Gesch 500;
BA_ "GenSigTimeoutMsg_Gateway_PQ46_A" SG_ 194 LW1_Lenk_Gesch 194;
BA_ "GenSigSendType" SG_ 194 LW1_Lenk_Gesch 0;
BA_ "GenSigTimeoutTime_ACC_Lidar" SG_ 194 LW1_Gesch_Sign 500;
BA_ "GenSigTimeoutMsg_ACC_Lidar" SG_ 194 LW1_Gesch_Sign 194;
BA_ "GenSigTimeoutTime_HCA" SG_ 194 LW1_Gesch_Sign 500;
BA_ "GenSigTimeoutMsg_HCA" SG_ 194 LW1_Gesch_Sign 194;
BA_ "GenSigTimeoutTime_Daempfer" SG_ 194 LW1_Gesch_Sign 500;
BA_ "GenSigTimeoutMsg_Daempfer" SG_ 194 LW1_Gesch_Sign 194;
BA_ "GenSigTimeoutTime_TRW_ESP" SG_ 194 LW1_Gesch_Sign 500;
BA_ "GenSigTimeoutMsg_TRW_ESP" SG_ 194 LW1_Gesch_Sign 194;
BA_ "GenSigTimeoutTime_Hybrid_MSG" SG_ 194 LW1_Gesch_Sign 500;
BA_ "GenSigTimeoutMsg_Hybrid_MSG" SG_ 194 LW1_Gesch_Sign 194;
BA_ "GenSigTimeoutTime_Lenkhilfe_APA" SG_ 194 LW1_Gesch_Sign 500;
BA_ "GenSigTimeoutMsg_Lenkhilfe_APA" SG_ 194 LW1_Gesch_Sign 194;
BA_ "GenSigTimeoutTime_Magne_Ride" SG_ 194 LW1_Gesch_Sign 500;
BA_ "GenSigTimeoutMsg_Magne_Ride" SG_ 194 LW1_Gesch_Sign 194;
BA_ "GenSigTimeoutTime_Gateway_PQ35_A" SG_ 194 LW1_Gesch_Sign 500;
BA_ "GenSigTimeoutMsg_Gateway_PQ35_A" SG_ 194 LW1_Gesch_Sign 194;
BA_ "GenSigTimeoutTime_AFS" SG_ 194 LW1_Gesch_Sign 500;
BA_ "GenSigTimeoutMsg_AFS" SG_ 194 LW1_Gesch_Sign 194;
BA_ "GenSigTimeoutTime_ACC_Radar" SG_ 194 LW1_Gesch_Sign 500;
BA_ "GenSigTimeoutMsg_ACC_Radar" SG_ 194 LW1_Gesch_Sign 194;
BA_ "GenSigTimeoutTime_LWR" SG_ 194 LW1_Gesch_Sign 500;
BA_ "GenSigTimeoutMsg_LWR" SG_ 194 LW1_Gesch_Sign 194;
BA_ "GenSigTimeoutTime_Teves_MK60_ESP" SG_ 194 LW1_Gesch_Sign 500;
BA_ "GenSigTimeoutMsg_Teves_MK60_ESP" SG_ 194 LW1_Gesch_Sign 194;
BA_ "GenSigTimeoutTime_Otto" SG_ 194 LW1_Gesch_Sign 500;
BA_ "GenSigTimeoutMsg_Otto" SG_ 194 LW1_Gesch_Sign 194;
BA_ "GenSigTimeoutTime_Lenkhilfe_ZF_2" SG_ 194 LW1_Gesch_Sign 500;
BA_ "GenSigTimeoutMsg_Lenkhilfe_ZF_2" SG_ 194 LW1_Gesch_Sign 194;
BA_ "GenSigTimeoutTime_Gateway_PQ46_A" SG_ 194 LW1_Gesch_Sign 500;
BA_ "GenSigTimeoutMsg_Gateway_PQ46_A" SG_ 194 LW1_Gesch_Sign 194;
BA_ "GenSigSendType" SG_ 194 LW1_Gesch_Sign 0;
BA_ "GenSigStartValue" SG_ 194 LW1_Gesch_Sign 1;
BA_ "GenSigTimeoutTime_Lenkhilfe_APA" SG_ 194 LW1_ID 500;
BA_ "GenSigTimeoutMsg_Lenkhilfe_APA" SG_ 194 LW1_ID 194;
BA_ "GenSigTimeoutTime_Magne_Ride" SG_ 194 LW1_ID 500;
BA_ "GenSigTimeoutMsg_Magne_Ride" SG_ 194 LW1_ID 194;
BA_ "GenSigTimeoutTime_Gateway_PQ35_A" SG_ 194 LW1_ID 500;
BA_ "GenSigTimeoutMsg_Gateway_PQ35_A" SG_ 194 LW1_ID 194;
BA_ "GenSigTimeoutTime_AFS" SG_ 194 LW1_ID 500;
BA_ "GenSigTimeoutMsg_AFS" SG_ 194 LW1_ID 194;
BA_ "GenSigTimeoutTime_TRW_ESP" SG_ 194 LW1_ID 500;
BA_ "GenSigTimeoutMsg_TRW_ESP" SG_ 194 LW1_ID 194;
BA_ "GenSigTimeoutTime_LWR" SG_ 194 LW1_ID 500;
BA_ "GenSigTimeoutMsg_LWR" SG_ 194 LW1_ID 194;
BA_ "GenSigTimeoutTime_Teves_MK60_ESP" SG_ 194 LW1_ID 500;
BA_ "GenSigTimeoutMsg_Teves_MK60_ESP" SG_ 194 LW1_ID 194;
BA_ "GenSigTimeoutTime_Lenkhilfe_ZF_2" SG_ 194 LW1_ID 500;
BA_ "GenSigTimeoutMsg_Lenkhilfe_ZF_2" SG_ 194 LW1_ID 194;
BA_ "GenSigTimeoutTime_Gateway_PQ46_A" SG_ 194 LW1_ID 500;
BA_ "GenSigTimeoutMsg_Gateway_PQ46_A" SG_ 194 LW1_ID 194;
BA_ "GenSigSendType" SG_ 194 LW1_ID 0;
BA_ "GenSigTimeoutTime_ACC_Lidar" SG_ 194 LW1_Initquelle 500;
BA_ "GenSigTimeoutMsg_ACC_Lidar" SG_ 194 LW1_Initquelle 194;
BA_ "GenSigTimeoutTime_HCA" SG_ 194 LW1_Initquelle 500;
BA_ "GenSigTimeoutMsg_HCA" SG_ 194 LW1_Initquelle 194;
BA_ "GenSigTimeoutTime_Daempfer" SG_ 194 LW1_Initquelle 500;
BA_ "GenSigTimeoutMsg_Daempfer" SG_ 194 LW1_Initquelle 194;
BA_ "GenSigTimeoutTime_Lenkhilfe_APA" SG_ 194 LW1_Initquelle 500;
BA_ "GenSigTimeoutMsg_Lenkhilfe_APA" SG_ 194 LW1_Initquelle 194;
BA_ "GenSigTimeoutTime_Gateway_PQ35_A" SG_ 194 LW1_Initquelle 500;
BA_ "GenSigTimeoutMsg_Gateway_PQ35_A" SG_ 194 LW1_Initquelle 194;
BA_ "GenSigTimeoutTime_AFS" SG_ 194 LW1_Initquelle 500;
BA_ "GenSigTimeoutMsg_AFS" SG_ 194 LW1_Initquelle 194;
BA_ "GenSigTimeoutTime_ACC_Radar" SG_ 194 LW1_Initquelle 500;
BA_ "GenSigTimeoutMsg_ACC_Radar" SG_ 194 LW1_Initquelle 194;
BA_ "GenSigTimeoutTime_TRW_ESP" SG_ 194 LW1_Initquelle 500;
BA_ "GenSigTimeoutMsg_TRW_ESP" SG_ 194 LW1_Initquelle 194;
BA_ "GenSigTimeoutTime_LWR" SG_ 194 LW1_Initquelle 500;
BA_ "GenSigTimeoutMsg_LWR" SG_ 194 LW1_Initquelle 194;
BA_ "GenSigTimeoutTime_Teves_MK60_ESP" SG_ 194 LW1_Initquelle 500;
BA_ "GenSigTimeoutMsg_Teves_MK60_ESP" SG_ 194 LW1_Initquelle 194;
BA_ "GenSigTimeoutTime_Lenkhilfe_ZF_2" SG_ 194 LW1_Initquelle 500;
BA_ "GenSigTimeoutMsg_Lenkhilfe_ZF_2" SG_ 194 LW1_Initquelle 194;
BA_ "GenSigTimeoutTime_Gateway_PQ46_A" SG_ 194 LW1_Initquelle 500;
BA_ "GenSigTimeoutMsg_Gateway_PQ46_A" SG_ 194 LW1_Initquelle 194;
BA_ "GenSigSendType" SG_ 194 LW1_Initquelle 0;
BA_ "INIT" SG_ 194 LW1_Initquelle "const";
BA_ "GenSigTimeoutTime_ACC_Lidar" SG_ 194 LW1_Status 500;
BA_ "GenSigTimeoutMsg_ACC_Lidar" SG_ 194 LW1_Status 194;
BA_ "GenSigTimeoutTime_Allrad" SG_ 194 LW1_Status 500;
BA_ "GenSigTimeoutMsg_Allrad" SG_ 194 LW1_Status 194;
BA_ "GenSigTimeoutTime_HCA" SG_ 194 LW1_Status 500;
BA_ "GenSigTimeoutMsg_HCA" SG_ 194 LW1_Status 194;
BA_ "GenSigTimeoutTime_Hybrid_DQ200" SG_ 194 LW1_Status 500;
BA_ "GenSigTimeoutMsg_Hybrid_DQ200" SG_ 194 LW1_Status 194;
BA_ "GenSigTimeoutTime_Hybrid_MSG" SG_ 194 LW1_Status 500;
BA_ "GenSigTimeoutMsg_Hybrid_MSG" SG_ 194 LW1_Status 194;
BA_ "GenSigTimeoutTime_Daempfer" SG_ 194 LW1_Status 500;
BA_ "GenSigTimeoutMsg_Daempfer" SG_ 194 LW1_Status 194;
BA_ "GenSigTimeoutTime_Lenkhilfe_APA" SG_ 194 LW1_Status 500;
BA_ "GenSigTimeoutMsg_Lenkhilfe_APA" SG_ 194 LW1_Status 194;
BA_ "GenSigTimeoutTime_RKA_Plus" SG_ 194 LW1_Status 500;
BA_ "GenSigTimeoutMsg_RKA_Plus" SG_ 194 LW1_Status 194;
BA_ "GenSigTimeoutTime_Magne_Ride" SG_ 194 LW1_Status 500;
BA_ "GenSigTimeoutMsg_Magne_Ride" SG_ 194 LW1_Status 194;
BA_ "GenSigTimeoutTime_Gateway_PQ35_A" SG_ 194 LW1_Status 500;
BA_ "GenSigTimeoutMsg_Gateway_PQ35_A" SG_ 194 LW1_Status 194;
BA_ "GenSigTimeoutTime_AFS" SG_ 194 LW1_Status 500;
BA_ "GenSigTimeoutMsg_AFS" SG_ 194 LW1_Status 194;
BA_ "GenSigTimeoutTime_ACC_Radar" SG_ 194 LW1_Status 500;
BA_ "GenSigTimeoutMsg_ACC_Radar" SG_ 194 LW1_Status 194;
BA_ "GenSigTimeoutTime_TRW_ESP" SG_ 194 LW1_Status 500;
BA_ "GenSigTimeoutMsg_TRW_ESP" SG_ 194 LW1_Status 194;
BA_ "GenSigTimeoutTime_DQ" SG_ 194 LW1_Status 500;
BA_ "GenSigTimeoutMsg_DQ" SG_ 194 LW1_Status 194;
BA_ "GenSigTimeoutTime_LWR" SG_ 194 LW1_Status 500;
BA_ "GenSigTimeoutMsg_LWR" SG_ 194 LW1_Status 194;
BA_ "GenSigTimeoutTime_Teves_MK60_ESP" SG_ 194 LW1_Status 500;
BA_ "GenSigTimeoutMsg_Teves_MK60_ESP" SG_ 194 LW1_Status 194;
BA_ "GenSigTimeoutTime_Otto" SG_ 194 LW1_Status 500;
BA_ "GenSigTimeoutMsg_Otto" SG_ 194 LW1_Status 194;
BA_ "GenSigTimeoutTime_Lenkhilfe_ZF_2" SG_ 194 LW1_Status 500;
BA_ "GenSigTimeoutMsg_Lenkhilfe_ZF_2" SG_ 194 LW1_Status 194;
BA_ "GenSigTimeoutTime_Gateway_PQ46_A" SG_ 194 LW1_Status 500;
BA_ "GenSigTimeoutMsg_Gateway_PQ46_A" SG_ 194 LW1_Status 194;
BA_ "GenSigSendType" SG_ 194 LW1_Status 0;
BA_ "GenSigStartValue" SG_ 194 LW1_Status 1;
BA_ "GenSigTimeoutTime_Diesel" SG_ 194 LW1_LRW 500;
BA_ "GenSigTimeoutMsg_Diesel" SG_ 194 LW1_LRW 194;
BA_ "GenSigTimeoutTime_ACC_Lidar" SG_ 194 LW1_LRW 500;
BA_ "GenSigTimeoutMsg_ACC_Lidar" SG_ 194 LW1_LRW 194;
BA_ "GenSigTimeoutTime_HCA" SG_ 194 LW1_LRW 500;
BA_ "GenSigTimeoutMsg_HCA" SG_ 194 LW1_LRW 194;
BA_ "GenSigTimeoutTime_Hybrid_DQ200" SG_ 194 LW1_LRW 500;
BA_ "GenSigTimeoutMsg_Hybrid_DQ200" SG_ 194 LW1_LRW 194;
BA_ "GenSigTimeoutTime_Hybrid_MSG" SG_ 194 LW1_LRW 500;
BA_ "GenSigTimeoutMsg_Hybrid_MSG" SG_ 194 LW1_LRW 194;
BA_ "GenSigTimeoutTime_Daempfer" SG_ 194 LW1_LRW 500;
BA_ "GenSigTimeoutMsg_Daempfer" SG_ 194 LW1_LRW 194;
BA_ "GenSigTimeoutTime_Lenkhilfe_APA" SG_ 194 LW1_LRW 500;
BA_ "GenSigTimeoutMsg_Lenkhilfe_APA" SG_ 194 LW1_LRW 194;
BA_ "GenSigTimeoutTime_RKA_Plus" SG_ 194 LW1_LRW 500;
BA_ "GenSigTimeoutMsg_RKA_Plus" SG_ 194 LW1_LRW 194;
BA_ "GenSigTimeoutTime_Magne_Ride" SG_ 194 LW1_LRW 500;
BA_ "GenSigTimeoutMsg_Magne_Ride" SG_ 194 LW1_LRW 194;
BA_ "GenSigTimeoutTime_Gateway_PQ35_A" SG_ 194 LW1_LRW 500;
BA_ "GenSigTimeoutMsg_Gateway_PQ35_A" SG_ 194 LW1_LRW 194;
BA_ "GenSigTimeoutTime_AFS" SG_ 194 LW1_LRW 500;
BA_ "GenSigTimeoutMsg_AFS" SG_ 194 LW1_LRW 194;
BA_ "GenSigTimeoutTime_ACC_Radar" SG_ 194 LW1_LRW 500;
BA_ "GenSigTimeoutMsg_ACC_Radar" SG_ 194 LW1_LRW 194;
BA_ "GenSigTimeoutTime_TRW_ESP" SG_ 194 LW1_LRW 500;
BA_ "GenSigTimeoutMsg_TRW_ESP" SG_ 194 LW1_LRW 194;
BA_ "GenSigTimeoutTime_DQ" SG_ 194 LW1_LRW 500;
BA_ "GenSigTimeoutMsg_DQ" SG_ 194 LW1_LRW 194;
BA_ "GenSigTimeoutTime_LWR" SG_ 194 LW1_LRW 500;
BA_ "GenSigTimeoutMsg_LWR" SG_ 194 LW1_LRW 194;
BA_ "GenSigTimeoutTime_Teves_MK60_ESP" SG_ 194 LW1_LRW 500;
BA_ "GenSigTimeoutMsg_Teves_MK60_ESP" SG_ 194 LW1_LRW 194;
BA_ "GenSigTimeoutTime_Otto" SG_ 194 LW1_LRW 500;
BA_ "GenSigTimeoutMsg_Otto" SG_ 194 LW1_LRW 194;
BA_ "GenSigTimeoutTime_Lenkhilfe_ZF_2" SG_ 194 LW1_LRW 500;
BA_ "GenSigTimeoutMsg_Lenkhilfe_ZF_2" SG_ 194 LW1_LRW 194;
BA_ "GenSigTimeoutTime_Allrad" SG_ 194 LW1_LRW 500;
BA_ "GenSigTimeoutMsg_Allrad" SG_ 194 LW1_LRW 194;
BA_ "GenSigTimeoutTime_Gateway_PQ46_A" SG_ 194 LW1_LRW 500;
BA_ "GenSigTimeoutMsg_Gateway_PQ46_A" SG_ 194 LW1_LRW 194;
BA_ "GenSigSendType" SG_ 194 LW1_LRW 0;
BA_ "GenSigTimeoutTime_ACC_Lidar" SG_ 194 LW1_Sta_KL30 500;
BA_ "GenSigTimeoutMsg_ACC_Lidar" SG_ 194 LW1_Sta_KL30 194;
BA_ "GenSigTimeoutTime_HCA" SG_ 194 LW1_Sta_KL30 500;
BA_ "GenSigTimeoutMsg_HCA" SG_ 194 LW1_Sta_KL30 194;
BA_ "GenSigTimeoutTime_Daempfer" SG_ 194 LW1_Sta_KL30 500;
BA_ "GenSigTimeoutMsg_Daempfer" SG_ 194 LW1_Sta_KL30 194;
BA_ "GenSigTimeoutTime_Lenkhilfe_APA" SG_ 194 LW1_Sta_KL30 500;
BA_ "GenSigTimeoutMsg_Lenkhilfe_APA" SG_ 194 LW1_Sta_KL30 194;
BA_ "GenSigTimeoutTime_Magne_Ride" SG_ 194 LW1_Sta_KL30 500;
BA_ "GenSigTimeoutMsg_Magne_Ride" SG_ 194 LW1_Sta_KL30 194;
BA_ "GenSigTimeoutTime_Gateway_PQ35_A" SG_ 194 LW1_Sta_KL30 500;
BA_ "GenSigTimeoutMsg_Gateway_PQ35_A" SG_ 194 LW1_Sta_KL30 194;
BA_ "GenSigTimeoutTime_AFS" SG_ 194 LW1_Sta_KL30 500;
BA_ "GenSigTimeoutMsg_AFS" SG_ 194 LW1_Sta_KL30 194;
BA_ "GenSigTimeoutTime_ACC_Radar" SG_ 194 LW1_Sta_KL30 500;
BA_ "GenSigTimeoutMsg_ACC_Radar" SG_ 194 LW1_Sta_KL30 194;
BA_ "GenSigTimeoutTime_TRW_ESP" SG_ 194 LW1_Sta_KL30 500;
BA_ "GenSigTimeoutMsg_TRW_ESP" SG_ 194 LW1_Sta_KL30 194;
BA_ "GenSigTimeoutTime_LWR" SG_ 194 LW1_Sta_KL30 500;
BA_ "GenSigTimeoutMsg_LWR" SG_ 194 LW1_Sta_KL30 194;
BA_ "GenSigTimeoutTime_Teves_MK60_ESP" SG_ 194 LW1_Sta_KL30 500;
BA_ "GenSigTimeoutMsg_Teves_MK60_ESP" SG_ 194 LW1_Sta_KL30 194;
BA_ "GenSigTimeoutTime_Gateway_PQ46_A" SG_ 194 LW1_Sta_KL30 500;
BA_ "GenSigTimeoutMsg_Gateway_PQ46_A" SG_ 194 LW1_Sta_KL30 194;
BA_ "GenSigSendType" SG_ 194 LW1_Sta_KL30 0;
BA_ "GenSigTimeoutTime_Lenkhilfe_APA" SG_ 194 LW1_CRC8CHK 500;
BA_ "GenSigTimeoutMsg_Lenkhilfe_APA" SG_ 194 LW1_CRC8CHK 194;
BA_ "GenSigTimeoutTime_Gateway_PQ35_A" SG_ 194 LW1_CRC8CHK 500;
BA_ "GenSigTimeoutMsg_Gateway_PQ35_A" SG_ 194 LW1_CRC8CHK 194;
BA_ "GenSigTimeoutTime_Gateway_PQ46_A" SG_ 194 LW1_CRC8CHK 500;
BA_ "GenSigTimeoutMsg_Gateway_PQ46_A" SG_ 194 LW1_CRC8CHK 194;
BA_ "GenSigSendType" SG_ 194 LW1_CRC8CHK 0;
BA_ "GenSigTimeoutTime_ACC_Lidar" SG_ 194 LW1_CRC 500;
BA_ "GenSigTimeoutMsg_ACC_Lidar" SG_ 194 LW1_CRC 194;
BA_ "GenSigTimeoutTime_HCA" SG_ 194 LW1_CRC 500;
BA_ "GenSigTimeoutMsg_HCA" SG_ 194 LW1_CRC 194;
BA_ "GenSigTimeoutTime_Daempfer" SG_ 194 LW1_CRC 500;
BA_ "GenSigTimeoutMsg_Daempfer" SG_ 194 LW1_CRC 194;
BA_ "GenSigTimeoutTime_Lenkhilfe_APA" SG_ 194 LW1_CRC 500;
BA_ "GenSigTimeoutMsg_Lenkhilfe_APA" SG_ 194 LW1_CRC 194;
BA_ "GenSigTimeoutTime_Magne_Ride" SG_ 194 LW1_CRC 500;
BA_ "GenSigTimeoutMsg_Magne_Ride" SG_ 194 LW1_CRC 194;
BA_ "GenSigTimeoutTime_Gateway_PQ35_A" SG_ 194 LW1_CRC 500;
BA_ "GenSigTimeoutMsg_Gateway_PQ35_A" SG_ 194 LW1_CRC 194;
BA_ "GenSigTimeoutTime_AFS" SG_ 194 LW1_CRC 500;
BA_ "GenSigTimeoutMsg_AFS" SG_ 194 LW1_CRC 194;
BA_ "GenSigTimeoutTime_ACC_Radar" SG_ 194 LW1_CRC 500;
BA_ "GenSigTimeoutMsg_ACC_Radar" SG_ 194 LW1_CRC 194;
BA_ "GenSigTimeoutTime_TRW_ESP" SG_ 194 LW1_CRC 500;
BA_ "GenSigTimeoutMsg_TRW_ESP" SG_ 194 LW1_CRC 194;
BA_ "GenSigTimeoutTime_LWR" SG_ 194 LW1_CRC 500;
BA_ "GenSigTimeoutMsg_LWR" SG_ 194 LW1_CRC 194;
BA_ "GenSigTimeoutTime_Teves_MK60_ESP" SG_ 194 LW1_CRC 500;
BA_ "GenSigTimeoutMsg_Teves_MK60_ESP" SG_ 194 LW1_CRC 194;
BA_ "GenSigTimeoutTime_Gateway_PQ46_A" SG_ 194 LW1_CRC 500;
BA_ "GenSigTimeoutMsg_Gateway_PQ46_A" SG_ 194 LW1_CRC 194;
BA_ "GenSigSendType" SG_ 194 LW1_CRC 0;
BA_ "GenSigTimeoutTime_ACC_Lidar" SG_ 194 LW1_Zaehler 500;
BA_ "GenSigTimeoutMsg_ACC_Lidar" SG_ 194 LW1_Zaehler 194;
BA_ "GenSigTimeoutTime_HCA" SG_ 194 LW1_Zaehler 500;
BA_ "GenSigTimeoutMsg_HCA" SG_ 194 LW1_Zaehler 194;
BA_ "GenSigTimeoutTime_Daempfer" SG_ 194 LW1_Zaehler 500;
BA_ "GenSigTimeoutMsg_Daempfer" SG_ 194 LW1_Zaehler 194;
BA_ "GenSigTimeoutTime_Lenkhilfe_APA" SG_ 194 LW1_Zaehler 500;
BA_ "GenSigTimeoutMsg_Lenkhilfe_APA" SG_ 194 LW1_Zaehler 194;
BA_ "GenSigTimeoutTime_Magne_Ride" SG_ 194 LW1_Zaehler 500;
BA_ "GenSigTimeoutMsg_Magne_Ride" SG_ 194 LW1_Zaehler 194;
BA_ "GenSigTimeoutTime_Gateway_PQ35_A" SG_ 194 LW1_Zaehler 500;
BA_ "GenSigTimeoutMsg_Gateway_PQ35_A" SG_ 194 LW1_Zaehler 194;
BA_ "GenSigTimeoutTime_AFS" SG_ 194 LW1_Zaehler 500;
BA_ "GenSigTimeoutMsg_AFS" SG_ 194 LW1_Zaehler 194;
BA_ "GenSigTimeoutTime_ACC_Radar" SG_ 194 LW1_Zaehler 500;
BA_ "GenSigTimeoutMsg_ACC_Radar" SG_ 194 LW1_Zaehler 194;
BA_ "GenSigTimeoutTime_TRW_ESP" SG_ 194 LW1_Zaehler 500;
BA_ "GenSigTimeoutMsg_TRW_ESP" SG_ 194 LW1_Zaehler 194;
BA_ "GenSigTimeoutTime_LWR" SG_ 194 LW1_Zaehler 500;
BA_ "GenSigTimeoutMsg_LWR" SG_ 194 LW1_Zaehler 194;
BA_ "GenSigTimeoutTime_Teves_MK60_ESP" SG_ 194 LW1_Zaehler 500;
BA_ "GenSigTimeoutMsg_Teves_MK60_ESP" SG_ 194 LW1_Zaehler 194;
BA_ "GenSigTimeoutTime_Gateway_PQ46_A" SG_ 194 LW1_Zaehler 500;
BA_ "GenSigTimeoutMsg_Gateway_PQ46_A" SG_ 194 LW1_Zaehler 194;
BA_ "GenSigSendType" SG_ 194 LW1_Zaehler 0;
BA_ "GenSigTimeoutMsg_Gateway_PQ35_A" SG_ 531 LWS_TP_Er 531;
BA_ "GenSigTimeoutMsg_Gateway_PQ46_A" SG_ 531 LWS_TP_Er 531;
BA_ "GenSigSendType" SG_ 531 LWS_TP_Er 5;
BA_ "GenSigTimeoutMsg_Gateway_PQ35_A" SG_ 518 Dyn_LWR_TP_Er 518;
BA_ "GenSigTimeoutMsg_Gateway_PQ46_A" SG_ 518 Dyn_LWR_TP_Er 518;
BA_ "GenSigSendType" SG_ 518 Dyn_LWR_TP_Er 5;
BA_ "GenSigTimeoutTime_Gateway_PQ35_A" SG_ 916 LRZ_Grundeinst 1000;
BA_ "GenSigTimeoutMsg_Gateway_PQ35_A" SG_ 916 LRZ_Grundeinst 916;
BA_ "GenSigTimeoutTime_Gateway_PQ46_A" SG_ 916 LRZ_Grundeinst 1000;
BA_ "GenSigTimeoutMsg_Gateway_PQ46_A" SG_ 916 LRZ_Grundeinst 916;
BA_ "GenSigSendType" SG_ 916 LRZ_Grundeinst 0;
BA_ "GenSigTimeoutTime_Gateway_PQ35_A" SG_ 916 LRZ_Initlauf 1000;
BA_ "GenSigTimeoutMsg_Gateway_PQ35_A" SG_ 916 LRZ_Initlauf 916;
BA_ "GenSigTimeoutTime_Gateway_PQ46_A" SG_ 916 LRZ_Initlauf 1000;
BA_ "GenSigTimeoutMsg_Gateway_PQ46_A" SG_ 916 LRZ_Initlauf 916;
BA_ "GenSigSendType" SG_ 916 LRZ_Initlauf 0;
BA_ "GenSigTimeoutTime_Gateway_PQ35_A" SG_ 916 LRZ_Einfedg_hi 1000;
BA_ "GenSigTimeoutMsg_Gateway_PQ35_A" SG_ 916 LRZ_Einfedg_hi 916;
BA_ "GenSigTimeoutTime_Gateway_PQ46_A" SG_ 916 LRZ_Einfedg_hi 1000;
BA_ "GenSigTimeoutMsg_Gateway_PQ46_A" SG_ 916 LRZ_Einfedg_hi 916;
BA_ "GenSigSendType" SG_ 916 LRZ_Einfedg_hi 0;
BA_ "GenSigTimeoutTime_Gateway_PQ35_A" SG_ 916 LRZ_Fehlerlampe 1000;
BA_ "GenSigTimeoutMsg_Gateway_PQ35_A" SG_ 916 LRZ_Fehlerlampe 916;
BA_ "GenSigTimeoutTime_Gateway_PQ46_A" SG_ 916 LRZ_Fehlerlampe 1000;
BA_ "GenSigTimeoutMsg_Gateway_PQ46_A" SG_ 916 LRZ_Fehlerlampe 916;
BA_ "GenSigSendType" SG_ 916 LRZ_Fehlerlampe 0;
BA_ "GenSigTimeoutTime_Gateway_PQ35_A" SG_ 916 LRZ_Einfedg_vo 1000;
BA_ "GenSigTimeoutMsg_Gateway_PQ35_A" SG_ 916 LRZ_Einfedg_vo 916;
BA_ "GenSigTimeoutTime_Gateway_PQ46_A" SG_ 916 LRZ_Einfedg_vo 1000;
BA_ "GenSigTimeoutMsg_Gateway_PQ46_A" SG_ 916 LRZ_Einfedg_vo 916;
BA_ "GenSigSendType" SG_ 916 LRZ_Einfedg_vo 0;
BA_ "GenSigTimeoutTime_Gateway_PQ35_A" SG_ 916 LRZ_Sichere_Pos 1000;
BA_ "GenSigTimeoutMsg_Gateway_PQ35_A" SG_ 916 LRZ_Sichere_Pos 916;
BA_ "GenSigTimeoutTime_Gateway_PQ46_A" SG_ 916 LRZ_Sichere_Pos 1000;
BA_ "GenSigTimeoutMsg_Gateway_PQ46_A" SG_ 916 LRZ_Sichere_Pos 916;
BA_ "GenSigSendType" SG_ 916 LRZ_Sichere_Pos 0;
BA_ "GenSigTimeoutTime_Gateway_PQ35_A" SG_ 916 LRZ_Stellung 1000;
BA_ "GenSigTimeoutMsg_Gateway_PQ35_A" SG_ 916 LRZ_Stellung 916;
BA_ "GenSigTimeoutTime_Gateway_PQ46_A" SG_ 916 LRZ_Stellung 1000;
BA_ "GenSigTimeoutMsg_Gateway_PQ46_A" SG_ 916 LRZ_Stellung 916;
BA_ "GenSigSendType" SG_ 916 LRZ_Stellung 0;
BA_ "GenSigStartValue" SG_ 916 LRZ_Stellung 254;
BA_ "GenSigTimeoutTime_Gateway_PQ35_A" SG_ 916 LRZ_Fehler 1000;
BA_ "GenSigTimeoutMsg_Gateway_PQ35_A" SG_ 916 LRZ_Fehler 916;
BA_ "GenSigTimeoutTime_Gateway_PQ46_A" SG_ 916 LRZ_Fehler 1000;
BA_ "GenSigTimeoutMsg_Gateway_PQ46_A" SG_ 916 LRZ_Fehler 916;
BA_ "GenSigSendType" SG_ 916 LRZ_Fehler 0;
BA_ "GenSigTimeoutTime_Gateway_PQ35_A" SG_ 916 LRZ_Modus 1000;
BA_ "GenSigTimeoutMsg_Gateway_PQ35_A" SG_ 916 LRZ_Modus 916;
BA_ "GenSigTimeoutTime_Gateway_PQ46_A" SG_ 916 LRZ_Modus 1000;
BA_ "GenSigTimeoutMsg_Gateway_PQ46_A" SG_ 916 LRZ_Modus 916;
BA_ "GenSigSendType" SG_ 916 LRZ_Modus 0;
BA_ "INIT" SG_ 916 LRZ_Modus "const";
BA_ "GenSigTimeoutTime_Gateway_PQ35_A" SG_ 916 LRZ_LampeAFS 1000;
BA_ "GenSigTimeoutMsg_Gateway_PQ35_A" SG_ 916 LRZ_LampeAFS 916;
BA_ "GenSigTimeoutTime_Gateway_PQ46_A" SG_ 916 LRZ_LampeAFS 1000;
BA_ "GenSigTimeoutMsg_Gateway_PQ46_A" SG_ 916 LRZ_LampeAFS 916;
BA_ "GenSigSendType" SG_ 916 LRZ_LampeAFS 0;
BA_ "GenSigTimeoutTime_Gateway_PQ35_A" SG_ 916 LRZ_Parameter 1000;
BA_ "GenSigTimeoutMsg_Gateway_PQ35_A" SG_ 916 LRZ_Parameter 916;
BA_ "GenSigTimeoutTime_Gateway_PQ46_A" SG_ 916 LRZ_Parameter 1000;
BA_ "GenSigTimeoutMsg_Gateway_PQ46_A" SG_ 916 LRZ_Parameter 916;
BA_ "GenSigSendType" SG_ 916 LRZ_Parameter 0;
BA_ "GenSigTimeoutTime_Gateway_PQ35_A" SG_ 916 LRZ_res_48 1000;
BA_ "GenSigTimeoutMsg_Gateway_PQ35_A" SG_ 916 LRZ_res_48 916;
BA_ "GenSigTimeoutTime_Gateway_PQ46_A" SG_ 916 LRZ_res_48 1000;
BA_ "GenSigTimeoutMsg_Gateway_PQ46_A" SG_ 916 LRZ_res_48 916;
BA_ "GenSigSendType" SG_ 916 LRZ_res_48 0;
BA_ "GenSigTimeoutTime_Gateway_PQ35_A" SG_ 916 LRZ_Tourist_Fkt 1000;
BA_ "GenSigTimeoutMsg_Gateway_PQ35_A" SG_ 916 LRZ_Tourist_Fkt 916;
BA_ "GenSigTimeoutTime_Gateway_PQ46_A" SG_ 916 LRZ_Tourist_Fkt 1000;
BA_ "GenSigTimeoutMsg_Gateway_PQ46_A" SG_ 916 LRZ_Tourist_Fkt 916;
BA_ "GenSigSendType" SG_ 916 LRZ_Tourist_Fkt 0;
BA_ "GenSigTimeoutTime_Gateway_PQ35_A" SG_ 916 LRZ_ELF_links 1000;
BA_ "GenSigTimeoutMsg_Gateway_PQ35_A" SG_ 916 LRZ_ELF_links 916;
BA_ "GenSigTimeoutTime_Gateway_PQ46_A" SG_ 916 LRZ_ELF_links 1000;
BA_ "GenSigTimeoutMsg_Gateway_PQ46_A" SG_ 916 LRZ_ELF_links 916;
BA_ "GenSigSendType" SG_ 916 LRZ_ELF_links 0;
BA_ "GenSigTimeoutTime_Gateway_PQ35_A" SG_ 916 LRZ_ELF_rechts 1000;
BA_ "GenSigTimeoutMsg_Gateway_PQ35_A" SG_ 916 LRZ_ELF_rechts 916;
BA_ "GenSigTimeoutTime_Gateway_PQ46_A" SG_ 916 LRZ_ELF_rechts 1000;
BA_ "GenSigTimeoutMsg_Gateway_PQ46_A" SG_ 916 LRZ_ELF_rechts 916;
BA_ "GenSigSendType" SG_ 916 LRZ_ELF_rechts 0;
BA_ "GenSigTimeoutTime_Gateway_PQ35_A" SG_ 916 LRZ_LeistDim 1000;
BA_ "GenSigTimeoutMsg_Gateway_PQ35_A" SG_ 916 LRZ_LeistDim 916;
BA_ "GenSigTimeoutTime_Gateway_PQ46_A" SG_ 916 LRZ_LeistDim 1000;
BA_ "GenSigTimeoutMsg_Gateway_PQ46_A" SG_ 916 LRZ_LeistDim 916;
BA_ "GenSigSendType" SG_ 916 LRZ_LeistDim 0;
BA_ "GenSigStartValue" SG_ 916 LRZ_LeistDim 254;
BA_ "GenSigTimeoutTime_Gateway_PQ35_A" SG_ 916 LRZ_AFSLED_Blink 1000;
BA_ "GenSigTimeoutMsg_Gateway_PQ35_A" SG_ 916 LRZ_AFSLED_Blink 916;
BA_ "GenSigTimeoutTime_Gateway_PQ46_A" SG_ 916 LRZ_AFSLED_Blink 1000;
BA_ "GenSigTimeoutMsg_Gateway_PQ46_A" SG_ 916 LRZ_AFSLED_Blink 916;
BA_ "GenSigSendType" SG_ 916 LRZ_AFSLED_Blink 0;
BA_ "GenSigTimeoutTime_Gateway_PQ35_A" SG_ 916 LRZ_AFSFehlertext 1000;
BA_ "GenSigTimeoutMsg_Gateway_PQ35_A" SG_ 916 LRZ_AFSFehlertext 916;
BA_ "GenSigTimeoutTime_Gateway_PQ46_A" SG_ 916 LRZ_AFSFehlertext 1000;
BA_ "GenSigTimeoutMsg_Gateway_PQ46_A" SG_ 916 LRZ_AFSFehlertext 916;
BA_ "GenSigSendType" SG_ 916 LRZ_AFSFehlertext 0;
BA_ "GenSigTimeoutTime_Gateway_PQ35_A" SG_ 916 LRZ_Zaehler 1000;
BA_ "GenSigTimeoutMsg_Gateway_PQ35_A" SG_ 916 LRZ_Zaehler 916;
BA_ "GenSigTimeoutTime_Gateway_PQ46_A" SG_ 916 LRZ_Zaehler 1000;
BA_ "GenSigTimeoutMsg_Gateway_PQ46_A" SG_ 916 LRZ_Zaehler 916;
BA_ "GenSigSendType" SG_ 916 LRZ_Zaehler 0;
BA_ "GenSigTimeoutTime_Gateway_PQ35_A" SG_ 916 LRZ_res_56 1000;
BA_ "GenSigTimeoutMsg_Gateway_PQ35_A" SG_ 916 LRZ_res_56 916;
BA_ "GenSigTimeoutTime_Gateway_PQ46_A" SG_ 916 LRZ_res_56 1000;
BA_ "GenSigTimeoutMsg_Gateway_PQ46_A" SG_ 916 LRZ_res_56 916;
BA_ "GenSigSendType" SG_ 916 LRZ_res_56 0;
BA_ "GenSigTimeoutTime_Gateway_PQ46_A" SG_ 916 LRZ_AFS_Absch 1000;
BA_ "GenSigTimeoutMsg_Gateway_PQ46_A" SG_ 916 LRZ_AFS_Absch 916;
BA_ "GenSigTimeoutTime_Gateway_PQ35_A" SG_ 916 LRZ_AFS_Absch 1000;
BA_ "GenSigTimeoutMsg_Gateway_PQ35_A" SG_ 916 LRZ_AFS_Absch 916;
BA_ "GenSigSendType" SG_ 916 LRZ_AFS_Absch 0;
BA_ "GenSigTimeoutTime_Gateway_PQ46_A" SG_ 916 LRZ_AFS_deaktiv 1000;
BA_ "GenSigTimeoutMsg_Gateway_PQ46_A" SG_ 916 LRZ_AFS_deaktiv 916;
BA_ "GenSigTimeoutTime_Gateway_PQ35_A" SG_ 916 LRZ_AFS_deaktiv 1000;
BA_ "GenSigTimeoutMsg_Gateway_PQ35_A" SG_ 916 LRZ_AFS_deaktiv 916;
BA_ "GenSigSendType" SG_ 916 LRZ_AFS_deaktiv 0;
BA_ "GenSigTimeoutTime_Gateway_PQ46_A" SG_ 916 LRZ_Tourist_aktiv 1000;
BA_ "GenSigTimeoutMsg_Gateway_PQ46_A" SG_ 916 LRZ_Tourist_aktiv 916;
BA_ "GenSigTimeoutTime_Gateway_PQ35_A" SG_ 916 LRZ_Tourist_aktiv 1000;
BA_ "GenSigTimeoutMsg_Gateway_PQ35_A" SG_ 916 LRZ_Tourist_aktiv 916;
BA_ "GenSigSendType" SG_ 916 LRZ_Tourist_aktiv 0;
BA_ "GenSigTimeoutTime_Hybrid_DQ200" SG_ 1096 WH1_Init 500;
BA_ "GenSigTimeoutMsg_Hybrid_DQ200" SG_ 1096 WH1_Init 1096;
BA_ "GenSigTimeoutTime_DQ" SG_ 1096 WH1_Init 500;
BA_ "GenSigTimeoutMsg_DQ" SG_ 1096 WH1_Init 1096;
BA_ "GenSigSendType" SG_ 1096 WH1_Init 0;
BA_ "GenSigStartValue" SG_ 1096 WH1_Init 1;
BA_ "GenSigTimeoutTime_Hybrid_DQ200" SG_ 1096 WH1_Position 500;
BA_ "GenSigTimeoutMsg_Hybrid_DQ200" SG_ 1096 WH1_Position 1096;
BA_ "GenSigTimeoutTime_DQ" SG_ 1096 WH1_Position 500;
BA_ "GenSigTimeoutMsg_DQ" SG_ 1096 WH1_Position 1096;
BA_ "GenSigSendType" SG_ 1096 WH1_Position 0;
BA_ "GenSigTimeoutTime_Hybrid_DQ200" SG_ 1096 WH1_StaShiftlock 500;
BA_ "GenSigTimeoutMsg_Hybrid_DQ200" SG_ 1096 WH1_StaShiftlock 1096;
BA_ "GenSigTimeoutTime_DQ" SG_ 1096 WH1_StaShiftlock 500;
BA_ "GenSigTimeoutMsg_DQ" SG_ 1096 WH1_StaShiftlock 1096;
BA_ "GenSigSendType" SG_ 1096 WH1_StaShiftlock 0;
BA_ "GenSigTimeoutTime_Hybrid_DQ200" SG_ 1096 WH1_Status 500;
BA_ "GenSigTimeoutMsg_Hybrid_DQ200" SG_ 1096 WH1_Status 1096;
BA_ "GenSigTimeoutTime_DQ" SG_ 1096 WH1_Status 500;
BA_ "GenSigTimeoutMsg_DQ" SG_ 1096 WH1_Status 1096;
BA_ "GenSigSendType" SG_ 1096 WH1_Status 0;
BA_ "GenSigTimeoutTime_Hybrid_DQ200" SG_ 1096 WH1_Testergebnis 500;
BA_ "GenSigTimeoutMsg_Hybrid_DQ200" SG_ 1096 WH1_Testergebnis 1096;
BA_ "GenSigTimeoutTime_DQ" SG_ 1096 WH1_Testergebnis 500;
BA_ "GenSigTimeoutMsg_DQ" SG_ 1096 WH1_Testergebnis 1096;
BA_ "GenSigSendType" SG_ 1096 WH1_Testergebnis 0;
BA_ "GenSigTimeoutTime_Hybrid_DQ200" SG_ 1096 WH1_Zaehler 500;
BA_ "GenSigTimeoutMsg_Hybrid_DQ200" SG_ 1096 WH1_Zaehler 1096;
BA_ "GenSigTimeoutTime_DQ" SG_ 1096 WH1_Zaehler 500;
BA_ "GenSigTimeoutMsg_DQ" SG_ 1096 WH1_Zaehler 1096;
BA_ "GenSigSendType" SG_ 1096 WH1_Zaehler 0;
BA_ "GenSigTimeoutTime_Hybrid_DQ200" SG_ 1096 WH1_Position_inv 500;
BA_ "GenSigTimeoutMsg_Hybrid_DQ200" SG_ 1096 WH1_Position_inv 1096;
BA_ "GenSigTimeoutTime_DQ" SG_ 1096 WH1_Position_inv 500;
BA_ "GenSigTimeoutMsg_DQ" SG_ 1096 WH1_Position_inv 1096;
BA_ "GenSigSendType" SG_ 1096 WH1_Position_inv 0;
BA_ "GenSigStartValue" SG_ 1096 WH1_Position_inv 15;
BA_ "GenSigSendType" SG_ 1096 WH1_Reserve2 0;
BA_ "GenSigSendType" SG_ 1096 WH1_Reserve1 0;
BA_ "GenSigTimeoutTime_Hybrid_DQ200" SG_ 1096 WH1_Test_Flag 500;
BA_ "GenSigTimeoutMsg_Hybrid_DQ200" SG_ 1096 WH1_Test_Flag 1096;
BA_ "GenSigTimeoutTime_DQ" SG_ 1096 WH1_Test_Flag 500;
BA_ "GenSigTimeoutMsg_DQ" SG_ 1096 WH1_Test_Flag 1096;
BA_ "GenSigSendType" SG_ 1096 WH1_Test_Flag 0;
VAL_ 1192 BR5_Giergeschw 16383 "Fehler" 16382 "ABS_only_System" 16381 "ASR_System" ;
VAL_ 1192 BR5_Bremsdruck 4095 "Fehler" ;
VAL_ 1192 BR5_Sign_Druck 1 "negativ" 0 "positiv" ;
VAL_ 1192 BR5_Vorzeichen 1 "negativ" 0 "positiv" ;
VAL_ 1192 BR5_Sta_Gierrate 1 "ungueltig" 0 "gueltig" ;
VAL_ 1192 BR5_Stillstand 1 "Stillstand_erkannt" 0 "kein_Stillstand_erkannt" ;
VAL_ 1192 BR5_Sta_Druck 1 "aktiver_Druckaufbau" 0 "kein_aktiver_Druckaufbau" ;
VAL_ 1192 BR5_TolAbgl_VR 255 "Fehler" 254 "Abgleich_nicht_genueg_konvergent" ;
VAL_ 1192 BR5_Anhi_akt 1 "aktiv" 0 "nicht_aktiv" ;
VAL_ 1192 BR5_Druckgueltig 1 "ungueltig" 0 "gueltig" ;
VAL_ 1192 BR5_ECD_Lampe 1 "ein" 0 "aus" ;
VAL_ 1192 BR5_AWV2_Bremsruck 1 "Bremsruck_wird_durchgefuehrt" 0 "kein_Bremsruck" ;
VAL_ 1192 BR5_Anhi_Sta 1 "Fehler" 0 "kein_Fehler" ;
VAL_ 1192 BR5_v_Ueberw 1 "ja" 0 "nein" ;
VAL_ 1192 BR5_AnhStabAktiv 1 "Bremslicht_an" 0 "keine_Bremslichtanforderung" ;
VAL_ 1192 BR5_Notbremsung 1 "Notbremsung_erk" 0 "keine_Notbremsung" ;
VAL_ 1192 BR5_AWV2_Fehler 1 "Fehler" 0 "kein_Fehler" ;
VAL_ 1192 BR5_ECD_Rueckfall 1 "Fehler_Drucksensor" 0 "i_O" ;
VAL_ 672 BR4_Vorgabe_Hi 255 "Fehler" 254 "Kupplung_schliessen_100_Prozent" 128 "Kupplung_oeffnen_0_Prozent" 127 "Kupplung_schnell_offen" ;
VAL_ 672 BR4_Einheit 2 "Nm_VAQ" 1 "Prozente" 0 "Nm_Haldex" ;
VAL_ 672 BR4_Vorgabe_Mi 255 "Fehler" 254 "Kupplung_schliessen_100_Prozent" 128 "Kupplung_oeffnen_0_Prozent" 127 "Kupplung_schnell_offen" ;
VAL_ 672 BR4_Abschaltung_HL 1 "EDS_HL_Temp_Absch" 0 "EDS_HL_i_O" ;
VAL_ 672 BR4_Vorgabe_Mi_ 255 "Fehler" 254 "Kupplung_ganz_schl" 127 "Kupplung_schnell_offen" 0 "keine_Vorgabe" ;
VAL_ 672 BR4_Abschaltung_HR 1 "EDS_HR_Temp_Absch" 0 "EDS_HR_i_O" ;
VAL_ 672 BR4_Abschaltung_VL 1 "EDS_VL_Temp_Absch" 0 "EDS_VL_i_O" ;
VAL_ 672 BR4_Abschaltung_VR 1 "EDS_VR_Temp_Absch" 0 "EDS_VR_i_O" ;
VAL_ 672 BR4_Lampe_RKA 1 "Lampe_ein" 0 "Lampe_aus" ;
VAL_ 672 BR4_Summer_RKA 1 "Summer_ein" 0 "Summer_aus" ;
VAL_ 672 BR4_Unterdruck 255 "Fehler" ;
VAL_ 672 BR4_Status_ESP 5 "AYC_Unterst_mo_regl_aktiv" 4 "ESP_Anf_VAQ" 3 "ESP_bereit" 2 "Kom_VAQ_gestoert" 1 "ESP_Fehlerstatus" 0 "VAQ_deaktiviert" ;
VAL_ 672 BR4_Schwelle 3 "U_Signal_temp_n_verf" 2 "Unterdruck_gr_450mbar" 1 "Unterdruck_klgl_450mbar" 0 "kein_Signal" ;
VAL_ 428 BR8_Laengsbeschl 1023 "Fehler" 0 "Init" ;
VAL_ 428 BR8_Sta_Br_Druck 1 "mit_Bremsdruck" 0 "Bremse_drucklos" ;
VAL_ 428 BR8_QB_LBeschl 1 "Ersatz_Init_Fehler" 0 "gueltiger_Wert" ;
VAL_ 428 BR8_Istbeschl 511 "Fehler" ;
VAL_ 428 BR8_Check_EPB 1 "plausibel" 0 "nicht_plausibel" ;
VAL_ 428 BR8_TolAbgl_HL 255 "Fehler" 254 "Abgl_nicht_genueg_konvrg" ;
VAL_ 428 BR8_TolAbgl_HR 255 "Fehler" 254 "Abgl_nicht_genueg_konvrg" ;
VAL_ 428 BR8_Sta_ADR_BR 1 "ACC_Botschaft_nicht_konsistent" 0 "ACC_Botschaft_konsistent" ;
VAL_ 428 BR8_Sta_Br_temp 1 "ueberhitzt" 0 "nicht_ueberhitzt" ;
VAL_ 428 BR8_Quattro 1 "Quattro" 0 "Front" ;
VAL_ 428 BR8_Sta_ACC_Anf 1 "aktiv" 0 "passiv" ;
VAL_ 428 BR8_Verz_EPB_akt 1 "aktiviert" 0 "nicht_aktiviert" ;
VAL_ 428 BR8_aktBrSyst 1 "ja" 0 "nein" ;
VAL_ 428 BR8_Sta_VerzReg 1 "nicht_funktionsfaehig" 0 "funktionsfaehig" ;
VAL_ 428 BR8_Fa_bremst 1 "Fahrer_bremst" 0 "Fahrer_bremst_nicht" ;
VAL_ 428 BR8_Sta_BLS 1 "Fehler" 0 "kein_Fehler" ;
VAL_ 428 BR8_StaBrSyst 1 "System_aktiv" 0 "Systemt_inaktiv" ;
VAL_ 428 BR8_ESC_Mode 3 "ESC_Mode_3" 2 "ESC_Mode_2" 1 "ESC_Mode_1" 0 "ESC_Mode_0" ;
VAL_ 428 BR8_Verz_EPB 1 "System_verfuegbar" 0 "nicht_verfuegbar" ;
VAL_ 428 BR8_Sta_HW_BLS 1 "Ausgang_defekt" 0 "Ausgang_iO" ;
VAL_ 1184 BR3_Rad_kmh_VR 32742 "Sensorfehler" 32725 "Unterspannung" 32708 "Init_PQ25_35_46" 32640 "Fehler_D1_BY" 0 "Init_Col_D1" ;
VAL_ 1184 BR3_Rad_kmh_VL 32742 "Sensorfehler" 32725 "Unterspannung" 32708 "Init_PQ25_35_46" 32640 "Fehler_D1_BY" 0 "Init_Col_D1" ;
VAL_ 1184 BR3_Rad_kmh_HR 32742 "Sensorfehler" 32725 "Unterspannung" 32708 "Init_PQ25_35_46" 32640 "Fehler_D1_BY" 0 "Init_Col_D1" ;
VAL_ 1184 BR3_Fahrtr_VL 1 "Rueckwaerts" 0 "Vorwaerts" ;
VAL_ 1184 BR3_Fahrtr_VR 1 "Rueckwaerts" 0 "Vorwaerts" ;
VAL_ 1184 BR3_Fahrtr_HR 1 "Rueckwaerts" 0 "Vorwaerts" ;
VAL_ 1184 BR3_Rad_kmh_HL 32742 "Sensorfehler" 32725 "Unterspannung" 32708 "Init_PQ25_35_46" 32640 "Fehler_D1_BY" 0 "Init_Col_D1" ;
VAL_ 1184 BR3_Fahrtr_HL 1 "Rueckwaerts" 0 "Vorwaerts" ;
VAL_ 174 BR9_LMOffSign 1 "neg_VZ" 0 "pos_VZ" ;
VAL_ 174 BR9_LWOffSign 1 "neg_VZ" 0 "pos_VZ" ;
VAL_ 174 BR9_Sta_DSR 7 "ext_MomLWeingriff_angef" 6 "ext_LWeingriff_angef" 5 "ext_Momeingriff_angef" 4 "offen" 3 "ESP_funktionsbereit" 2 "Kom_ESP_gestoert" 1 "DSR_Anf_nicht_ausfuehrbar" 0 "DSR_deaktiviert" ;
VAL_ 684 GS1_Rad_kmh 65433 "Ref_na" 65484 "Sensorfehler" 65450 "Unterspannung" 65416 "Init" ;
VAL_ 684 GS1_QBit_Rad_kmh 1 "Ersatz_Init_Fehler" 0 "gueltiger_Wert" ;
VAL_ 684 GS1_Fahrtrichtung 1 "Rueckwaerts" 0 "Vorwaerts" ;
VAL_ 928 B10_QB_Wegimp_VL 1 "Ersatz_Init_Fehlerwert" 0 "gueltiger_Wert" ;
VAL_ 928 B10_QB_Wegimp_VR 1 "Ersatz_Init_Fehlerwert" 0 "gueltiger_Wert" ;
VAL_ 928 B10_QB_Wegimp_HL 1 "Ersatz_Init_Fehlerwert" 0 "gueltiger_Wert" ;
VAL_ 928 B10_QB_Wegimp_HR 1 "Ersatz_Init_Fehlerwert" 0 "gueltiger_Wert" ;
VAL_ 928 B10_Wegimp_VL 1023 "Sensorfehler" 1022 "Unterspannung" 1021 "Initwert" ;
VAL_ 928 B10_Wegimp_VR 1023 "Sensorfehler" 1022 "Unterspannung" 1021 "Initwert" ;
VAL_ 928 B10_Wegimp_HL 1023 "Sensorfehler" 1022 "Unterspannung" 1021 "Initwert" ;
VAL_ 928 B10_Wegimp_HR 1023 "Sensorfehler" 1022 "Unterspannung" 1021 "Initwert" ;
VAL_ 928 B10_QB_Fahrtr_VL 1 "Ersatz_Init_Fehlerwert" 0 "gueltiger_Wert" ;
VAL_ 928 B10_QB_Fahrtr_HL 1 "Ersatz_Init_Fehlerwert" 0 "gueltiger_Wert" ;
VAL_ 928 B10_QB_Fahrtr_HR 1 "Ersatz_Init_Fehlerwert" 0 "gueltiger_Wert" ;
VAL_ 928 B10_Fahrtr_HL 1 "Rueckwaerts" 0 "Vorwaerts" ;
VAL_ 928 B10_Fahrtr_HR 1 "Rueckwaerts" 0 "Vorwaerts" ;
VAL_ 928 B10_QB_Fahrtr_VR 1 "Ersatz_Init_Fehlerwert" 0 "gueltiger_Wert" ;
VAL_ 928 B10_Fahrtr_VR 1 "Rueckwaerts" 0 "Vorwaerts" ;
VAL_ 928 B10_Fahrtr_VL 1 "Rueckwaerts" 0 "Vorwaerts" ;
VAL_ 1827 NMH_ABS_Abschaltstufe_aktiv 1 "Abschaltstufe_aktiv" ;
VAL_ 1827 NMH_ABS_Car_WakeUp 1 "Car_WakeUp" ;
VAL_ 1827 NMH_ABS_Eindraht_Fehler 1 "Eindrahtbetrieb_erkannt" ;
VAL_ 1827 NMH_ABS_Fkt_WakeUp 0 "Peripheriewakeup" ;
VAL_ 1827 NMH_ABS_kein_NL 1 "kein_Nachlauf" ;
VAL_ 1827 NMH_ABS_KompSchutz 1 "Komponentenschutz_aktiv" ;
VAL_ 1827 NMH_ABS_Mute_Mode 1 "Mute_Mode_aktiv" ;
VAL_ 1827 NMH_ABS_CAN_Diag_deaktiv 1 "keine_CANbez_Eigendiag" ;
VAL_ 1827 NMH_ABS_NL_aktiv_5 1 "Nachlaufursache_5" ;
VAL_ 1827 NMH_ABS_NL_aktiv_6 1 "Nachlaufursache_6" ;
VAL_ 1827 NMH_ABS_NL_aktiv_7 1 "Nachlaufursache_7" ;
VAL_ 1827 NMH_ABS_NL_aktiv_8 1 "Nachlaufursache_8" ;
VAL_ 1827 NMH_ABS_NM_aktiv_Diagnose 1 "Diagnose_bei_Kl_15_aus" ;
VAL_ 1827 NMH_ABS_NM_aktiv_Klemme_15 1 "Klemme_15_ein" ;
VAL_ 1827 NMH_ABS_NL_aktiv_4 1 "kein_FzgStillstand_erkannt" ;
VAL_ 1827 NMH_ABS_NM_aktiv_Start 1 "Mindestaktivzeit_START" ;
VAL_ 1827 NMH_ABS_Normal_Mode_1 1 "NORMAL_MODE_v_START" ;
VAL_ 1827 NMH_ABS_Normal_Mode_2 1 "NORMAL_MODE_v_READY_TO_SLEEP" ;
VAL_ 1827 NMH_ABS_Per_WakeUp 3 "KL_15_HW" 2 "P_Wakeup_Ursache_unbekannt" 1 "CAN" 0 "Funktionswakeup" ;
VAL_ 1827 NMH_ABS_TimeOut_Fehler 1 "Timeout_Fehlereintrag" ;
VAL_ 1827 NMH_ABS_Transport_Mode 1 "Transport_Mode_aktiv" ;
VAL_ 1827 NMH_ABS_Start_1 1 "START_v_SLEEP" ;
VAL_ 1827 NMH_ABS_Start_2 1 "START_v_PREP_TO_SLEEP" ;
VAL_ 1463 B11_Br_StSt_Info 3 "Systemfehler" 2 "Motoranlauf_notw" 1 "Stoppverbot_Motoranl_nn" 0 "Motorlauf_nn" ;
VAL_ 1463 B11_OBD_Nib_VL 15 "frei" 14 "frei" 13 "frei" 12 "frei" 11 "KS_MP_OC" 10 "KS_MP" 9 "KS_M_OC" 8 "KS_P_OC" 7 "RC_M" 6 "RC_P" 5 "OOR_M" 4 "OOR_P" 3 "OC" 2 "KS_P" 1 "KS_M" 0 "kein_Fehler" ;
VAL_ 1463 B11_OBD_Nib_VR 15 "frei" 14 "frei" 13 "frei" 12 "frei" 11 "KS_MP_OC" 10 "KS_MP" 9 "KS_M_OC" 8 "KS_P_OC" 7 "RC_M" 6 "RC_P" 5 "OOR_M" 4 "OOR_P" 3 "OC" 2 "KS_P" 1 "KS_M" 0 "kein_Fehler" ;
VAL_ 1463 B11_OBD_Nib_HL 15 "frei" 14 "frei" 13 "frei" 12 "frei" 11 "KS_MP_OC" 10 "KS_MP" 9 "KS_M_OC" 8 "KS_P_OC" 7 "RC_M" 6 "RC_P" 5 "OOR_M" 4 "OOR_P" 3 "OC" 2 "KS_P" 1 "KS_M" 0 "kein_Fehler" ;
VAL_ 1463 B11_OBD_Nib_HR 15 "frei" 14 "frei" 13 "frei" 12 "frei" 11 "KS_MP_OC" 10 "KS_MP" 9 "KS_M_OC" 8 "KS_P_OC" 7 "RC_M" 6 "RC_P" 5 "OOR_M" 4 "OOR_P" 3 "OC" 2 "KS_P" 1 "KS_M" 0 "kein_Fehler" ;
VAL_ 1463 B11_HydHalten 1 "Fzg_wird_hydr_gehalten" 0 "Fzg_wird_nicht_hydr_gehalten" ;
VAL_ 1463 B11_EPB_Steller_akt 1 "EPB_Steller_verfaehrt" 0 "EPB_Steller_verfaehrt_nicht" ;
VAL_ 1463 B11_EPB_Steller_gue 1 "EPB_Steller_Info_gueltig" 0 "EPB_Steller_Info_ungueltig" ;
VAL_ 194 LW1_LRW_Sign 1 "negativer_Lenkradwinkel" 0 "positver_Lenkradwinkel" ;
VAL_ 194 LW1_Gesch_Sign 1 "neg_Lenkradwinkelgeschw" 0 "pos_Lenkradwinkelgeschw" ;
VAL_ 194 LW1_ID 128 "kalibriert" 0 "noch_nicht_kalibriert" ;
VAL_ 194 LW1_Initquelle 1 "EPS_Bit" 0 "Bremse_3" ;
VAL_ 194 LW1_Status 3 "dauerhafter_Fehler" 2 "sporadischer_Fehler" 1 "no_init" 0 "ok" ;
VAL_ 194 LW1_Sta_KL30 1 "no_init_s" 0 "ok" ;
VAL_ 916 LRZ_Grundeinst 1 "Grundeinstellung_erfolgt" 0 "Grundeinstellung_nicht_erfolgt" ;
VAL_ 916 LRZ_Initlauf 1 "Initialisierungslauf_erfolgt" 0 "Initlauf_nicht_erfolgt" ;
VAL_ 916 LRZ_Einfedg_hi 255 "Fehler" 254 "nicht_initialisiert" 127 "entspr_NN" ;
VAL_ 916 LRZ_Fehlerlampe 1 "LWR_Fehlerlampe_ein" 0 "LWR_Fehlerlampe_aus" ;
VAL_ 916 LRZ_Einfedg_vo 255 "Fehler" 254 "nicht_initialisiert" 127 "entspr_NN" ;
VAL_ 916 LRZ_Sichere_Pos 1 "Sicherheitsposition_ein" 0 "Sicherheitsposition_aus" ;
VAL_ 916 LRZ_Stellung 255 "Fehler" 254 "Init" ;
VAL_ 916 LRZ_Fehler 1 "Fehlerspeichereintrag" 0 "kein_Fehlerspeichereintrag" ;
VAL_ 916 LRZ_Modus 1 "LWR_dynamisch" 0 "LWR_statisch" ;
VAL_ 916 LRZ_LampeAFS 1 "AFS_Fehlerlampe_ein" 0 "AFS_Fehlerlampe_aus" ;
VAL_ 916 LRZ_Parameter 1 "Parametrisierung_erfolgt" 0 "Parametrisierung_nicht_erfolgt" ;
VAL_ 916 LRZ_Tourist_Fkt 1 "Tourist_Fkt_unterstuetzt" 0 "Tourist_Fkt_n_unterstuetzt" ;
VAL_ 916 LRZ_ELF_links 1 "Ersatzlichtfunktion" 0 "keine_Ersatzlichtfunktion" ;
VAL_ 916 LRZ_ELF_rechts 1 "Ersatzlichtfunktion" 0 "keine_Ersatzlichtfunktion" ;
VAL_ 916 LRZ_LeistDim 255 "Fehler" 254 "Wert_unbekannt" ;
VAL_ 916 LRZ_AFSLED_Blink 1 "ja" 0 "nein" ;
VAL_ 916 LRZ_AFSFehlertext 1 "Text_AFS_ohne_Funktion" 0 "kein_Text" ;
VAL_ 916 LRZ_AFS_Absch 1 "AFS_Deaktiv_unterstuetzt" 0 "keine_AFS_Deaktiv_n_unterst" ;
VAL_ 916 LRZ_AFS_deaktiv 1 "AFS_deaktiv" 0 "AFS_aktiv" ;
VAL_ 916 LRZ_Tourist_aktiv 1 "Tourist_Fkt_aktiv" 0 "Tourist_Fkt_deaktiv" ;
VAL_ 1096 WH1_Init 1 "Initphase" 0 "keine_Initphase" ;
VAL_ 1096 WH1_Position 15 "Fehler" 14 "Tipp_Gasse" 13 "Position_L" 12 "Position_S_Sport" 11 "Position_Tipp_minus" 10 "Position_Tipp_plus" 9 "Position_N_ohne_Spotausl" 8 "Position_P_Stop" 7 "Position_R" 6 "Position_N" 5 "Position_D" 4 "Position_4" 3 "Position_3" 2 "Position_2" 1 "Position_1" ;
VAL_ 1096 WH1_StaShiftlock 7 "Shiftlock_ist_fehlerhaft" 6 "nicht_verbaut" 3 "Shiftlock_ist_aktiviert" 2 "Shiftlock_ist_deaktiviert" 0 "Initwert" ;
VAL_ 1096 WH1_Status 0 "fehlerfrei" ;
VAL_ 1096 WH1_Test_Flag 1 "Testergebnis_gueltig" 0 "Testergebnis_ungueltig" ;
